VERSION "PMZ_HSCAN"

NS_ :

BS_:

BU_: BCM_Gp BECM CCF_Server EPICD EPICD_E GWM HVAC PCM SGCM TSTR Virtual_Node

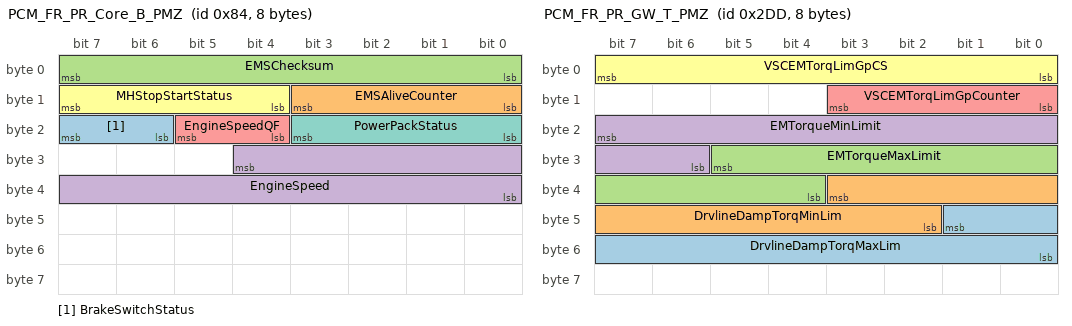
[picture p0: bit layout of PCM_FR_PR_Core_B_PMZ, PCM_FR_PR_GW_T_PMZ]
BO_ 132 PCM_FR_PR_Core_B_PMZ: 8 GWM
 SG_ BrakeSwitchStatus : 23|2@0+ (1,0) [0|3] "" Vector__XXX
 SG_ EMSAliveCounter : 11|4@0+ (1,0) [0|15] "Counter value" Vector__XXX
 SG_ EMSChecksum : 7|8@0+ (1,0) [0|255] "checksum" Vector__XXX
 SG_ EngineSpeed : 28|13@0+ (1,0) [0|8191] "RPM" Vector__XXX
 SG_ EngineSpeedQF : 21|2@0+ (1,0) [0|3] "" Vector__XXX
 SG_ MHStopStartStatus : 15|4@0+ (1,0) [0|15] "" Vector__XXX
 SG_ PowerPackStatus : 19|4@0+ (1,0) [0|15] "" Vector__XXX

BO_ 733 PCM_FR_PR_GW_T_PMZ: 8 GWM
 SG_ DrvlineDampTorqMaxLim : 41|10@0+ (0.1,0) [0|102.3] "Nm"  SGCM
 SG_ DrvlineDampTorqMinLim : 35|10@0+ (0.1,-102.3) [-102.3|1.4211E-014] "Nm"  SGCM
 SG_ EMTorqueMaxLimit : 29|10@0+ (1,0) [0|1021] "Nm"  SGCM
 SG_ EMTorqueMinLimit : 23|10@0+ (1,-1021) [-1021|0] "Nm"  SGCM
 SG_ VSCEMTorqLimGpCounter : 11|4@0+ (1,0) [0|15] "Counter value"  SGCM
 SG_ VSCEMTorqLimGpCS : 7|8@0+ (1,0) [0|255] "checksum"  SGCM

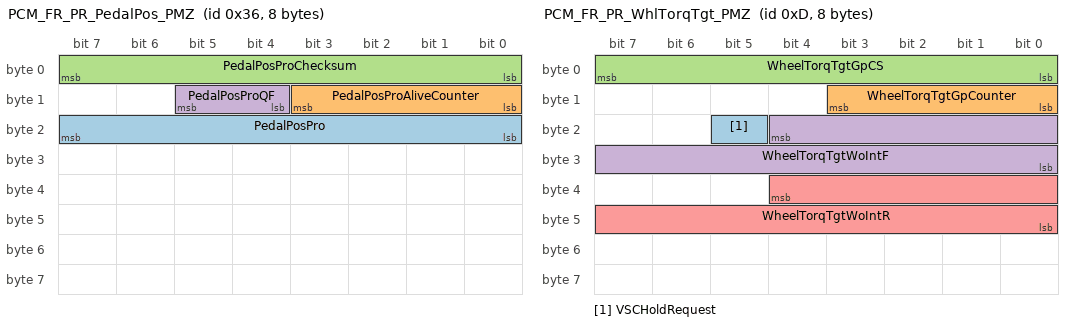
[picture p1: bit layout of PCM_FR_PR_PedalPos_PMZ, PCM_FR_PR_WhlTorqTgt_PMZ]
BO_ 54 PCM_FR_PR_PedalPos_PMZ: 8 GWM
 SG_ PedalPosPro : 23|8@0+ (0.5,0) [0|100] "%"  BECM
 SG_ PedalPosProAliveCounter : 11|4@0+ (1,0) [0|15] "Counter value" Vector__XXX
 SG_ PedalPosProChecksum : 7|8@0+ (1,0) [0|255] "checksum" Vector__XXX
 SG_ PedalPosProQF : 13|2@0+ (1,0) [0|3] "" Vector__XXX

BO_ 13 PCM_FR_PR_WhlTorqTgt_PMZ: 8 GWM
 SG_ VSCHoldRequest : 21|1@0+ (1,0) [0|1] "" Vector__XXX
 SG_ WheelTorqTgtGpCounter : 11|4@0+ (1,0) [0|15] "Counter value" Vector__XXX
 SG_ WheelTorqTgtGpCS : 7|8@0+ (1,0) [0|255] "checksum" Vector__XXX
 SG_ WheelTorqTgtWoIntF : 20|13@0+ (10,-10000) [-10000|71910] "Nm" Vector__XXX
 SG_ WheelTorqTgtWoIntR : 36|13@0+ (10,-10000) [-10000|71910] "Nm" Vector__XXX

BO_ 853 PCM_PMZ_BISGCalibration: 8 PCM
 SG_ BISGCalibrationIDReq : 63|1@0+ (1,0) [0|1] ""  SGCM

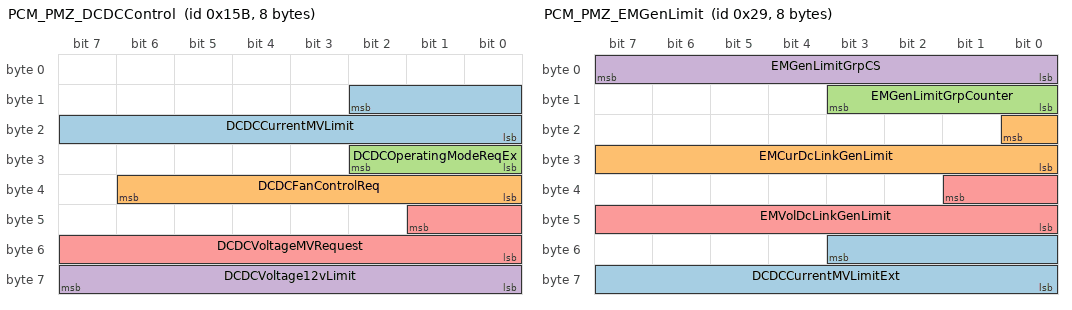
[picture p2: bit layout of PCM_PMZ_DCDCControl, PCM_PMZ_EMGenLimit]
BO_ 347 PCM_PMZ_DCDCControl: 8 PCM
 SG_ DCDCCurrentMVLimit : 10|11@0+ (0.1,-102.35) [-102.35|102.35] "Amps"  EPICD,EPICD_E
 SG_ DCDCFanControlReq : 38|7@0+ (1,0) [0|100] "%"  EPICD,EPICD_E
 SG_ DCDCOperatingModeReqEx : 26|3@0+ (1,0) [0|7] ""  EPICD,EPICD_E,GWM
 SG_ DCDCVoltage12vLimit : 63|8@0+ (0.1,0) [0|25.3] "Volts" Vector__XXX
 SG_ DCDCVoltageMVRequest : 41|10@0+ (0.1,0) [0|102.1] "Volts"  EPICD,EPICD_E

BO_ 41 PCM_PMZ_EMGenLimit: 8 PCM
 SG_ DCDCCurrentMVLimitExt : 51|12@0+ (0.1,-150) [-150|259.5] "Amps"  EPICD_E
 SG_ EMCurDcLinkGenLimit : 16|9@0+ (1,-509) [-509|0] "Amps"  SGCM
 SG_ EMGenLimitGrpCounter : 11|4@0+ (1,0) [0|15] "Counter value"  SGCM
 SG_ EMGenLimitGrpCS : 7|8@0+ (1,0) [0|255] "checksum"  SGCM
 SG_ EMVolDcLinkGenLimit : 33|10@0+ (1,0) [0|1021] "Volts"  SGCM

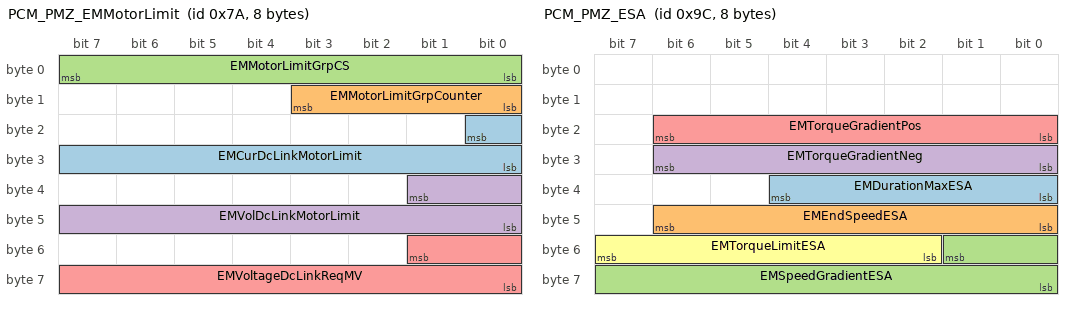
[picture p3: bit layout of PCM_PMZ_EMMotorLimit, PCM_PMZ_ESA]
BO_ 122 PCM_PMZ_EMMotorLimit: 8 PCM
 SG_ EMCurDcLinkMotorLimit : 16|9@0+ (1,0) [0|509] "Amps"  SGCM
 SG_ EMMotorLimitGrpCounter : 11|4@0+ (1,0) [0|15] "Counter value"  SGCM
 SG_ EMMotorLimitGrpCS : 7|8@0+ (1,0) [0|255] "checksum"  SGCM
 SG_ EMVolDcLinkMotorLimit : 33|10@0+ (1,0) [0|1021] "Volts"  SGCM
 SG_ EMVoltageDcLinkReqMV : 49|10@0+ (0.1,0) [0|102.3] "Volts"  SGCM

BO_ 156 PCM_PMZ_ESA: 8 PCM
 SG_ EMDurationMaxESA : 36|5@0+ (0.1,0) [0|3.1] "s"  SGCM
 SG_ EMEndSpeedESA : 46|7@0+ (10,0) [0|1270] "rpm"  SGCM
 SG_ EMSpeedGradientESA : 49|10@0+ (-10,0) [-10230|0] "rpm/s"  SGCM
 SG_ EMTorqueGradientNeg : 30|7@0+ (-10,0) [-1270|0] "Nm/s"  SGCM
 SG_ EMTorqueGradientPos : 22|7@0+ (10,0) [0|1270] "Nm/s"  SGCM
 SG_ EMTorqueLimitESA : 55|6@0+ (-1,0) [-63|0] "Nm"  SGCM

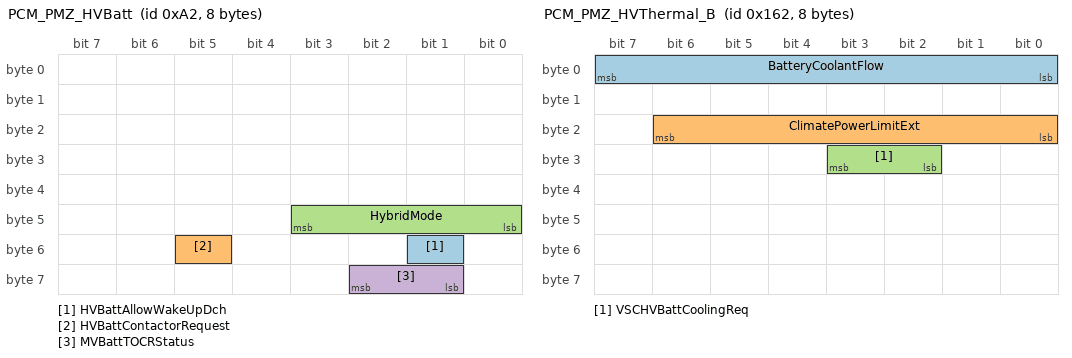
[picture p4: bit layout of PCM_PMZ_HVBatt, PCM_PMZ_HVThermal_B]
BO_ 162 PCM_PMZ_HVBatt: 8 PCM
 SG_ HVBattAllowWakeUpDch : 49|1@0+ (1,0) [0|1] "" Vector__XXX
 SG_ HVBattContactorRequest : 53|1@0+ (1,0) [0|1] ""  BECM,EPICD,EPICD_E
 SG_ HybridMode : 43|4@0+ (1,0) [0|15] ""  BCM_Gp
 SG_ MVBattTOCRStatus : 58|2@0+ (1,0) [0|3] ""  BECM

BO_ 352 PCM_PMZ_HVThermal_A: 8 PCM
 SG_ MVBattFanControlReq : 6|7@0+ (1,0) [0|100] "%"  BECM

BO_ 354 PCM_PMZ_HVThermal_B: 8 PCM
 SG_ BatteryCoolantFlow : 7|8@0+ (0.2,0) [0|51] "l/min"  BECM
 SG_ ClimatePowerLimitExt : 22|7@0+ (0.25,0) [0|31.75] "kW"  HVAC
 SG_ VSCHVBattCoolingReq : 27|2@0+ (1,0) [0|3] ""  HVAC

BO_ 743 PCM_PMZ_MVBattDiagnostics: 8 PCM
 SG_ MVBattCalibrationIDReq : 56|1@0+ (1,0) [0|1] ""  BECM
 SG_ MVBattCalibrationIDReq_UB : 57|1@0+ (1,0) [0|1] ""  BECM

BO_ 304 PCM_PMZ_PR_GW_1: 8 PCM
 SG_ eDriveCoolantLevel : 28|1@0+ (1,0) [0|1] ""  GWM,HVAC

BO_ 356 PCM_PMZ_PumpStatus: 8 PCM
 SG_ HVBattPumpDRReq : 38|7@0+ (1,0) [0|100] "%"  EPICD_E,GWM

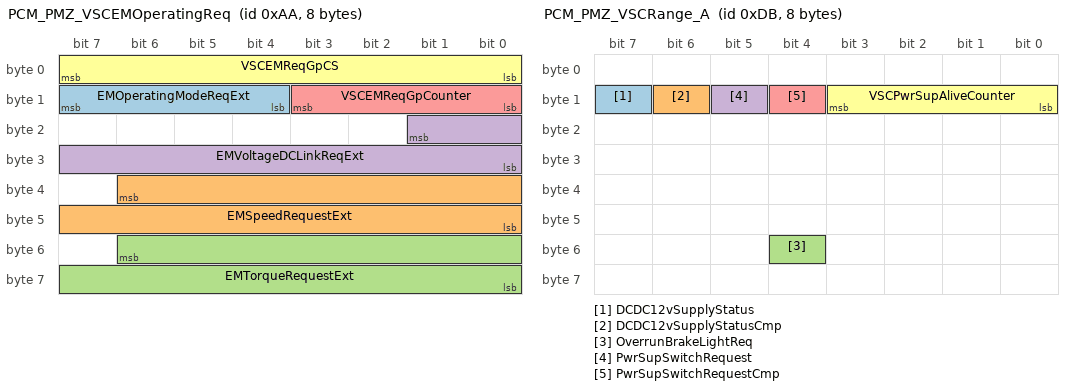
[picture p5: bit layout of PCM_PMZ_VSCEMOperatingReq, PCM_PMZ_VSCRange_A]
BO_ 170 PCM_PMZ_VSCEMOperatingReq: 8 GWM
 SG_ EMOperatingModeReqExt : 15|4@0+ (1,0) [0|15] ""  SGCM
 SG_ EMSpeedRequestExt : 38|15@0+ (1,-16382) [-16382|16383] "rpm"  SGCM
 SG_ EMTorqueRequestExt : 54|15@0+ (0.1,-1638.3) [-1638.3|1638.4] "Nm"  SGCM
 SG_ EMVoltageDCLinkReqExt : 17|10@0+ (1,0) [0|1021] "Volts"  EPICD,EPICD_E,SGCM
 SG_ VSCEMReqGpCounter : 11|4@0+ (1,0) [0|15] "Counter value"  SGCM
 SG_ VSCEMReqGpCS : 7|8@0+ (1,0) [0|255] "checksum"  SGCM

BO_ 219 PCM_PMZ_VSCRange_A: 8 PCM
 SG_ DCDC12vSupplyStatus : 15|1@0+ (1,0) [0|1] ""  GWM
 SG_ DCDC12vSupplyStatusCmp : 14|1@0+ (1,0) [0|1] ""  GWM
 SG_ OverrunBrakeLightReq : 52|1@0+ (1,0) [0|1] ""  BCM_Gp
 SG_ PwrSupSwitchRequest : 13|1@0+ (1,0) [0|1] ""  GWM
 SG_ PwrSupSwitchRequestCmp : 12|1@0+ (1,0) [0|1] ""  GWM
 SG_ VSCPwrSupAliveCounter : 11|4@0+ (1,0) [0|15] "Counter value"  GWM

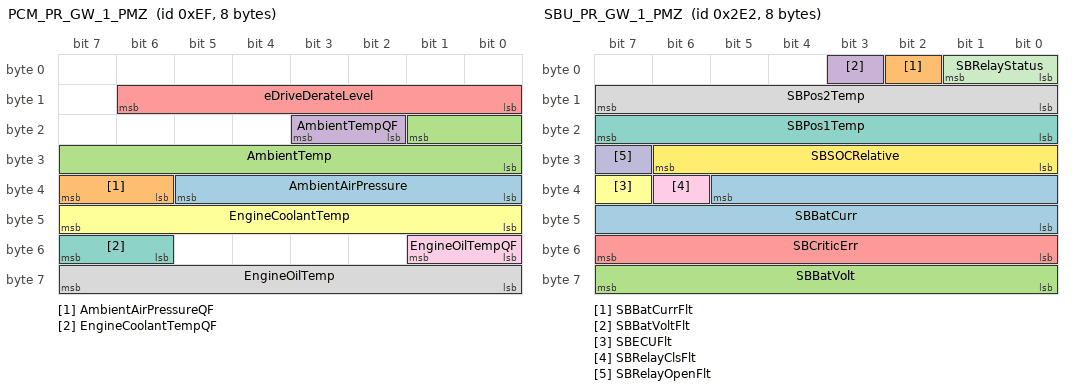
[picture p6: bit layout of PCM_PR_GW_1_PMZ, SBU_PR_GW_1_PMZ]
BO_ 239 PCM_PR_GW_1_PMZ: 8 GWM
 SG_ AmbientAirPressure : 37|6@0+ (10,500) [500|1100] "mBAR" Vector__XXX
 SG_ AmbientAirPressureQF : 39|2@0+ (1,0) [0|3] "" Vector__XXX
 SG_ AmbientTemp : 17|10@0+ (0.25,-128) [-128|127.75] "Degrees C"  EPICD,EPICD_E
 SG_ AmbientTempQF : 19|2@0+ (1,0) [0|3] "" Vector__XXX
 SG_ eDriveDerateLevel : 14|7@0+ (1,0) [0|100] "%" Vector__XXX
 SG_ EngineCoolantTemp : 47|8@0+ (1,-60) [-60|195] "deg C" Vector__XXX
 SG_ EngineCoolantTempQF : 55|2@0+ (1,0) [0|3] "" Vector__XXX
 SG_ EngineOilTemp : 63|8@0+ (1,-60) [-60|195] "deg C" Vector__XXX
 SG_ EngineOilTempQF : 49|2@0+ (1,0) [0|3] "" Vector__XXX

BO_ 1442 PMZ_CAN_NodeBECM_NM: 8 BECM
 SG_ PMZ_CAN_BECM_NM_PDU : 7|64@0+ (1,0) [0|0] "" Vector__XXX

BO_ 1438 PMZ_CAN_NodeGWM_NM: 8 GWM
 SG_ PMZ_CAN_GWM_NM_PDU : 7|64@0+ (1,0) [0|0] ""  BECM,EPICD_E,HVAC,PCM,SGCM,Virtual_Node

BO_ 1310 PMZ_CAN_NodeGWM_OSEK_NM: 8 GWM
 SG_ PMZ_CAN_GWM_OSEK_NM_Pdu : 7|64@0+ (1,0) [0|0] ""  Virtual_Node

BO_ 1411 PMZ_CAN_NodeHVAC_NM: 8 HVAC
 SG_ PMZ_CAN_HVAC_NM_PDU : 7|64@0+ (1,0) [0|0] ""  GWM

BO_ 1429 PMZ_CAN_NodePCM_NM: 8 PCM
 SG_ PMZ_CAN_PCM_NM_PDU : 7|64@0+ (1,0) [0|0] "" Vector__XXX

BO_ 1428 PMZ_CAN_NodeSGCM_NM: 8 SGCM
 SG_ PMZ_CAN_SGCM_NM_PDU : 7|64@0+ (1,0) [0|0] "" Vector__XXX

BO_ 1535 PMZ_CAN_NodeVirtual_NM: 8 Virtual_Node
 SG_ PMZ_CAN_Virtual_NM_PDU : 7|64@0+ (1,0) [0|0] "" Vector__XXX

BO_ 1407 PMZ_CAN_NodeVirtual_OSEK_NM: 8 Virtual_Node
 SG_ PMZ_CAN_Virtual_OSEK_NM_Pdu : 7|64@0+ (1,0) [0|0] ""  GWM

BO_ 562 PNC_TCUtoBMCM1: 8 GWM
 SG_ PNC_TCUtoBMCM1_Pdu : 7|64@0+ (1,0) [0|0] "" Vector__XXX

BO_ 712 PNC_TCUtoBMCM10: 8 GWM
 SG_ PNC_TCUtoBMCM10_Pdu : 7|64@0+ (1,0) [0|0] "" Vector__XXX

BO_ 707 PNC_TCUtoBMCM11: 8 GWM
 SG_ PNC_TCUtoBMCM11_Pdu : 7|64@0+ (1,0) [0|0] "" Vector__XXX

BO_ 708 PNC_TCUtoBMCM12: 8 GWM
 SG_ PNC_TCUtoBMCM12_Pdu : 7|64@0+ (1,0) [0|0] "" Vector__XXX

BO_ 711 PNC_TCUtoBMCM13: 8 GWM
 SG_ PNC_TCUtoBMCM13_Pdu : 7|64@0+ (1,0) [0|0] "" Vector__XXX

BO_ 565 PNC_TCUtoBMCM2: 8 GWM
 SG_ PNC_TCUtoBMCM2_Pdu : 7|64@0+ (1,0) [0|0] "" Vector__XXX

BO_ 569 PNC_TCUtoBMCM3: 8 GWM
 SG_ PNC_TCUtoBMCM3_Pdu : 7|64@0+ (1,0) [0|0] "" Vector__XXX

BO_ 573 PNC_TCUtoBMCM4: 8 GWM
 SG_ PNC_TCUtoBMCM4_Pdu : 7|64@0+ (1,0) [0|0] "" Vector__XXX

BO_ 579 PNC_TCUtoBMCM5: 8 GWM
 SG_ PNC_TCUtoBMCM5_Pdu : 7|64@0+ (1,0) [0|0] "" Vector__XXX

BO_ 594 PNC_TCUtoBMCM6: 8 GWM
 SG_ PNC_TCUtoBMCM6_Pdu : 7|64@0+ (1,0) [0|0] "" Vector__XXX

BO_ 709 PNC_TCUtoBMCM8: 8 GWM
 SG_ PNC_TCUtoBMCM8_Pdu : 7|64@0+ (1,0) [0|0] "" Vector__XXX

BO_ 710 PNC_TCUtoBMCM9: 8 GWM
 SG_ PNC_TCUtoBMCM9_Pdu : 7|64@0+ (1,0) [0|0] "" Vector__XXX

BO_ 191 RCM_FR_PR_GW_1_PMZ: 8 GWM
 SG_ CrashAirbagStatus : 63|2@0+ (1,0) [0|3] "" Vector__XXX
 SG_ CrashOccClassStatus : 61|2@0+ (1,0) [0|3] "" Vector__XXX
 SG_ CrashPACOSSwitchState : 59|2@0+ (1,0) [0|3] "" Vector__XXX
 SG_ CrashPretensionerStat : 57|2@0+ (1,0) [0|3] "" Vector__XXX
 SG_ CrashSeatBeltBcklState : 55|2@0+ (1,0) [0|3] "" Vector__XXX
 SG_ CrashSeverityClass : 53|2@0+ (1,0) [0|3] "" Vector__XXX
 SG_ CrashSideAirbagStatus : 51|2@0+ (1,0) [0|3] "" Vector__XXX
 SG_ CrashStatusPIE : 42|1@0+ (1,0) [0|1] "" Vector__XXX
 SG_ CrashStatusRCM : 43|1@0+ (1,0) [0|1] ""  BECM,EPICD,EPICD_E,SGCM
 SG_ CrashTypeFront : 49|1@0+ (1,0) [0|1] "" Vector__XXX
 SG_ CrashTypeRear : 48|1@0+ (1,0) [0|1] "" Vector__XXX
 SG_ CrashTypeRoll : 40|1@0+ (1,0) [0|1] "" Vector__XXX
 SG_ CrashTypeSide : 41|1@0+ (1,0) [0|1] "" Vector__XXX
 SG_ DrivSeatBeltBcklError : 30|1@0+ (1,0) [0|1] "" Vector__XXX
 SG_ DrivSeatBeltBcklState : 31|1@0+ (1,0) [0|1] "" Vector__XXX
 SG_ DrivSeatPositionError : 47|1@0+ (1,0) [0|1] "" Vector__XXX
 SG_ DrivSeatPositionStatus : 46|1@0+ (1,0) [0|1] "" Vector__XXX
 SG_ KeepNetInAfterRunRCM : 44|1@0+ (1,0) [0|1] "" Vector__XXX
 SG_ PassSeatBeltBcklError : 28|1@0+ (1,0) [0|1] "" Vector__XXX
 SG_ PassSeatBeltBcklState : 29|1@0+ (1,0) [0|1] "" Vector__XXX
 SG_ PassSeatPositionStatus : 45|1@0+ (1,0) [0|1] "" Vector__XXX
 SG_ SeatBeltBcklAC : 11|4@0+ (1,0) [0|15] "Counter value" Vector__XXX
 SG_ SeatBeltBcklCS : 7|8@0+ (1,0) [0|255] "checksum" Vector__XXX
 SG_ TriggerEventRCM : 16|1@0+ (1,0) [0|1] "" Vector__XXX
 SG_ VerticalAcceleration : 27|12@0+ (0.02,-40.96) [-40.96|40.92] "m/s/s" Vector__XXX

BO_ 738 SBU_PR_GW_1_PMZ: 8 GWM
 SG_ SBBatCurr : 37|14@0+ (0.0625,-511) [-511|512.9375] "A" Vector__XXX
 SG_ SBBatCurrFlt : 2|1@0+ (1,0) [0|1] "" Vector__XXX
 SG_ SBBatVolt : 63|8@0+ (0.1,0) [0|25.5] "V"  HVAC
 SG_ SBBatVoltFlt : 3|1@0+ (1,0) [0|1] "" Vector__XXX
 SG_ SBCriticErr : 55|8@0+ (1,0) [0|255] "" Vector__XXX
 SG_ SBECUFlt : 39|1@0+ (1,0) [0|1] "" Vector__XXX
 SG_ SBPos1Temp : 23|8@0+ (1,-40) [-40|215] "degC" Vector__XXX
 SG_ SBPos2Temp : 15|8@0+ (1,-40) [-40|215] "degC" Vector__XXX
 SG_ SBRelayClsFlt : 38|1@0+ (1,0) [0|1] "" Vector__XXX
 SG_ SBRelayOpenFlt : 31|1@0+ (1,0) [0|1] "" Vector__XXX
 SG_ SBRelayStatus : 1|2@0+ (1,0) [0|3] "" Vector__XXX
 SG_ SBSOCRelative : 30|7@0+ (1,0) [0|100] "%" Vector__XXX

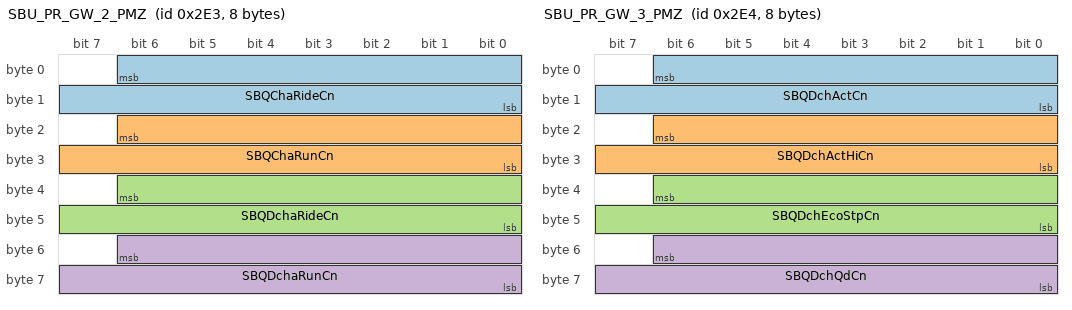
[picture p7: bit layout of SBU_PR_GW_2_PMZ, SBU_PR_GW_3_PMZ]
BO_ 739 SBU_PR_GW_2_PMZ: 8 GWM
 SG_ SBQChaRideCn : 6|15@0+ (0.0625,0) [0|2047.9375] "Cn" Vector__XXX
 SG_ SBQChaRunCn : 22|15@0+ (0.0625,0) [0|2047.9375] "Cn" Vector__XXX
 SG_ SBQDchaRideCn : 38|15@0+ (0.0625,0) [0|2047.9375] "Cn" Vector__XXX
 SG_ SBQDchaRunCn : 54|15@0+ (0.0625,0) [0|2047.9375] "Cn" Vector__XXX

BO_ 740 SBU_PR_GW_3_PMZ: 8 GWM
 SG_ SBQDchActCn : 6|15@0+ (0.0625,0) [0|2047.9375] "Cn" Vector__XXX
 SG_ SBQDchActHiCn : 22|15@0+ (0.0625,0) [0|2047.9375] "Cn" Vector__XXX
 SG_ SBQDchEcoStpCn : 38|15@0+ (0.0625,0) [0|2047.9375] "Cn" Vector__XXX
 SG_ SBQDchQdCn : 54|15@0+ (0.01,0) [0|327.67] "Cn" Vector__XXX

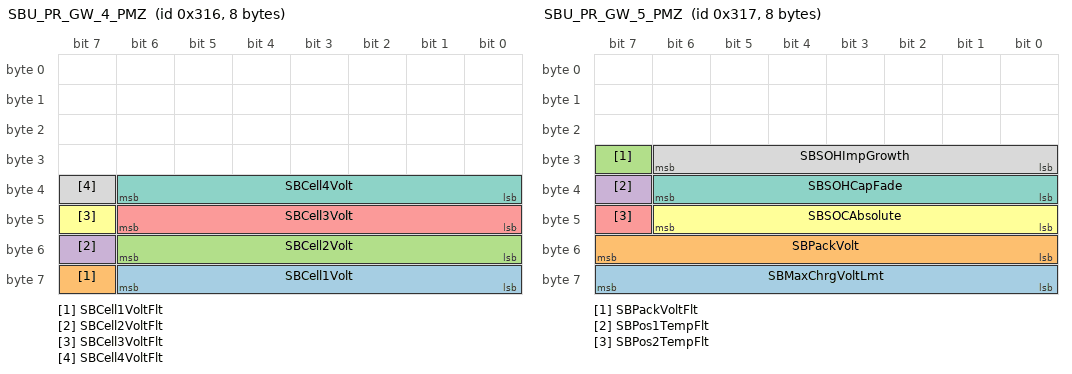
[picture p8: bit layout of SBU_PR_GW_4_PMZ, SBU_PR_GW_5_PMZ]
BO_ 790 SBU_PR_GW_4_PMZ: 8 GWM
 SG_ SBCell1Volt : 62|7@0+ (0.05,0) [0|6.35] "V" Vector__XXX
 SG_ SBCell1VoltFlt : 63|1@0+ (1,0) [0|1] "" Vector__XXX
 SG_ SBCell2Volt : 54|7@0+ (0.05,0) [0|6.35] "V" Vector__XXX
 SG_ SBCell2VoltFlt : 55|1@0+ (1,0) [0|1] "" Vector__XXX
 SG_ SBCell3Volt : 46|7@0+ (0.05,0) [0|6.35] "V" Vector__XXX
 SG_ SBCell3VoltFlt : 47|1@0+ (1,0) [0|1] "" Vector__XXX
 SG_ SBCell4Volt : 38|7@0+ (0.05,0) [0|6.35] "V" Vector__XXX
 SG_ SBCell4VoltFlt : 39|1@0+ (1,0) [0|1] "" Vector__XXX

BO_ 791 SBU_PR_GW_5_PMZ: 8 GWM
 SG_ SBMaxChrgVoltLmt : 63|8@0+ (0.1,0) [0|25.5] "V" Vector__XXX
 SG_ SBPackVolt : 55|8@0+ (0.1,0) [0|25.5] "V" Vector__XXX
 SG_ SBPackVoltFlt : 31|1@0+ (1,0) [0|1] "" Vector__XXX
 SG_ SBPos1TempFlt : 39|1@0+ (1,0) [0|1] "" Vector__XXX
 SG_ SBPos2TempFlt : 47|1@0+ (1,0) [0|1] "" Vector__XXX
 SG_ SBSOCAbsolute : 46|7@0+ (1,0) [0|100] "%"  HVAC
 SG_ SBSOHCapFade : 38|7@0+ (1,0) [0|100] "%" Vector__XXX
 SG_ SBSOHImpGrowth : 30|7@0+ (1,0) [0|100] "%" Vector__XXX

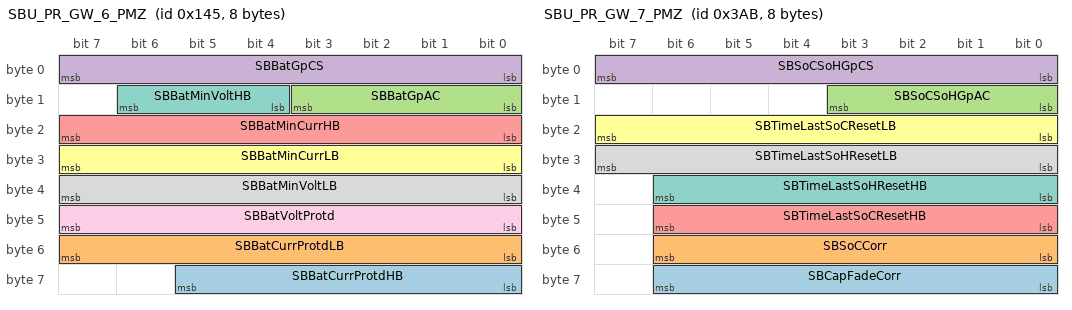
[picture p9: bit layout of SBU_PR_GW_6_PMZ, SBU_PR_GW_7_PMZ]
BO_ 325 SBU_PR_GW_6_PMZ: 8 GWM
 SG_ SBBatCurrProtdHB : 61|6@0+ (1,0) [0|63] "" Vector__XXX
 SG_ SBBatCurrProtdLB : 55|8@0+ (1,0) [0|255] "" Vector__XXX
 SG_ SBBatGpAC : 11|4@0+ (1,0) [0|15] "Counter value" Vector__XXX
 SG_ SBBatGpCS : 7|8@0+ (1,0) [0|255] "checksum" Vector__XXX
 SG_ SBBatMinCurrHB : 23|8@0+ (1,0) [0|255] "" Vector__XXX
 SG_ SBBatMinCurrLB : 31|8@0+ (1,0) [0|255] "" Vector__XXX
 SG_ SBBatMinVoltHB : 14|3@0+ (1,0) [0|7] "" Vector__XXX
 SG_ SBBatMinVoltLB : 39|8@0+ (1,0) [0|255] "" Vector__XXX
 SG_ SBBatVoltProtd : 47|8@0+ (0.1,0) [0|25.5] "V" Vector__XXX

BO_ 939 SBU_PR_GW_7_PMZ: 8 GWM
 SG_ SBCapFadeCorr : 62|7@0+ (1,0) [0|100] "%" Vector__XXX
 SG_ SBSoCCorr : 54|7@0+ (1,0) [0|100] "%" Vector__XXX
 SG_ SBSoCSoHGpAC : 11|4@0+ (1,0) [0|15] "Counter value" Vector__XXX
 SG_ SBSoCSoHGpCS : 7|8@0+ (1,0) [0|255] "checksum" Vector__XXX
 SG_ SBTimeLastSoCResetHB : 46|7@0+ (1,0) [0|127] "" Vector__XXX
 SG_ SBTimeLastSoCResetLB : 23|8@0+ (1,0) [0|255] "" Vector__XXX
 SG_ SBTimeLastSoHResetHB : 38|7@0+ (1,0) [0|127] "" Vector__XXX
 SG_ SBTimeLastSoHResetLB : 31|8@0+ (1,0) [0|255] "" Vector__XXX

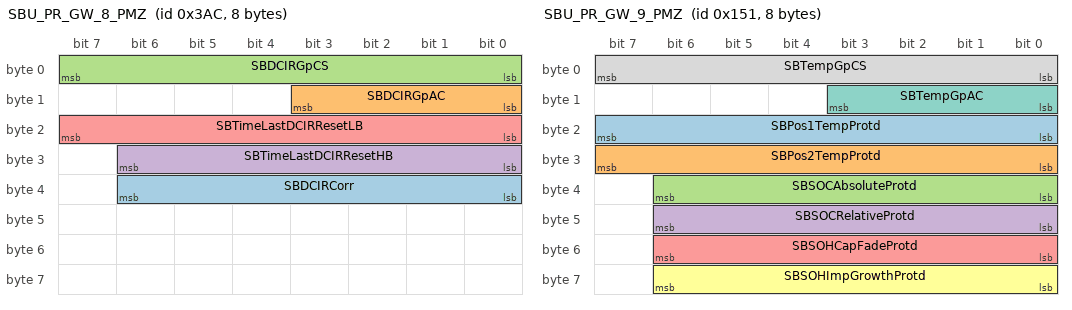
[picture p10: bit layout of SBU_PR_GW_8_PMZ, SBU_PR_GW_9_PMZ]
BO_ 940 SBU_PR_GW_8_PMZ: 8 GWM
 SG_ SBDCIRCorr : 38|7@0+ (1,0) [0|100] "%" Vector__XXX
 SG_ SBDCIRGpAC : 11|4@0+ (1,0) [0|15] "Counter value" Vector__XXX
 SG_ SBDCIRGpCS : 7|8@0+ (1,0) [0|255] "checksum" Vector__XXX
 SG_ SBTimeLastDCIRResetHB : 30|7@0+ (1,0) [0|127] "" Vector__XXX
 SG_ SBTimeLastDCIRResetLB : 23|8@0+ (1,0) [0|255] "" Vector__XXX

BO_ 337 SBU_PR_GW_9_PMZ: 8 GWM
 SG_ SBPos1TempProtd : 23|8@0+ (1,-40) [-40|215] "degC" Vector__XXX
 SG_ SBPos2TempProtd : 31|8@0+ (1,-40) [-40|215] "degC" Vector__XXX
 SG_ SBSOCAbsoluteProtd : 38|7@0+ (1,0) [0|100] "%" Vector__XXX
 SG_ SBSOCRelativeProtd : 46|7@0+ (1,0) [0|100] "%" Vector__XXX
 SG_ SBSOHCapFadeProtd : 54|7@0+ (1,0) [0|100] "%" Vector__XXX
 SG_ SBSOHImpGrowthProtd : 62|7@0+ (1,0) [0|100] "%" Vector__XXX
 SG_ SBTempGpAC : 11|4@0+ (1,0) [0|15] "Counter value" Vector__XXX
 SG_ SBTempGpCS : 7|8@0+ (1,0) [0|255] "checksum" Vector__XXX

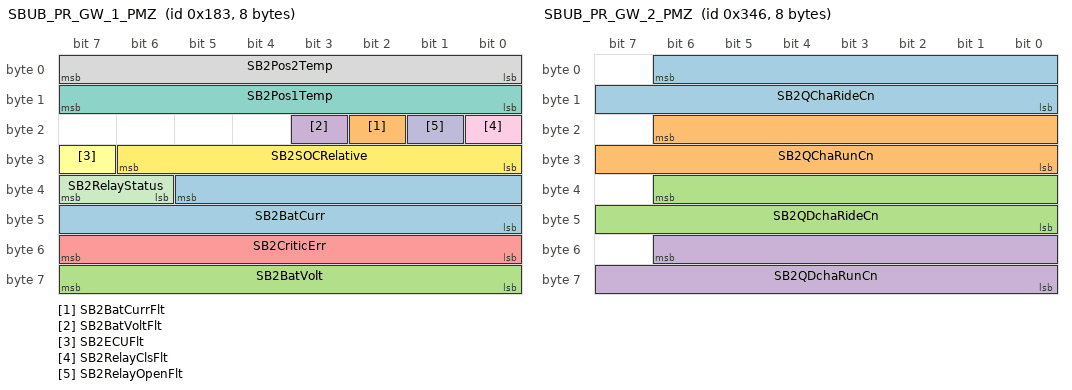
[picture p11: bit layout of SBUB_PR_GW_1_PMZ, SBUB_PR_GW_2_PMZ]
BO_ 387 SBUB_PR_GW_1_PMZ: 8 GWM
 SG_ SB2BatCurr : 37|14@0+ (0.0625,-511) [-511|512.9375] "A" Vector__XXX
 SG_ SB2BatCurrFlt : 18|1@0+ (1,0) [0|1] "" Vector__XXX
 SG_ SB2BatVolt : 63|8@0+ (0.1,0) [0|25.5] "V" Vector__XXX
 SG_ SB2BatVoltFlt : 19|1@0+ (1,0) [0|1] "" Vector__XXX
 SG_ SB2CriticErr : 55|8@0+ (1,0) [0|255] "" Vector__XXX
 SG_ SB2ECUFlt : 31|1@0+ (1,0) [0|1] "" Vector__XXX
 SG_ SB2Pos1Temp : 15|8@0+ (1,-40) [-40|215] "degC" Vector__XXX
 SG_ SB2Pos2Temp : 7|8@0+ (1,-40) [-40|215] "degC" Vector__XXX
 SG_ SB2RelayClsFlt : 16|1@0+ (1,0) [0|1] "" Vector__XXX
 SG_ SB2RelayOpenFlt : 17|1@0+ (1,0) [0|1] "" Vector__XXX
 SG_ SB2RelayStatus : 39|2@0+ (1,0) [0|3] "" Vector__XXX
 SG_ SB2SOCRelative : 30|7@0+ (1,0) [0|100] "%" Vector__XXX

BO_ 838 SBUB_PR_GW_2_PMZ: 8 GWM
 SG_ SB2QChaRideCn : 6|15@0+ (0.0625,0) [0|2047.9375] "Cn" Vector__XXX
 SG_ SB2QChaRunCn : 22|15@0+ (0.0625,0) [0|2047.9375] "Cn" Vector__XXX
 SG_ SB2QDchaRideCn : 38|15@0+ (0.0625,0) [0|2047.9375] "Cn" Vector__XXX
 SG_ SB2QDchaRunCn : 54|15@0+ (0.0625,0) [0|2047.9375] "Cn" Vector__XXX

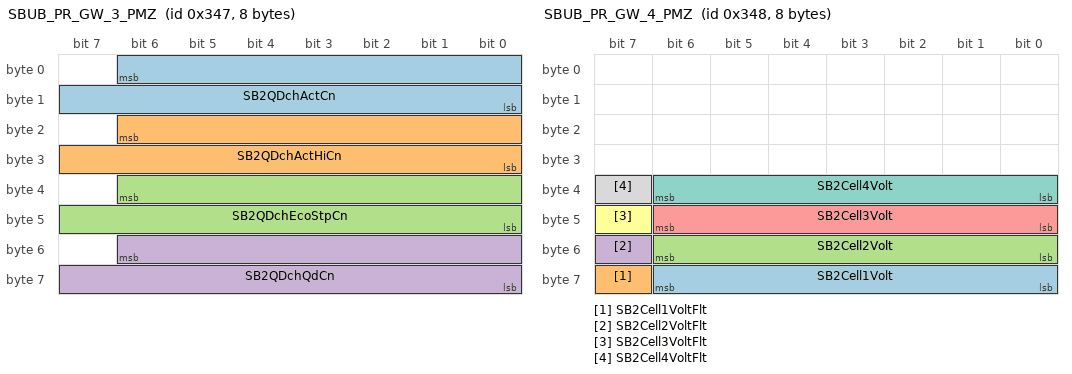
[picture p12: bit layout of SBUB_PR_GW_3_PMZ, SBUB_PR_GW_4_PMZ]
BO_ 839 SBUB_PR_GW_3_PMZ: 8 GWM
 SG_ SB2QDchActCn : 6|15@0+ (0.0625,0) [0|2047.9375] "Cn" Vector__XXX
 SG_ SB2QDchActHiCn : 22|15@0+ (0.0625,0) [0|2047.9375] "Cn" Vector__XXX
 SG_ SB2QDchEcoStpCn : 38|15@0+ (0.0625,0) [0|2047.9375] "Cn" Vector__XXX
 SG_ SB2QDchQdCn : 54|15@0+ (1,0) [0|32767] "" Vector__XXX

BO_ 840 SBUB_PR_GW_4_PMZ: 8 GWM
 SG_ SB2Cell1Volt : 62|7@0+ (0.05,0) [0|6.35] "V" Vector__XXX
 SG_ SB2Cell1VoltFlt : 63|1@0+ (1,0) [0|1] "" Vector__XXX
 SG_ SB2Cell2Volt : 54|7@0+ (0.05,0) [0|6.35] "V" Vector__XXX
 SG_ SB2Cell2VoltFlt : 55|1@0+ (1,0) [0|1] "" Vector__XXX
 SG_ SB2Cell3Volt : 46|7@0+ (0.05,0) [0|6.35] "V" Vector__XXX
 SG_ SB2Cell3VoltFlt : 47|1@0+ (1,0) [0|1] "" Vector__XXX
 SG_ SB2Cell4Volt : 38|7@0+ (0.05,0) [0|6.35] "V" Vector__XXX
 SG_ SB2Cell4VoltFlt : 39|1@0+ (1,0) [0|1] "" Vector__XXX

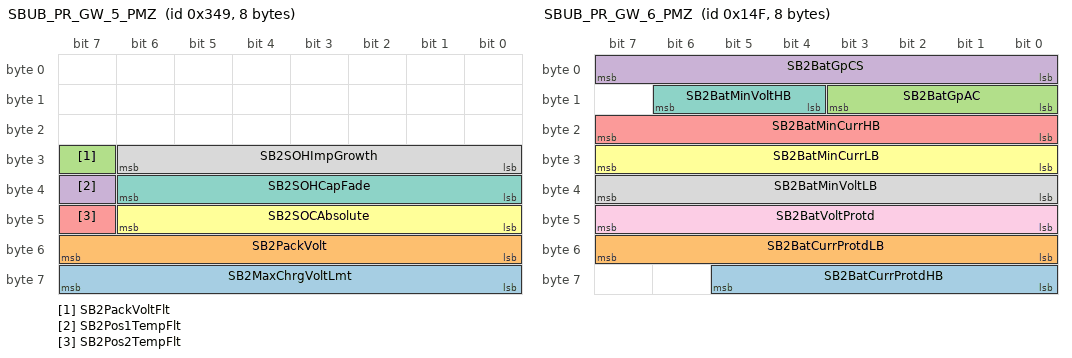
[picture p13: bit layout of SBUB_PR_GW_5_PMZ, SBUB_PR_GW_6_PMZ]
BO_ 841 SBUB_PR_GW_5_PMZ: 8 GWM
 SG_ SB2MaxChrgVoltLmt : 63|8@0+ (0.1,0) [0|25.5] "V" Vector__XXX
 SG_ SB2PackVolt : 55|8@0+ (0.1,0) [0|25.5] "V" Vector__XXX
 SG_ SB2PackVoltFlt : 31|1@0+ (1,0) [0|1] "" Vector__XXX
 SG_ SB2Pos1TempFlt : 39|1@0+ (1,0) [0|1] "" Vector__XXX
 SG_ SB2Pos2TempFlt : 47|1@0+ (1,0) [0|1] "" Vector__XXX
 SG_ SB2SOCAbsolute : 46|7@0+ (1,0) [0|100] "%" Vector__XXX
 SG_ SB2SOHCapFade : 38|7@0+ (1,0) [0|100] "%" Vector__XXX
 SG_ SB2SOHImpGrowth : 30|7@0+ (1,0) [0|100] "%" Vector__XXX

BO_ 335 SBUB_PR_GW_6_PMZ: 8 GWM
 SG_ SB2BatCurrProtdHB : 61|6@0+ (1,0) [0|63] "" Vector__XXX
 SG_ SB2BatCurrProtdLB : 55|8@0+ (1,0) [0|255] "" Vector__XXX
 SG_ SB2BatGpAC : 11|4@0+ (1,0) [0|15] "Counter value" Vector__XXX
 SG_ SB2BatGpCS : 7|8@0+ (1,0) [0|255] "checksum" Vector__XXX
 SG_ SB2BatMinCurrHB : 23|8@0+ (1,0) [0|255] "" Vector__XXX
 SG_ SB2BatMinCurrLB : 31|8@0+ (1,0) [0|255] "" Vector__XXX
 SG_ SB2BatMinVoltHB : 14|3@0+ (1,0) [0|7] "" Vector__XXX
 SG_ SB2BatMinVoltLB : 39|8@0+ (1,0) [0|255] "" Vector__XXX
 SG_ SB2BatVoltProtd : 47|8@0+ (0.1,0) [0|25.5] "V" Vector__XXX

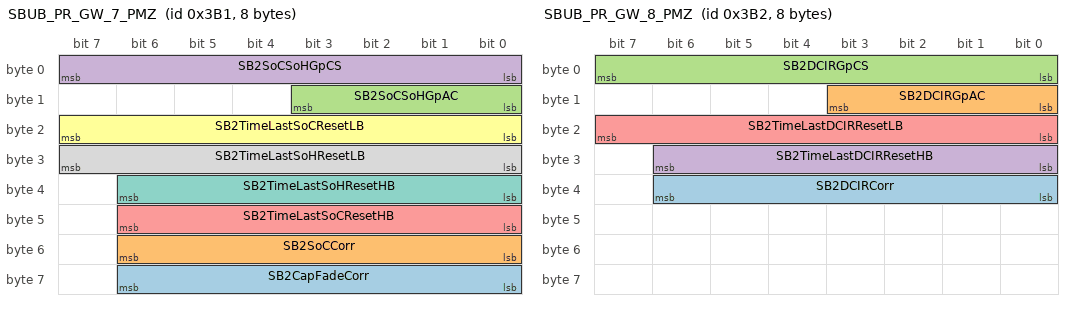
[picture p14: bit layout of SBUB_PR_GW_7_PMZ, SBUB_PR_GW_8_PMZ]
BO_ 945 SBUB_PR_GW_7_PMZ: 8 GWM
 SG_ SB2CapFadeCorr : 62|7@0+ (1,0) [0|100] "%" Vector__XXX
 SG_ SB2SoCCorr : 54|7@0+ (1,0) [0|100] "%" Vector__XXX
 SG_ SB2SoCSoHGpAC : 11|4@0+ (1,0) [0|15] "Counter value" Vector__XXX
 SG_ SB2SoCSoHGpCS : 7|8@0+ (1,0) [0|255] "checksum" Vector__XXX
 SG_ SB2TimeLastSoCResetHB : 46|7@0+ (1,0) [0|127] "" Vector__XXX
 SG_ SB2TimeLastSoCResetLB : 23|8@0+ (1,0) [0|255] "" Vector__XXX
 SG_ SB2TimeLastSoHResetHB : 38|7@0+ (1,0) [0|127] "" Vector__XXX
 SG_ SB2TimeLastSoHResetLB : 31|8@0+ (1,0) [0|255] "" Vector__XXX

BO_ 946 SBUB_PR_GW_8_PMZ: 8 GWM
 SG_ SB2DCIRCorr : 38|7@0+ (1,0) [0|100] "%" Vector__XXX
 SG_ SB2DCIRGpAC : 11|4@0+ (1,0) [0|15] "Counter value" Vector__XXX
 SG_ SB2DCIRGpCS : 7|8@0+ (1,0) [0|255] "checksum" Vector__XXX
 SG_ SB2TimeLastDCIRResetHB : 30|7@0+ (1,0) [0|127] "" Vector__XXX
 SG_ SB2TimeLastDCIRResetLB : 23|8@0+ (1,0) [0|255] "" Vector__XXX

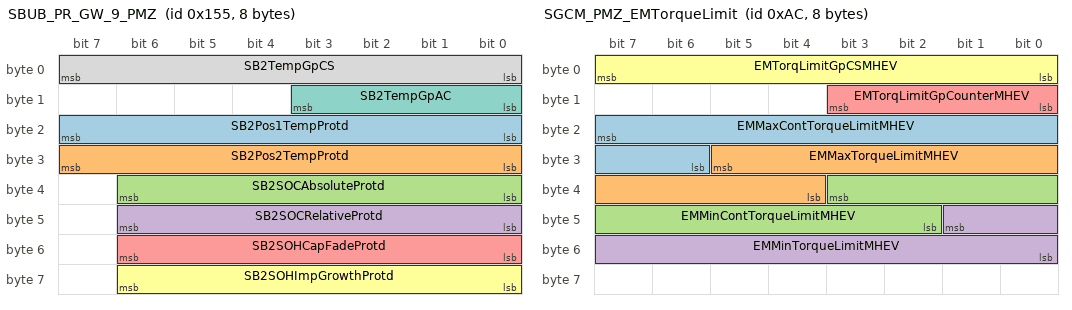
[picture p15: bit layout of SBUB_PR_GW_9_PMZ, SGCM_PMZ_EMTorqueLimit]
BO_ 341 SBUB_PR_GW_9_PMZ: 8 GWM
 SG_ SB2Pos1TempProtd : 23|8@0+ (1,-40) [-40|215] "degC" Vector__XXX
 SG_ SB2Pos2TempProtd : 31|8@0+ (1,-40) [-40|215] "degC" Vector__XXX
 SG_ SB2SOCAbsoluteProtd : 38|7@0+ (1,0) [0|100] "%" Vector__XXX
 SG_ SB2SOCRelativeProtd : 46|7@0+ (1,0) [0|100] "%" Vector__XXX
 SG_ SB2SOHCapFadeProtd : 54|7@0+ (1,0) [0|100] "%" Vector__XXX
 SG_ SB2SOHImpGrowthProtd : 62|7@0+ (1,0) [0|100] "%" Vector__XXX
 SG_ SB2TempGpAC : 11|4@0+ (1,0) [0|15] "Counter value" Vector__XXX
 SG_ SB2TempGpCS : 7|8@0+ (1,0) [0|255] "checksum" Vector__XXX

BO_ 854 SGCM_PMZ_BISGCalibration_A: 8 SGCM
 SG_ BISGCalibrationID01 : 15|56@0+ (1,0) [0|7.20575940379279E+016] ""  PCM

BO_ 855 SGCM_PMZ_BISGCalibration_B: 8 SGCM
 SG_ BISGCalibrationID02 : 15|56@0+ (1,0) [0|7.20575940379279E+016] ""  PCM

BO_ 856 SGCM_PMZ_BISGCalibration_C: 8 SGCM
 SG_ BISGCalibVerifNumber : 7|32@0+ (1,0) [0|4294967295] ""  PCM
 SG_ BISGDiagnostic01 : 39|32@0+ (1,0) [0|4294967295] ""  PCM

BO_ 172 SGCM_PMZ_EMTorqueLimit: 8 SGCM
 SG_ EMMaxContTorqueLimitMHEV : 23|10@0+ (1,0) [0|1023] "Nm"  PCM
 SG_ EMMaxTorqueLimitMHEV : 29|10@0+ (1,0) [0|1023] "Nm"  PCM
 SG_ EMMinContTorqueLimitMHEV : 35|10@0+ (1,-1023) [-1023|0] "Nm"  PCM
 SG_ EMMinTorqueLimitMHEV : 41|10@0+ (1,-1023) [-1023|0] "Nm"  PCM
 SG_ EMTorqLimitGpCounterMHEV : 11|4@0+ (1,0) [0|15] "Counter value"  PCM
 SG_ EMTorqLimitGpCSMHEV : 7|8@0+ (1,0) [0|255] "checksum"  PCM

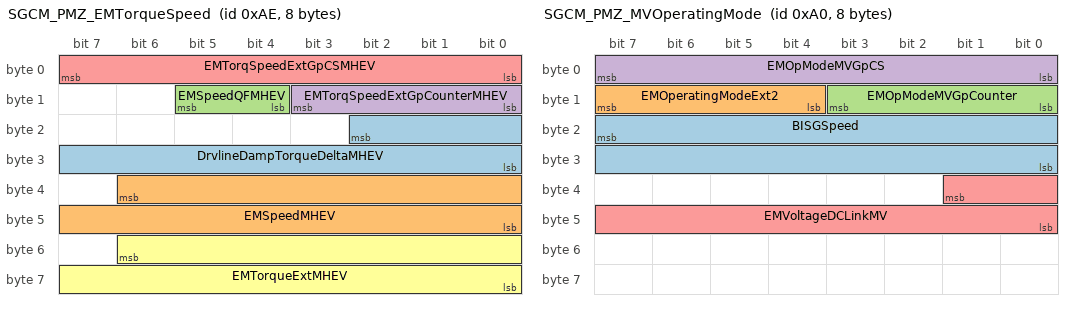
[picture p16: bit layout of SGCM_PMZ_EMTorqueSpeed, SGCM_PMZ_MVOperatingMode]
BO_ 174 SGCM_PMZ_EMTorqueSpeed: 8 SGCM
 SG_ DrvlineDampTorqueDeltaMHEV : 18|11@0+ (0.1,-102.3) [-102.3|102.4] "Nm"  GWM,PCM
 SG_ EMSpeedMHEV : 38|15@0+ (1,-16382) [-16382|16383] "RPM"  GWM,PCM
 SG_ EMSpeedQFMHEV : 13|2@0+ (1,0) [0|3] ""  GWM,PCM
 SG_ EMTorqSpeedExtGpCounterMHEV : 11|4@0+ (1,0) [0|15] "Counter value"  GWM,PCM
 SG_ EMTorqSpeedExtGpCSMHEV : 7|8@0+ (1,0) [0|255] "checksum"  GWM,PCM
 SG_ EMTorqueExtMHEV : 54|15@0+ (0.1,-1638.3) [-1638.3|1638.4] "Nm"  GWM,PCM

BO_ 160 SGCM_PMZ_MVOperatingMode: 8 SGCM
 SG_ BISGSpeed : 23|16@0+ (1,-32767) [-32767|32768] "RPM"  BECM,GWM,PCM
 SG_ EMOperatingModeExt2 : 15|4@0+ (1,0) [0|15] ""  BECM,GWM,PCM
 SG_ EMOpModeMVGpCounter : 11|4@0+ (1,0) [0|15] "Counter value"  BECM,GWM,PCM
 SG_ EMOpModeMVGpCS : 7|8@0+ (1,0) [0|255] "checksum"  BECM,GWM,PCM
 SG_ EMVoltageDCLinkMV : 33|10@0+ (0.1,0) [0|102.3] "Volts"  BECM,GWM,PCM

BO_ 275 SGCM_PMZ_MVOperatingMode_B: 8 SGCM
 SG_ EMVolDCLinkMaxLimitMV : 63|8@0+ (0.25,0) [0|63.75] "Volts"  PCM
 SG_ EMVolDCLinkMinLimitMV : 55|8@0+ (0.25,0) [0|63.75] "Volts"  PCM

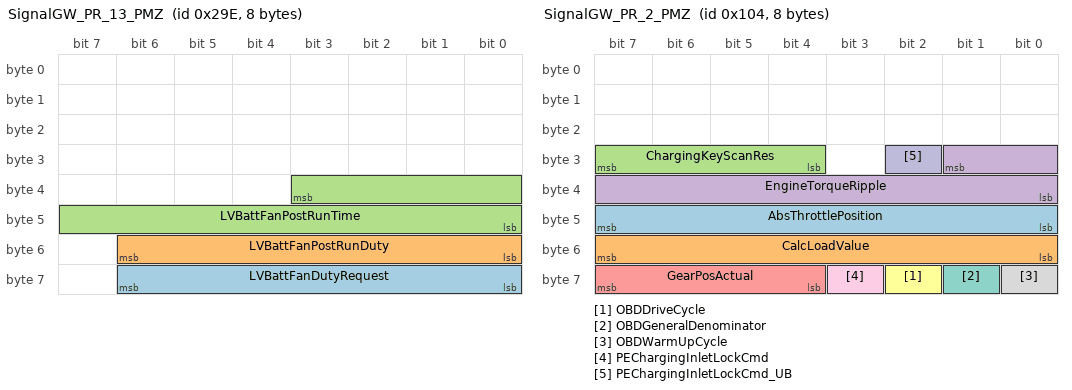
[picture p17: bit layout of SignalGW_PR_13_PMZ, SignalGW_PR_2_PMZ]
BO_ 670 SignalGW_PR_13_PMZ: 8 GWM
 SG_ LVBattFanDutyRequest : 62|7@0+ (1,0) [0|100] "%"  BCM_Gp
 SG_ LVBattFanPostRunDuty : 54|7@0+ (1,0) [0|100] "%"  BCM_Gp
 SG_ LVBattFanPostRunTime : 35|12@0+ (1,0) [0|3600] "s"  BCM_Gp

BO_ 260 SignalGW_PR_2_PMZ: 8 GWM
 SG_ AbsThrottlePosition : 47|8@0+ (0.392157,0) [0|100.000035] "Percent"  BECM
 SG_ CalcLoadValue : 55|8@0+ (0.392157,0) [0|100.000035] "Percent"  EPICD,EPICD_E
 SG_ ChargingKeyScanRes : 31|4@0+ (1,0) [0|15] "" Vector__XXX
 SG_ EngineTorqueRipple : 25|10@0+ (1,0) [0|1023] "Nm"  SGCM
 SG_ GearPosActual : 63|4@0+ (1,0) [0|15] "" Vector__XXX
 SG_ OBDDriveCycle : 58|1@0+ (1,0) [0|1] ""  BECM,HVAC,SGCM
 SG_ OBDGeneralDenominator : 57|1@0+ (1,0) [0|1] ""  BECM,HVAC,SGCM
 SG_ OBDWarmUpCycle : 56|1@0+ (1,0) [0|1] ""  BECM,HVAC,SGCM
 SG_ PEChargingInletLockCmd : 59|1@0+ (1,0) [0|1] ""  Virtual_Node
 SG_ PEChargingInletLockCmd_UB : 26|1@0+ (1,0) [0|1] ""  Virtual_Node

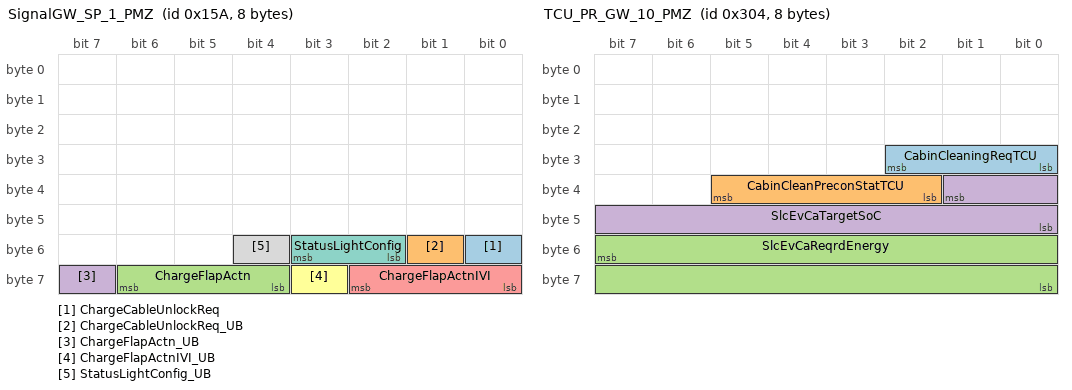
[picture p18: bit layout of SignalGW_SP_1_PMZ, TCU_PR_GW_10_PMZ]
BO_ 346 SignalGW_SP_1_PMZ: 8 GWM
 SG_ ChargeCableUnlockReq : 48|1@0+ (1,0) [0|1] "" Vector__XXX
 SG_ ChargeCableUnlockReq_UB : 49|1@0+ (1,0) [0|1] "" Vector__XXX
 SG_ ChargeFlapActn : 62|3@0+ (1,0) [0|7] "" Vector__XXX
 SG_ ChargeFlapActn_UB : 63|1@0+ (1,0) [0|1] "" Vector__XXX
 SG_ ChargeFlapActnIVI : 58|3@0+ (1,0) [0|7] "" Vector__XXX
 SG_ ChargeFlapActnIVI_UB : 59|1@0+ (1,0) [0|1] "" Vector__XXX
 SG_ StatusLightConfig : 51|2@0+ (1,0) [0|0] "" Vector__XXX
 SG_ StatusLightConfig_UB : 52|1@0+ (1,0) [0|1] "" Vector__XXX

BO_ 8 TCM_SP_PMZ_ParkLockDataTarget: 8 GWM
 SG_ ParkLockDataTarget : 7|64@0+ (1,0) [0|1.84467440737096E+019] ""  BCM_Gp

BO_ 772 TCU_PR_GW_10_PMZ: 8 GWM
 SG_ CabinCleaningReqTCU : 26|3@0+ (1,0) [0|7] ""  HVAC
 SG_ CabinCleanPreconStatTCU : 37|4@0+ (1,0) [0|15] ""  HVAC
 SG_ SlcEvCaReqrdEnergy : 55|16@0+ (0.1,0) [0|204.7] "kWh" Vector__XXX
 SG_ SlcEvCaTargetSoC : 33|10@0+ (0.1,0) [0|100] "%" Vector__XXX

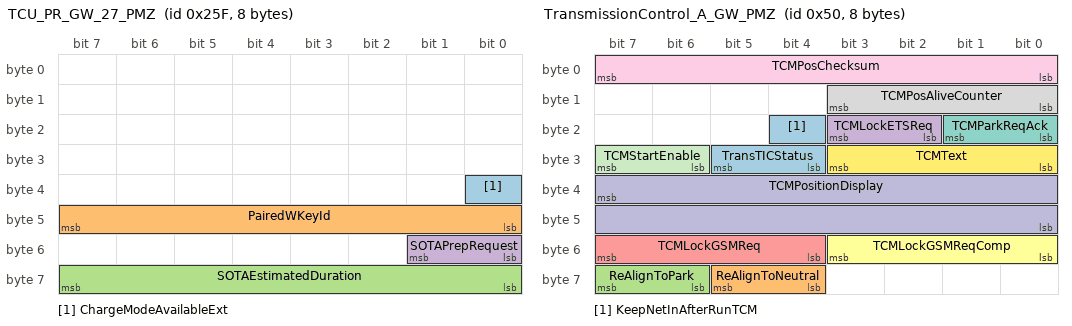
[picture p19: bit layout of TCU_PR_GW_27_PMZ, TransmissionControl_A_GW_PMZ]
BO_ 607 TCU_PR_GW_27_PMZ: 8 GWM
 SG_ ChargeModeAvailableExt : 32|1@0+ (1,0) [0|1] "" Vector__XXX
 SG_ PairedWKeyId : 47|8@0+ (1,0) [0|255] "" Vector__XXX
 SG_ SOTAEstimatedDuration : 63|8@0+ (1,0) [0|255] "Minutes" Vector__XXX
 SG_ SOTAPrepRequest : 49|2@0+ (1,0) [0|3] ""  BCM_Gp,BECM,EPICD_E,HVAC

BO_ 785 TCU_PR_GW_60_PMZ: 8 GWM
 SG_ eCallVoiceCallStatus : 57|2@0+ (1,0) [0|3] "" Vector__XXX
 SG_ UTCTimeDate : 7|56@0+ (1,0) [0|7.20575940379279E+016] "" Vector__XXX

BO_ 546 Timer1_PMZ: 8 GWM
 SG_ SetTimer1Time : 23|32@0+ (1,0) [0|4294967295] "" Vector__XXX
 SG_ SetTimer1Time_UB : 56|1@0+ (1,0) [0|1] "" Vector__XXX

BO_ 547 Timer2_PMZ: 8 GWM
 SG_ SetTimer2Time : 23|32@0+ (1,0) [0|4294967295] "" Vector__XXX
 SG_ SetTimer2Time_UB : 56|1@0+ (1,0) [0|1] "" Vector__XXX

BO_ 80 TransmissionControl_A_GW_PMZ: 8 GWM
 SG_ KeepNetInAfterRunTCM : 20|1@0+ (1,0) [0|1] "" Vector__XXX
 SG_ ReAlignToNeutral : 61|2@0+ (1,0) [0|3] "" Vector__XXX
 SG_ ReAlignToPark : 63|2@0+ (1,0) [0|3] "" Vector__XXX
 SG_ TCMLockETSReq : 19|2@0+ (1,0) [0|3] "" Vector__XXX
 SG_ TCMLockGSMReq : 55|4@0+ (1,0) [0|15] "" Vector__XXX
 SG_ TCMLockGSMReqComp : 51|4@0+ (1,0) [0|15] "" Vector__XXX
 SG_ TCMParkReqAck : 17|2@0+ (1,0) [0|3] "" Vector__XXX
 SG_ TCMPosAliveCounter : 11|4@0+ (1,0) [0|15] "Counter value" Vector__XXX
 SG_ TCMPosChecksum : 7|8@0+ (1,0) [0|255] "checksum" Vector__XXX
 SG_ TCMPositionDisplay : 39|16@0+ (1,0) [0|65535] "" Vector__XXX
 SG_ TCMStartEnable : 31|2@0+ (1,0) [0|3] "" Vector__XXX
 SG_ TCMText : 27|4@0+ (1,0) [0|15] "" Vector__XXX
 SG_ TransTICStatus : 29|2@0+ (1,0) [0|3] "" Vector__XXX

BO_ 2015 TST_FunctionalReq_PMZBus: 8 GWM
 SG_ TST_FunctionalReq_PMZ_PDU : 7|64@0+ (1,0) [0|0] ""  BCM_Gp,BECM,EPICD,EPICD_E,HVAC,SGCM

BO_ 2021 TST_PhysicalReqBCCM_PMZ: 8 GWM
 SG_ TST_PhysicalReqBCCM_PDU : 7|64@0+ (1,0) [0|0] "" Vector__XXX

BO_ 1830 TST_PhysicalReqBCMHS_PMZ: 8 GWM
 SG_ TST_PhysicalReqBCM_PDU : 7|64@0+ (1,0) [0|0] ""  BCM_Gp

BO_ 2020 TST_PhysicalReqBECM_PMZ: 8 GWM
 SG_ TST_PhysicalReqBECM_PDU : 7|64@0+ (1,0) [0|0] ""  BECM

BO_ 1861 TST_PhysicalReqEDPM_PMZ: 8 GWM
 SG_ TST_PhysicalReqEDPM_PDU : 7|64@0+ (1,0) [0|0] "" Vector__XXX

BO_ 1875 TST_PhysicalReqEPICD_PMZ: 8 GWM
 SG_ TST_PhysicalReqEPICD_PDU : 7|64@0+ (1,0) [0|0] ""  EPICD,EPICD_E

BO_ 1843 TST_PhysicalReqHVAC_PMZ: 8 GWM
 SG_ TST_PhysicalReqHVAC_PDU : 7|64@0+ (1,0) [0|0] ""  HVAC

BO_ 1909 TST_PhysicalReqHVCCM_PMZ: 8 GWM
 SG_ TST_PhysicalReqHVCCM_PDU : 7|64@0+ (1,0) [0|0] "" Vector__XXX

BO_ 1920 TST_PhysicalReqSGCM_PMZ: 8 GWM
 SG_ TST_PhysicalReqSGCM_PDU : 7|64@0+ (1,0) [0|0] ""  SGCM

BO_ 1831 TST_PhysicalReqTSCM_PMZ: 8 GWM
 SG_ TST_PhysicalReqTSCM_PDU : 7|64@0+ (1,0) [0|0] "" Vector__XXX

BO_ 1838 TST_PhysicalRespBCM_PMZ: 8 BCM_Gp
 SG_ TST_PhysicalRespBCM_PDU : 7|64@0+ (1,0) [0|0] ""  GWM

BO_ 2028 TST_PhysicalRespBECM_PMZ: 8 BECM
 SG_ TST_PhysicalRespBECM_PDU : 7|64@0+ (1,0) [0|0] ""  GWM

BO_ 1883 TST_PhysicalRespEPICD_PMZ: 8 EPICD_E
 SG_ TST_PhysicalRespEPICD_PDU : 7|64@0+ (1,0) [0|0] ""  GWM

BO_ 1851 TST_PhysicalRespHVAC_PMZ: 8 HVAC
 SG_ TST_PhysicalRespHVAC_PDU : 7|64@0+ (1,0) [0|0] ""  GWM

BO_ 1928 TST_PhysicalRespSGCM_PMZ: 8 SGCM
 SG_ TST_PhysicalRespSGCM_PDU : 7|64@0+ (1,0) [0|0] ""  GWM

BO_ 1736 UUDT_1_BECM_PMZCAN: 8 BECM
 SG_ UUDTBECMResponse1 : 7|64@0+ (1,0) [0|1.84467440737096E+019] ""  GWM

BO_ 1704 UUDT_1_SGCM_PMZCAN: 8 SGCM
 SG_ UUDTSGCMResponse1 : 7|64@0+ (1,0) [0|1.84467440737096E+019] ""  GWM

BO_ 1737 UUDT_2_BECM_PMZCAN: 8 BECM
 SG_ UUDTBECMResponse2 : 7|64@0+ (1,0) [0|1.84467440737096E+019] ""  GWM

BO_ 1705 UUDT_2_SGCM_PMZCAN: 8 SGCM
 SG_ UUDTSGCMResponse2 : 7|64@0+ (1,0) [0|1.84467440737096E+019] ""  GWM

BO_ 1738 UUDT_3_BECM_PMZCAN: 8 BECM
 SG_ UUDTBECMResponse3 : 7|64@0+ (1,0) [0|1.84467440737096E+019] ""  GWM

BO_ 1706 UUDT_3_SGCM_PMZCAN: 8 SGCM
 SG_ UUDTSGCMResponse3 : 7|64@0+ (1,0) [0|1.84467440737096E+019] ""  GWM

BO_ 1739 UUDT_4_BECM_PMZCAN: 8 BECM
 SG_ UUDTBECMResponse4 : 7|64@0+ (1,0) [0|1.84467440737096E+019] ""  GWM

BO_ 1707 UUDT_4_SGCM_PMZCAN: 8 SGCM
 SG_ UUDTSGCMResponse4 : 7|64@0+ (1,0) [0|1.84467440737096E+019] ""  GWM

BO_ 1024 VEHCONFIG_400PMZ_AutoSAR: 8 CCF_Server
 SG_ SF_VEHCONFIG_400PMZ_AutoSAR_PDU M : 0|8@1+ (1,0) [0|255] ""  BECM,EPICD_E,HVAC,SGCM
 SG_ CcfAlternator m1 : 63|8@0+ (1,0) [0|255] "" Vector__XXX
 SG_ CcfBifuel m1 : 39|8@0+ (1,0) [0|255] "" Vector__XXX
 SG_ CcfDoors m1 : 23|8@0+ (1,0) [0|255] "" Vector__XXX
 SG_ CcfEngine m1 : 47|8@0+ (1,0) [0|255] ""  BECM,HVAC
 SG_ CcfFuel m1 : 55|8@0+ (1,0) [0|255] ""  HVAC
 SG_ CcfTransmissionDriveLn m1 : 31|8@0+ (1,0) [0|255] "" Vector__XXX
 SG_ CcfVehicleType m1 : 15|8@0+ (1,0) [0|255] ""  HVAC
 SG_ CcfAlarm m2 : 47|8@0+ (1,0) [0|255] "" Vector__XXX
 SG_ CcfFuelTankVolume m2 : 39|8@0+ (1,0) [0|255] "" Vector__XXX
 SG_ CcfGearbox m2 : 23|8@0+ (1,0) [0|255] "" Vector__XXX
 SG_ CcfGearboxType m2 : 31|8@0+ (1,0) [0|255] "" Vector__XXX
 SG_ CcfHeadlightsType m2 : 63|8@0+ (1,0) [0|255] "" Vector__XXX
 SG_ CcfSeatMassage m2 : 55|8@0+ (1,0) [0|255] "" Vector__XXX
 SG_ CcfSteeringWheelPosn m2 : 15|8@0+ (1,0) [0|255] ""  HVAC
 SG_ CcfAdditionalHeater m4 : 15|8@0+ (1,0) [0|255] ""  HVAC
 SG_ CcfCruiseControl m4 : 23|8@0+ (1,0) [0|255] "" Vector__XXX
 SG_ CcfHeadlightCleaning m4 : 39|8@0+ (1,0) [0|255] "" Vector__XXX
 SG_ CcfPowerSteeringType m4 : 47|8@0+ (1,0) [0|255] "" Vector__XXX
 SG_ CcfPrivateLockingTrunk m4 : 63|8@0+ (1,0) [0|255] "" Vector__XXX
 SG_ CcfRainSensor m4 : 31|8@0+ (1,0) [0|255] "" Vector__XXX
 SG_ CcfTripComputer m4 : 55|8@0+ (1,0) [0|255] "" Vector__XXX
 SG_ CcfBatteryRear m6 : 47|8@0+ (1,0) [0|255] "" Vector__XXX
 SG_ CcfBlindSpotInfoSystem m6 : 23|8@0+ (1,0) [0|255] "" Vector__XXX
 SG_ CcfClimateControlUnit m6 : 63|8@0+ (1,0) [0|255] ""  HVAC
 SG_ CcfCoupeFilter m6 : 55|8@0+ (1,0) [0|255] "" Vector__XXX
 SG_ CcfPanicAlarm m6 : 15|8@0+ (1,0) [0|255] "" Vector__XXX
 SG_ CcfPPTCHeater m6 : 39|8@0+ (1,0) [0|255] ""  HVAC
 SG_ CcfRoadFrictionDetection m6 : 31|8@0+ (1,0) [0|255] "" Vector__XXX
 SG_ CcfHeartbeatSensor m7 : 55|8@0+ (1,0) [0|255] "" Vector__XXX
 SG_ CcfHeatedRearSeat m7 : 63|8@0+ (1,0) [0|255] ""  HVAC
 SG_ CcfInstrumentClusterCal m7 : 31|8@0+ (1,0) [0|255] "" Vector__XXX
 SG_ CcfInteriorMotionSensor m7 : 47|8@0+ (1,0) [0|255] "" Vector__XXX
 SG_ CcfSpeedLimitation m7 : 15|8@0+ (1,0) [0|255] "" Vector__XXX
 SG_ CcfSpeedWarningDevice m7 : 23|8@0+ (1,0) [0|255] "" Vector__XXX
 SG_ CcfWheelBrakesTypeFront m7 : 39|8@0+ (1,0) [0|255] "" Vector__XXX
 SG_ CcfCallstartOfParkHeat m8 : 63|8@0+ (1,0) [0|255] ""  HVAC
 SG_ CcfFrontSeatVentilation m8 : 55|8@0+ (1,0) [0|255] "" Vector__XXX
 SG_ CcfHeatedFrontSeats m8 : 47|8@0+ (1,0) [0|255] ""  HVAC
 SG_ CcfSeatHeatCalibration m8 : 39|8@0+ (1,0) [0|255] ""  HVAC
 SG_ CcfServiceInt m8 : 31|8@0+ (1,0) [0|255] "" Vector__XXX
 SG_ CcfTelephone m8 : 15|8@0+ (1,0) [0|255] "" Vector__XXX

CM_ SG_ 132 BrakeSwitchStatus "Indicates status and fault condition of brake pedal.

";
CM_ SG_ 132 EMSAliveCounter "This counter forms part of a safety-related signal group.
It is incremented by the task which generates the data set used in the CRC calculation, and may be used to determine the health of the data generation task.
Refer to STJLR 18.036 for more detail.";
CM_ SG_ 132 EMSChecksum "This CRC shall be calculated in compliance with STJLR 18.036 Version 5.
The Data Segment Polynomial shall be constructed from the details
in the network configuration file.";
CM_ SG_ 132 EngineSpeed "Instantaneous Crank shaft speed, not corrected for flywheel tolerances and not smoothed.";
CM_ SG_ 132 EngineSpeedQF "Quality Factor for 'EngineSpeed'";
CM_ SG_ 132 MHStopStartStatus "L538:
Status of the Eco-Start Stop-Start Feature
";
CM_ SG_ 132 PowerPackStatus "Describes the state of the powerpack
";
CM_ SG_ 733 DrvlineDampTorqMaxLim "Maximum allowable Electric Machine modulation torque that can be used during Driveline Damping.
Modulated torque limit relative to the EMTorqueRequestExt rather than an absolute value.";
CM_ SG_ 733 DrvlineDampTorqMinLim "Minimum allowable Electric Machine modulation torque that can be used during Driveline Damping.
Modulated torque limit relative to the EMTorqueRequestExt rather than an absolute value.";
CM_ SG_ 733 EMTorqueMaxLimit "Maximum allowed Electric Machine torque in motor mode used only for Voltage and Speed control modes. Motoring torque is positive.
";
CM_ SG_ 733 EMTorqueMinLimit "Minimum allowed Electric Machine torque in generator mode used only for Voltage and Speed control modes. Generating torque is negative.
";
CM_ SG_ 733 VSCEMTorqLimGpCounter "This counter forms part of a safety-related signal group.
It is incremented by the task which generates the data set used in the CRC calculation, and may be used to determine the health of the data generation task.
Refer to STJLR 18.036 for more detail.";
CM_ SG_ 733 VSCEMTorqLimGpCS "This CRC shall be calculated in compliance with STJLR 18.036 Version 5.
The Data Segment Polynomial shall be constructed from the details in the network configuration file.";
CM_ SG_ 54 PedalPosPro "'Driver demanded accelerator pedal position in %.
Kick-down indication is NOT included in the signal encoding.'";
CM_ SG_ 54 PedalPosProAliveCounter "This counter forms part of a safety-related signal group.
It is incremented by the task which generates the data set used in the CRC calculation, and may be used to determine the health of the data generation task.
Refer to STJLR 18.036 for more detail.";
CM_ SG_ 54 PedalPosProChecksum "This CRC shall be calculated in compliance with STJLR 18.036 Version 5.
The Data Segment Polynomial shall be constructed from the details in the network configuration file.";
CM_ SG_ 54 PedalPosProQF "Quality factor for the signal PedalPosPro.";
CM_ SG_ 13 VSCHoldRequest "This signal requests the ABS Roll Back Protection function to be activated i.e. the foundation brakes are requested to hold the vehicle. ";
CM_ SG_ 13 WheelTorqTgtGpCounter "This counter forms part of a safety-related signal group.
It is incremented by the task which generates the data set used in the CRC calculation, and may be used to determine the health of the data generation task.
Refer to STJLR 18.036 for more detail.";
CM_ SG_ 13 WheelTorqTgtGpCS "This CRC shall be calculated in compliance with STJLR 18.036 Version 5.
The Data Segment Polynomial shall be constructed from the details in the network configuration file.";
CM_ SG_ 13 WheelTorqTgtWoIntF "This is the 'long term' target front wheels torque. This includes driver demand (accelerator pedal) , vehicle motion control functions (i.e. cruise, ACC, ASL, vehicle speed limitation), and long term torque limitations  & offsets (i.e. driveline protection)
This request excludes short term interventions (i.e. Traction Control, Shift Energy Management).
Inertial terms are not included / compensated for (steady state speed is assumed).";
CM_ SG_ 13 WheelTorqTgtWoIntR "This is the 'long term' target rear wheels torque. This includes driver demand (accelerator pedal) , vehicle motion control functions (i.e. cruise, ACC, ASL, vehicle speed limitation), and long term torque limitations  & offsets (i.e. driveline protection)
This request excludes short term interventions (i.e. Traction Control, Shift Energy Management).
Inertial terms are not included / compensated for (steady state speed is assumed).";
CM_ SG_ 853 BISGCalibrationIDReq "Sporadic Signal PCM Diagnostic request to BISG to send the Calibration Verification Number (CVN) and Calibration Identification";
CM_ SG_ 347 DCDCCurrentMVLimit "The Current on the HV Bus that the DCDC converter must not exceed.";
CM_ SG_ 347 DCDCFanControlReq "Request for DCDC Fan to operate (PWM)";
CM_ SG_ 347 DCDCOperatingModeReqEx "DCDC Converter Operating mode request";
CM_ SG_ 347 DCDCVoltage12vLimit "Lower limit for the vehicle 12V electrical system in boost mode
";
CM_ SG_ 41 DCDCCurrentMVLimitExt "The Current on the HV Bus that the DCDC converter must not exceed.";
CM_ SG_ 41 EMCurDcLinkGenLimit "Instantaneous minimum DC Link current that can be supplied during generating mode derived from battery power limits, not to overload HV battery in generating mode. Current is negative in generating mode.
";
CM_ SG_ 41 EMGenLimitGrpCounter "This counter forms part of a safety-related signal group.
It is incremented by the task which generates the data set used in the CRC calculation, and may be used to determine the health of the data generation task.
Refer to STJLR 18.036 for more detail.";
CM_ SG_ 41 EMGenLimitGrpCS "This CRC shall be calculated in compliance with STJLR 18.036 Version 5.
The Data Segment Polynomial shall be constructed from the details in the network configuration file.";
CM_ SG_ 41 EMVolDcLinkGenLimit "Instantaneous maximum DC Link voltage allowed in generating mode so as not to exceed the HV battery high voltage limit
";
CM_ SG_ 122 EMCurDcLinkMotorLimit "Instantaneous maximum DC Link current that can be taken during motoring mode derived from battery power limits, not to overload HV battery in motor mode. Current is positive in motoring mode.
";
CM_ SG_ 122 EMMotorLimitGrpCounter "This counter forms part of a safety-related signal group.
It is incremented by the task which generates the data set used in the CRC calculation, and may be used to determine the health of the data generation task.
Refer to STJLR 18.036 for more detail.";
CM_ SG_ 122 EMMotorLimitGrpCS "This CRC shall be calculated in compliance with STJLR 18.036 Version 5.
The Data Segment Polynomial shall be constructed from the details in the network configuration file.";
CM_ SG_ 122 EMVolDcLinkMotorLimit "Instantaneous minimum  DC Link voltage allowed in motoring mode so as not to go below the HV battery low voltage limit
";
CM_ SG_ 122 EMVoltageDcLinkReqMV "Requested DC link voltage value in Electric Machine 'Voltage control' mode";
CM_ SG_ 156 EMDurationMaxESA "Controls Engine Stop Assist (BISG) - Maximum duration of ESA";
CM_ SG_ 156 EMEndSpeedESA "Controls Engine Stop Assist (BISG) - Machine end speed for ESA mode";
CM_ SG_ 156 EMSpeedGradientESA "Controls Engine Stop Assist (BISG) - Negative torque gradient during Negative Torque control operation
";
CM_ SG_ 156 EMTorqueGradientNeg "Negative Torque Gradient for BISG";
CM_ SG_ 156 EMTorqueGradientPos "Positive Torque Gradient for BISG
";
CM_ SG_ 156 EMTorqueLimitESA "Controls Engine Stop Assist (BISG) - Torque limitation set point in ESA mode";
CM_ SG_ 162 HVBattAllowWakeUpDch "This signal authorises or not the HV Battery to request a vehicle wake-up for discharging itself event whilst in PowerMode 0.";
CM_ SG_ 162 HVBattContactorRequest "Request to close the HV battery contactors.

For vehicle's with multiple HV Buses, this is the Request of the Auxiliary Bus Contactors.";
CM_ SG_ 162 HybridMode "Current operating state of the hybrid system";
CM_ SG_ 162 MVBattTOCRStatus "Status of the Top Of Charge Reset function allowing to fully recharge the MHEV Battery in order to maintain accurate SOC estimation.";
CM_ SG_ 352 MVBattFanControlReq "Request for MV Battery Fan to operate";
CM_ SG_ 354 BatteryCoolantFlow "Coolant flow in the Battery circuit";
CM_ SG_ 354 ClimatePowerLimitExt "Power consumption limit for climate sent by VSC";
CM_ SG_ 354 VSCHVBattCoolingReq "Cooling power request to be used to cool the HV Battery.";
CM_ SG_ 743 MVBattCalibrationIDReq "PCM Diagnostic request to BECM to send the Calibration Verification Number (CVN) and Calibration Identification";
CM_ SG_ 304 eDriveCoolantLevel "eDrive coolant level sensor status";
CM_ SG_ 356 HVBattPumpDRReq "HV Battery coolant pump duty ratio request";
CM_ SG_ 170 EMOperatingModeReqExt "Electrical Machine (ACDC) operating mode request";
CM_ SG_ 170 EMSpeedRequestExt "Requested Electric machine speed value in 'Speed control mode'
";
CM_ SG_ 170 EMTorqueRequestExt "Torque request for the Rear eMachine machine.
EDU Applications:
Positive for forwards propulsion or regenerative deceleration in the reverse direction.
Negative for rearwards propulsion or regenerative deceleration in the forward direction
Transmission eMachine:
Positive for motoring, negative for generating.
Note: More precise version of the EMTorqueRequest signal.";
CM_ SG_ 170 EMVoltageDCLinkReqExt "Requested DC link voltage value in Electric Machine 'Voltage control' mode";
CM_ SG_ 170 VSCEMReqGpCounter "This counter forms part of a safety-related signal group.
It is incremented by the task which generates the data set used in the CRC calculation, and may be used to determine the health of the data generation task.
Refer to STJLR 18.036 for more detail.";
CM_ SG_ 170 VSCEMReqGpCS "This CRC shall be calculated in compliance with STJLR 18.036 Version 5.
The Data Segment Polynomial shall be constructed from the details in the network configuration file.";
CM_ SG_ 219 DCDC12vSupplyStatus "Ability of the DCDC converter system to provide supply to the 12v System
";
CM_ SG_ 219 DCDC12vSupplyStatusCmp "Ability of the DCDC converter system to provide supply to the 12v System


This is a complement to enable data integrity across the communication layer.";
CM_ SG_ 219 OverrunBrakeLightReq "Signal to request Brake Light activation";
CM_ SG_ 219 PwrSupSwitchRequest "Signal requesting the PSS (Power Supply System) to actively switch the Dual Battery switches into the ready to crank state.  These switches are used to isolate or bring into circuit both main and secondary 12V batteries.  The signal is reset back to its default state (0) once the engine is running again.  This signal works in conjunction with the acknowledgement CAN signal PwrSupSwitchStatus.";
CM_ SG_ 219 PwrSupSwitchRequestCmp "Signal requesting the PSS (Power Supply System) to actively switch the Dual Battery switches into the ready to crank state.  These switches are used to isolate or bring into circuit both main and secondary 12V batteries.  The signal is reset back to its default state (0) once the engine is running again.  This signal works in conjunction with the acknowledgement CAN signal PwrSupSwitchStatus.

This is a complement signal to provide data integrity across the communication layer.";
CM_ SG_ 219 VSCPwrSupAliveCounter "This counter forms part of a safety-related signal group.
It is incremented by the task which generates the data set used in the CRC calculation, and may be used to determine the health of the data generation task.
Refer to STJLR 18.036 for more detail.";
CM_ SG_ 239 AmbientAirPressure "Measured barometric pressure.

EuCD name. Previously called BarometricPressure.";
CM_ SG_ 239 AmbientAirPressureQF "Quality Factor for AmbientAirPressure

EuCD signal name.";
CM_ SG_ 239 AmbientTemp "Ambient air temperature.

EuCD signal encoding,
";
CM_ SG_ 239 AmbientTempQF "EuCD Unique Signal. Quality factor for the signal AmbientTemp.";
CM_ SG_ 239 eDriveDerateLevel "EV thermal arbitration Vehicle performance derate level to be applied";
CM_ SG_ 239 EngineCoolantTemp "Measured engine coolant temperature.
Source is dependent on sensor location: engine coolant outlet or cylinder head temperature.";
CM_ SG_ 239 EngineCoolantTempQF "Quality Factor for 'EngineCoolantTemp'.";
CM_ SG_ 239 EngineOilTemp "Measured engine oil temperature.";
CM_ SG_ 239 EngineOilTempQF "Quality Factor for 'EngineOilTemp'";
CM_ SG_ 191 CrashAirbagStatus "Driver and passenger airbag deployment status. This information is used to estimate the crash severity.

This signal is used for additional data about the crash event that has occurred when CrashStatusRCM has been set to crash.
The signal status reported here shall represent the status at the point of crash detection and shall be latched in that state for the period that CrashStatusRCM is set to crash.";
CM_ SG_ 191 CrashOccClassStatus "Front passenger seat occupancy status. This information is to be considered while estimating the crash severity.

This signal is used for additional data about the crash event that has occurred when CrashStatusRCM has been set to crash.
The signal status reported here shall represent the status at the point of crash detection and shall be latched in that state for the period that CrashStatusRCM is set to crash.";
CM_ SG_ 191 CrashPACOSSwitchState "'Passenger Airbag Cut Off Switch' state. This information is to be used while estimating the crash severity.

This signal is used for additional data about the crash event that has occurred when CrashStatusRCM has been set to crash.
The signal status reported here shall represent the status at the point of crash detection and shall be latched in that state for the period that CrashStatusRCM is set to crash.";
CM_ SG_ 191 CrashPretensionerStat "Driver's and front seat passenger's pretensioner state. This information is used in estimating the crash severity.

This signal is used for additional data about the crash event that has occurred when CrashStatusRCM has been set to crash.
The signal status reported here shall represent the status at the point of crash detection and shall be latched in that state for the period that CrashStatusRCM is set to crash.";
CM_ SG_ 191 CrashSeatBeltBcklState "Driver's and front seat passenger's seatbelt buckle state. This information is used to estimate the crash severity.

This signal is used for additional data about the crash event that has occurred when CrashStatusRCM has been set to crash.
The signal status reported here shall represent the status at the point of crash detection and shall be latched in that state for the period that CrashStatusRCM is set to crash.";
CM_ SG_ 191 CrashSeverityClass "Crash severity classification for frontal collisions. Set to 'No event' for rear/side collisions.

This signal is used for additional data about the crash event that has occurred when CrashStatusRCM has been set to crash
The signal status reported here shall represent the status at the point of crash detection and shall be latched in that state for the period that CrashStatusRCM is set to crash.";
CM_ SG_ 191 CrashSideAirbagStatus "Side airbags/curtains deployment status. This information is used to estimate the crash severity.

This signal is used for additional data about the crash event that has occurred when CrashStatusRCM has been set to crash.
The signal status reported here shall represent the status at the point of crash detection and shall be latched in that state for the period that CrashStatusRCM is set to crash.";
CM_ SG_ 191 CrashStatusPIE "This signal defines the crash status of the PIE.";
CM_ SG_ 191 CrashStatusRCM "This signal defines the crash status of the vehicle safety system.";
CM_ SG_ 191 CrashTypeFront "Signal indicates whether front crash has occurred or not. This is required to estimate the crash severity.
0 - No Front crash
1 - Front crash

This signal is used for additional data about the crash event that has occurred when CrashStatusRCM has been set to crash.
The signal status reported here shall represent the status at the point of crash detection and shall be latched in that state for the period that CrashStatusRCM is set to crash.";
CM_ SG_ 191 CrashTypeRear "Signal indicates whether rear crash has occurred or not. This is required to estimate the crash severity.
0 - No rear crash
1 - Rear crash

This signal is used for additional data about the crash event that has occurred when CrashStatusRCM has been set to crash.
The signal status reported here shall represent the status at the point of crash detection and shall be latched in that state for the period that CrashStatusRCM is set to crash.";
CM_ SG_ 191 CrashTypeRoll "Signal indicates whether vehicle rollover has occurred or not. This information is required to estimate the crash severity.

This signal is used for additional data about the crash event that has occurred when CrashStatusRCM has been set to crash.
The signal status reported here shall represent the status at the point of crash detection and shall be latched in that state for the period that CrashStatusRCM is set to crash.
";
CM_ SG_ 191 CrashTypeSide "Signal indicates whether side crash has occurred or not. This information is required to estimate the crash severity.
0 - No side crash
1 - Side crash 

This signal is used for additional data about the crash event that has occurred when CrashStatusRCM has been set to crash.
The signal status reported here shall represent the status at the point of crash detection and shall be latched in that state for the period that CrashStatusRCM is set to crash.";
CM_ SG_ 191 DrivSeatBeltBcklError "When the bit is set to a '1', a fault condition exists for the driver's seat belt buckle switch.";
CM_ SG_ 191 DrivSeatBeltBcklState "When the bit is set to a '1', the driver's seat belt buckle is latched.
This signal will be invalid and set to 1 (latched) during proveout and should not be used by subscriber until the valid state is established at 1sec post ignition on PM6";
CM_ SG_ 191 DrivSeatPositionError "Error status of driver seat track position switch.";
CM_ SG_ 191 DrivSeatPositionStatus "Status of driver seat track position switch.

This signal will be invalid and set to 1 (forward) during proveout and should not be used by subscribers until the valid state is established at 1sec post ignition on (PM6)";
CM_ SG_ 191 KeepNetInAfterRunRCM "An after-run function master shall send a CAN signal stating that the network is required during after-run. This allows the after-run manager to keep the OSEK nodes awake in order to create a stable ring and also allows supporting slaves to continue CAN transmission or supply ECU power.";
CM_ SG_ 191 PassSeatBeltBcklError "When the bit is set to a '1', a fault condition exists for the passenger seat belt buckle switch.";
CM_ SG_ 191 PassSeatBeltBcklState "When the bit is set to a '1', the passenger seat belt buckle is latched.";
CM_ SG_ 191 PassSeatPositionStatus "This signal will be invalid and set to 1 (forward) during proveout and should not be used by subscribers until the valid state is established at 1sec post ignition on (PM6)";
CM_ SG_ 191 SeatBeltBcklAC "This counter forms part of a safety-related signal group.
It is incremented by the task which generates the data set used in the CRC calculation, and may be used to determine the health of the data generation task.
Refer to STJLR 18.036 for more detail.";
CM_ SG_ 191 SeatBeltBcklCS "This CRC shall be calculated in compliance with STJLR 18.036 Version 5.
The Data Segment Polynomial shall be constructed from the details in the network configuration file.";
CM_ SG_ 191 TriggerEventRCM "This signal defines the Trigger Event EDR recording status of the vehicle safety system. This is where the RCM shall record. EDR data, regardless of if there is a deployment or fuel cut off. According to 49 CFR part 583 (acceleration of 8kph or greater within 150ms.";
CM_ SG_ 738 SBBatCurr "'The current measured flowing into and out of the battery pack.
-ve shall be defined as current flowing out of the battery pack.
+ve shall be defined as current flowing into the battery pack.'
";
CM_ SG_ 738 SBBatCurrFlt "Indicates if a fault has occurred with the current sensor which prevents the correct current being measured or transmitted.
";
CM_ SG_ 738 SBBatVolt "This signal indicates the voltage as measured across the battery terminals.
";
CM_ SG_ 738 SBBatVoltFlt "Indicates if a fault has occurred with the battery terminal voltage sensor which prevents the correct voltage being measured or transmitted.
";
CM_ SG_ 738 SBCriticErr "Indicates if a critical error has occurred within the battery or BMS which prevents it from performing the safety functions.
";
CM_ SG_ 738 SBECUFlt "Indicates if a BMS ECU fault has occurred which does not affect the safe operation of the battery.
";
CM_ SG_ 738 SBPos1Temp "The temperature measured at Position 1 within the battery pack.
";
CM_ SG_ 738 SBPos2Temp "The temperature measured at Position 2 within the battery pack.
";
CM_ SG_ 738 SBRelayClsFlt "Indicates whether the isolation relay has failed such that it can no longer operate and is stuck in a closed position.
";
CM_ SG_ 738 SBRelayOpenFlt "Indicates whether the isolation relay has failed such that it can no longer operate and is stuck in an open position.
";
CM_ SG_ 738 SBRelayStatus "Indicates the status of the isolation relay.
";
CM_ SG_ 738 SBSOCRelative "This is determined by performing the capacity measurements at the present battery pack temperature.
";
CM_ SG_ 739 SBQChaRideCn "The total battery input Ah, (I > 0), measured whilst the BMS is operating in VEH_STATE = 3. Normalised to battery rated capacity.
";
CM_ SG_ 739 SBQChaRunCn "The total battery input Ah, (I > 0), measured whilst the vehicle is operating in PowerMode = 7. Normalised to battery rated capacity.";
CM_ SG_ 739 SBQDchaRideCn "The total battery output Ah, (I < 0), measured whilst the BMS is operating in VEH_STATE = 3. Normalised to battery rated capacity.
";
CM_ SG_ 739 SBQDchaRunCn "The total battery output Ah, (I < 0), measured whilst the vehicle is operating in PowerMode = 7. Normalised to battery rated capacity.";
CM_ SG_ 740 SBQDchActCn "The total battery output Ah, (I < 0), measured whilst the BMS is operating in VEH_STATE = 2. Normalised to battery rated capacity.
";
CM_ SG_ 740 SBQDchActHiCn "The total battery output Ah, (I < 0), measured whilst the vehicle is operating in PowerMode = 4. Normalised to battery rated capacity.";
CM_ SG_ 740 SBQDchEcoStpCn "The total battery output Ah, (I < 0), measured whilst the vehicle is operating in PowerMode = 7 and PowerPackStatus = 6. Normalised to battery rated capacity.";
CM_ SG_ 740 SBQDchQdCn "The total battery output Ah, (I < 0), measured whilst the BMS is operating in VEH_STATE = 1.  Normalised to battery rated capacity.
";
CM_ SG_ 790 SBCell1Volt "The voltage as measured across string 1.
";
CM_ SG_ 790 SBCell1VoltFlt "Indicates if a fault has occurred with voltage sensor for string of parallel cells 1.
";
CM_ SG_ 790 SBCell2Volt "The voltage as measured across string 2.
";
CM_ SG_ 790 SBCell2VoltFlt "Indicates if a fault has occurred with voltage sensor for string of parallel cells 2.
";
CM_ SG_ 790 SBCell3Volt "The voltage as measured across string 3.
";
CM_ SG_ 790 SBCell3VoltFlt "Indicates if a fault has occurred with voltage sensor for string of parallel cells 3.
";
CM_ SG_ 790 SBCell4Volt "The voltage as measured across string 4.
";
CM_ SG_ 790 SBCell4VoltFlt "Indicates if a fault has occurred with voltage sensor for string of parallel cells 4.
";
CM_ SG_ 791 SBMaxChrgVoltLmt "The maximum voltage which may be applied at the battery terminal posts and which will not cause damage and/or degradation to the battery at present conditions.
";
CM_ SG_ 791 SBPackVolt "The voltage as measured across the internal combination of the battery cells but not including the isolation relay or other connections to the battery terminals.
";
CM_ SG_ 791 SBPackVoltFlt "Indicates if a fault has occurred with the battery pack voltage sensor which prevents the correct voltage being measured or transmitted.
";
CM_ SG_ 791 SBPos1TempFlt "Indicates if a fault has occurred with battery temperature sensor 1 which prevents the correct temperature being measured or transmitted.
";
CM_ SG_ 791 SBPos2TempFlt "Indicates if a fault has occurred with battery temperature sensor 2 which prevents the correct temperature being measured or transmitted.
";
CM_ SG_ 791 SBSOCAbsolute "This is determined by performing the capacity measurements at the temperature for which the battery nominal capacity is defined, typically this is +25degC.
";
CM_ SG_ 791 SBSOHCapFade "The reduction in capacity from the rated battery capacity which has occurred to date.
";
CM_ SG_ 791 SBSOHImpGrowth "The % increase in discharge impedance from that expected for a new battery at agreed nominal conditions.
";
CM_ SG_ 325 SBBatCurrProtdHB "The current measured flowing into and out of the battery pack. -ve shall be defined as current flowing out of the battery pack. +ve shall be defined as current flowing into the battery pack, higher byte data.";
CM_ SG_ 325 SBBatCurrProtdLB "The current measured flowing into and out of the battery pack. -ve shall be defined as current flowing out of the battery pack. +ve shall be defined as current flowing into the battery pack, lower byte data.";
CM_ SG_ 325 SBBatGpAC "This counter forms part of a safety-related signal group.
It is incremented by the task which generates the data set used in the CRC calculation, and may be used to determine the health of the data generation task.
Refer to STJLR 18.036 for more detail.";
CM_ SG_ 325 SBBatGpCS "This CRC shall be calculated in compliance with STJLR 18.036 Version 5.
The Data Segment Polynomial shall be constructed from the details in the network configuration file.";
CM_ SG_ 325 SBBatMinCurrHB "Minimum Current Observed in the last 0.5 seconds, higher byte data.";
CM_ SG_ 325 SBBatMinCurrLB "Minimum Current Observed in the last 0.5 seconds, lower byte data.";
CM_ SG_ 325 SBBatMinVoltHB "Minimum Terminal Voltage Observed in the last 0.5 seconds, higher byte data.";
CM_ SG_ 325 SBBatMinVoltLB "Minimum Terminal Voltage Observed in the last 0.5 seconds, lower byte data.";
CM_ SG_ 325 SBBatVoltProtd "This signal indicates the voltage as measured across the battery terminals.";
CM_ SG_ 939 SBCapFadeCorr "The difference between the updated physical measurement of Capacity Fade and the prior estimate.";
CM_ SG_ 939 SBSoCCorr "The difference between the updated physical measurement of State of Charge and the prior estimate.";
CM_ SG_ 939 SBSoCSoHGpAC "This counter forms part of a safety-related signal group.
It is incremented by the task which generates the data set used in the CRC calculation, and may be used to determine the health of the data generation task.
Refer to STJLR 18.036 for more detail.";
CM_ SG_ 939 SBSoCSoHGpCS "This CRC shall be calculated in compliance with STJLR 18.036 Version 5.
The Data Segment Polynomial shall be constructed from the details in the network configuration file.";
CM_ SG_ 939 SBTimeLastSoCResetHB "Time since the battery corrected its State of charge model with physical measurement, higher byte data.";
CM_ SG_ 939 SBTimeLastSoCResetLB "Time since the battery corrected its State of charge model with physical measurement, lower byte data.";
CM_ SG_ 939 SBTimeLastSoHResetHB "Time since the battery corrected its State of Health model with physical measurement, higher byte data.";
CM_ SG_ 939 SBTimeLastSoHResetLB "Time since the battery corrected its State of Health model with physical measurement, lower byte data.";
CM_ SG_ 940 SBDCIRCorr "The difference between the updated physical measurement of DCIR and the prior estimate.";
CM_ SG_ 940 SBDCIRGpAC "This counter forms part of a safety-related signal group.
It is incremented by the task which generates the data set used in the CRC calculation, and may be used to determine the health of the data generation task.
Refer to STJLR 18.036 for more detail.";
CM_ SG_ 940 SBDCIRGpCS "This CRC shall be calculated in compliance with STJLR 18.036 Version 5.
The Data Segment Polynomial shall be constructed from the details in the network configuration file.";
CM_ SG_ 940 SBTimeLastDCIRResetHB "Time since the battery corrected its DCIR model with physical measurement, higher byte data.";
CM_ SG_ 940 SBTimeLastDCIRResetLB "Time since the battery corrected its DCIR model with physical measurement, lower byte.";
CM_ SG_ 337 SBPos1TempProtd "Temperature measured at Position 1 within the battery pack.";
CM_ SG_ 337 SBPos2TempProtd "Temperature measured at Position 2 within the battery pack.";
CM_ SG_ 337 SBSOCAbsoluteProtd "This is determined by performing the capacity measurements at the temperature for which the battery nominal capacity is defined, typically this is +25degC.";
CM_ SG_ 337 SBSOCRelativeProtd "This is determined by performing the capacity measurements at the present battery pack temperature.";
CM_ SG_ 337 SBSOHCapFadeProtd "The reduction in capacity from the rated battery capacity which has occurred to date.";
CM_ SG_ 337 SBSOHImpGrowthProtd "The % increase in discharge impedance from that expected for a new battery at agreed nominal conditions.";
CM_ SG_ 337 SBTempGpAC "This counter forms part of a safety-related signal group.
It is incremented by the task which generates the data set used in the CRC calculation, and may be used to determine the health of the data generation task.
Refer to STJLR 18.036 for more detail.";
CM_ SG_ 337 SBTempGpCS "This CRC shall be calculated in compliance with STJLR 18.036 Version 5.
The Data Segment Polynomial shall be constructed from the details in the network configuration file.";
CM_ SG_ 387 SB2BatCurr "The current measured flowing into and out of the secondary battery pack.
-ve shall be defined as current flowing out of the battery pack.
+ve shall be defined as current flowing into the battery pack.";
CM_ SG_ 387 SB2BatCurrFlt "Indicates if a fault has occurred with the secondary battery current sensor which prevents the correct current being measured or transmitted.";
CM_ SG_ 387 SB2BatVolt "This signal indicates the voltage as measured across the secondary battery terminals.";
CM_ SG_ 387 SB2BatVoltFlt "Indicates if a fault has occurred with the secondary battery terminal voltage sensor which prevents the correct voltage being measured or transmitted.";
CM_ SG_ 387 SB2CriticErr "Indicates if a critical error has occurred within the secondary battery or BMS which prevents it from performing the safety functions.";
CM_ SG_ 387 SB2ECUFlt "Indicates if a BMS ECU fault has occurred which does not affect the safe operation of the secondary battery.";
CM_ SG_ 387 SB2Pos1Temp "The temperature measured at Position 1 within the secondary battery pack.";
CM_ SG_ 387 SB2Pos2Temp "The temperature measured at Position 2 within the secondary battery pack.";
CM_ SG_ 387 SB2RelayClsFlt "Indicates whether the secondary battery isolation relay has failed such that it can no longer operate and is stuck in a closed position.";
CM_ SG_ 387 SB2RelayOpenFlt "Indicates whether the secondary battery isolation relay has failed such that it can no longer operate and is stuck in an open position.";
CM_ SG_ 387 SB2RelayStatus "Indicates the status of the secondary battery isolation relay.";
CM_ SG_ 387 SB2SOCRelative "This is determined by performing the capacity measurements at the present battery pack temperature.";
CM_ SG_ 838 SB2QChaRideCn "The total secondary battery input Ah, (I > 0), measured whilst the BMS is operating in VEH_STATE = 3. Normalised to battery rated capacity.";
CM_ SG_ 838 SB2QChaRunCn "The total secondary battery input Ah, (I > 0), measured whilst the vehicle is operating in Power Mode = 7. Normalised to battery rated capacity.";
CM_ SG_ 838 SB2QDchaRideCn "The total secondary battery output Ah, (I < 0), measured whilst the BMS is operating in VEH_STATE = 3. Normalised to battery rated capacity.";
CM_ SG_ 838 SB2QDchaRunCn "The total secondary battery output Ah, (I < 0), measured whilst the vehicle is operating in Power Mode = 7. Normalised to battery rated capacity.";
CM_ SG_ 839 SB2QDchActCn "The total secondary battery output Ah, (I < 0), measured whilst the BMS is operating in VEH_STATE = 2. Normalised to battery rated capacity.";
CM_ SG_ 839 SB2QDchActHiCn "The total secondary battery output Ah, (I < 0), measured whilst the Vehicle is operating in Power Mode = 4. Normalised to battery rated capacity.";
CM_ SG_ 839 SB2QDchEcoStpCn "The total secondary battery output Ah, (I < 0), measured whilst the Vehicle is operating in Power Mode = 7 and PowerPackStatus = 6. Normalised to battery rated capacity.";
CM_ SG_ 839 SB2QDchQdCn "The total secondary battery output Ah, (I < 0), measured whilst the BMS is operating in VEH_STATE = 1. Normalised to battery rated capacity.";
CM_ SG_ 840 SB2Cell1Volt "The voltage as measured across string 1.";
CM_ SG_ 840 SB2Cell1VoltFlt "Indicates if a fault has occurred with voltage sensor for string of parallel cells 1.";
CM_ SG_ 840 SB2Cell2Volt "The voltage as measured across string 2.";
CM_ SG_ 840 SB2Cell2VoltFlt "Indicates if a fault has occurred with voltage sensor for string of parallel cells 2.";
CM_ SG_ 840 SB2Cell3Volt "The voltage as measured across string 3.";
CM_ SG_ 840 SB2Cell3VoltFlt "Indicates if a fault has occurred with voltage sensor for string of parallel cells 3.";
CM_ SG_ 840 SB2Cell4Volt "The voltage as measured across string 4.";
CM_ SG_ 840 SB2Cell4VoltFlt "Indicates if a fault has occurred with voltage sensor for string of parallel cells 4.";
CM_ SG_ 841 SB2MaxChrgVoltLmt "The maximum voltage which may be applied at the secondary battery terminal posts and which will not cause damage and/or degradation to the battery at present conditions.";
CM_ SG_ 841 SB2PackVolt "The voltage as measured across the internal combination of the secondary battery cells but not including the isolation relay or other connections to the battery terminals.";
CM_ SG_ 841 SB2PackVoltFlt "Indicates if a fault has occurred with the secondary battery pack voltage sensor which prevents the correct voltage being measured or transmitted.";
CM_ SG_ 841 SB2Pos1TempFlt "Indicates if a fault has occurred with secondary battery temperature sensor 1 which prevents the correct temperature being measured or transmitted.";
CM_ SG_ 841 SB2Pos2TempFlt "Indicates if a fault has occurred with secondary battery temperature sensor 2 which prevents the correct temperature being measured or transmitted.";
CM_ SG_ 841 SB2SOCAbsolute "This is determined by performing the capacity measurements at the temperature for which the
battery nominal capacity is defined, typically this is +25degC.";
CM_ SG_ 841 SB2SOHCapFade "The reduction in secondary battery capacity from the rated battery capacity which has occurred to date.";
CM_ SG_ 841 SB2SOHImpGrowth "The % increase in secondary battery discharge impedance from that expected for a new battery at agreed nominal conditions.";
CM_ SG_ 335 SB2BatCurrProtdHB "The current measured flowing into and out of the battery pack. -ve shall be defined as current flowing out of the battery pack. +ve shall be defined as current flowing into the battery pack, higher byte data.";
CM_ SG_ 335 SB2BatCurrProtdLB "The current measured flowing into and out of the battery pack. -ve shall be defined as current flowing out of the battery pack. +ve shall be defined as current flowing into the battery pack, lower byte data.";
CM_ SG_ 335 SB2BatGpAC "This counter forms part of a safety-related signal group.
It is incremented by the task which generates the data set used in the CRC calculation, and may be used to determine the health of the data generation task.
Refer to STJLR 18.036 for more detail.";
CM_ SG_ 335 SB2BatGpCS "This CRC shall be calculated in compliance with STJLR 18.036 Version 5.
The Data Segment Polynomial shall be constructed from the details in the network configuration file.";
CM_ SG_ 335 SB2BatMinCurrHB "Minimum Current Observed in the last 0.5 seconds, higher byte data.";
CM_ SG_ 335 SB2BatMinCurrLB "Minimum Current Observed in the last 0.5 seconds, lower byte data.";
CM_ SG_ 335 SB2BatMinVoltHB "Minimum Terminal Voltage Observed in the last 0.5 seconds, higher byte data.";
CM_ SG_ 335 SB2BatMinVoltLB "Minimum Terminal Voltage Observed in the last 0.5 seconds, lower byte data.";
CM_ SG_ 335 SB2BatVoltProtd "This signal indicates the voltage as measured across the battery terminals.";
CM_ SG_ 945 SB2CapFadeCorr "The difference between the updated physical measurement of Capacity Fade and the prior estimate.";
CM_ SG_ 945 SB2SoCCorr "The difference between the updated physical measurement of State of Charge and the prior estimate.";
CM_ SG_ 945 SB2SoCSoHGpAC "This counter forms part of a safety-related signal group.
It is incremented by the task which generates the data set used in the CRC calculation, and may be used to determine the health of the data generation task.
Refer to STJLR 18.036 for more detail.";
CM_ SG_ 945 SB2SoCSoHGpCS "This CRC shall be calculated in compliance with STJLR 18.036 Version 5.
The Data Segment Polynomial shall be constructed from the details in the network configuration file.";
CM_ SG_ 945 SB2TimeLastSoCResetHB "Time since the battery corrected its State of charge model with physical measurement, higher byte data.";
CM_ SG_ 945 SB2TimeLastSoCResetLB "Time since the battery corrected its State of charge model with physical measurement, lower byte data.";
CM_ SG_ 945 SB2TimeLastSoHResetHB "Time since the battery corrected its State of Health model with physical measurement, higher byte data.";
CM_ SG_ 945 SB2TimeLastSoHResetLB "Time since the battery corrected its State of Health model with physical measurement, lower byte data.";
CM_ SG_ 946 SB2DCIRCorr "The difference between the updated physical measurement of DCIR and the prior estimate.";
CM_ SG_ 946 SB2DCIRGpAC "This counter forms part of a safety-related signal group.
It is incremented by the task which generates the data set used in the CRC calculation, and may be used to determine the health of the data generation task.
Refer to STJLR 18.036 for more detail.";
CM_ SG_ 946 SB2DCIRGpCS "This CRC shall be calculated in compliance with STJLR 18.036 Version 5.
The Data Segment Polynomial shall be constructed from the details in the network configuration file.";
CM_ SG_ 946 SB2TimeLastDCIRResetHB "Time since the battery corrected its DCIR model with physical measurement, higher byte data.";
CM_ SG_ 946 SB2TimeLastDCIRResetLB "Time since the battery corrected its DCIR model with physical measurement, lower byte.";
CM_ SG_ 341 SB2Pos1TempProtd "Temperature measured at Position 1 within the battery pack.";
CM_ SG_ 341 SB2Pos2TempProtd "Temperature measured at Position 2 within the battery pack.";
CM_ SG_ 341 SB2SOCAbsoluteProtd "This is determined by performing the capacity measurements at the temperature for which the battery nominal capacity is defined, typically this is +25degC.";
CM_ SG_ 341 SB2SOCRelativeProtd "This is determined by performing the capacity measurements at the present battery pack temperature.";
CM_ SG_ 341 SB2SOHCapFadeProtd "The reduction in capacity from the rated battery capacity which has occurred to date.";
CM_ SG_ 341 SB2SOHImpGrowthProtd "The % increase in discharge impedance from that expected for a new battery at agreed nominal conditions.";
CM_ SG_ 341 SB2TempGpAC "This counter forms part of a safety-related signal group.
It is incremented by the task which generates the data set used in the CRC calculation, and may be used to determine the health of the data generation task.
Refer to STJLR 18.036 for more detail.";
CM_ SG_ 341 SB2TempGpCS "This CRC shall be calculated in compliance with STJLR 18.036 Version 5.
The Data Segment Polynomial shall be constructed from the details in the network configuration file.";
CM_ SG_ 854 BISGCalibrationID01 "Sporadic Signal  - Calibration Identification for the software installed on the ECU. Format is 16 character 128 bit ASCII ($20 through $7E) Each character is 7 bits and is split over two messages. This signal comprises characters 1 to 8 of 16 characters.

128 ASCII (56 bits)
---------------------
Bit 0 to 6 = Character 1 of 16
Bit 7 to 13 = Character 2 of 16
Bit 14 to 20 = Character 3 of 16
Bit 21 to 27 = Character 4 of 16
Bit 28 to 34 = Character 5 of 16
Bit 35 to 41 = Character 6 of 16
Bit 42 to 48 = Character 7 of 16
Bit 49 to 56 = Character 8 of 16
Bit 57 to 63 = Unused
";
CM_ SG_ 855 BISGCalibrationID02 "Sporadic Signal  - Calibration Identification for the software installed on the ECU. Format is 16 character 128 bit ASCII ($20 through $7E) Each character is 7 bits  and is split over two messages. This signal comprises characters 9 to 16 of 16 characters.

128 ASCII (56 bits)
---------------------
Bit 0 to 6 = Character 9 of 16
Bit 7 to 13 = Character 10 of 16
Bit 14 to 20 = Character 11 of 16
Bit 21 to 27 = Character 12 of 16
Bit 28 to 34 = Character 13 of 16
Bit 35 to 41 = Character 14 of 16
Bit 42 to 48 = Character 15 of 16
Bit 49 to 56 = Character 16 of 16
Bit 57 to 63 = Unused
";
CM_ SG_ 856 BISGCalibVerifNumber "Sporadic Signal  - Number used to verify the integrity of the vehicle software. Consists of four Bytes values interpreted as Hexadecimal eg 0B 9F 4E D5

Hexadecimal
Bit Value  Hex Description
--------------------------------------------------------
Bit 0 to 3 (0x0 to 0xF) First Hex value (1st Byte)
Bit 4 to 7 (0x0 to 0xF) Second Hex value (1st Byte)
Bit 8 to 11 (0x0 to 0xF) Third Hex value (2nd Byte)
Bit 12 to 15 (0x0 to 0xF) Forth Hex value (2nd Byte)
Bit 16 to 19 (0x0 to 0xF) Fifth Hex value (3rd Byte)
Bit 20 to 23 (0x0 to 0xF) Sixth Hex value (3rd Byte)
Bit 24 to 27 (0x0 to 0xF) Seventh Hex value (4th Byte)
Bit 28 to 31 (0x0 to 0xF) Eighth Hex value (4th Byte)";
CM_ SG_ 856 BISGDiagnostic01 "Bit coded Diagnostic message contained in a single CAN signal. Periodically broadcast by component to the Diagnostic Service Manager

Bit 0 =    Reserved01
Bit 1 =    TORQUE_SUSPENSION [P061A-94]  [Torque suspension protection]	0 = No Fault     1 = Fault
Bit 2 =    STALLED_ROTOR_PROTECTION [P061A-97]  [Stalled rotor protection] 0 = No Fault     1 = Fault
Bit 3 =    EXC_THERMAL_TIMEOUT [P0622-63]  [Preflux_Timeout] 0 = No Fault     1 = Fault
Bit 4 =    INTERNAL [N/A]  [Thermal derating mode] 0 = No Fault     1 = Fault
Bit 5 =    INTERNAL [N/A]  [Starter warning protection] 0 = No Fault     1 = Fault
Bit 6 =    OVERHEATING [P065A-98]  [Overheating protection] 0 = No Fault     1 = Fault
Bit 7 =    OVERVOLTAGE [P0C7B -00]  [Over voltage protection on +BAT48V] 0 = No Fault     1 = Fault
Bit 8 =    LOAD_DUMP [P0A7A-1B]  [Load dump protection on +BAT48V] 0 = No Fault     1 = Fault
Bit 9 =    STATOR_OVERCURRENT [P0DFA-19]  [Stator over current protection] 0 = No Fault     1 = Fault
Bit 10 =    INTERNAL [";
CM_ SG_ 172 EMMaxContTorqueLimitMHEV "Continuous Maximum torque available from the Electric Machine in 'Torque Control' Mode.";
CM_ SG_ 172 EMMaxTorqueLimitMHEV "Instantaneous Maximum torque available from the Electric Machine in 'Torque Control' Mode.";
CM_ SG_ 172 EMMinContTorqueLimitMHEV "Continuous Minimum torque available from the Electric Machine in 'Torque Control' Mode.";
CM_ SG_ 172 EMMinTorqueLimitMHEV "Instantaneous Minimum torque available from the Electric Machine in 'Torque Control' Mode.";
CM_ SG_ 172 EMTorqLimitGpCounterMHEV "This counter forms part of a safety-related signal group.
It is incremented by the task which generates the data set used in the CRC calculation, and may be used to determine the health of the data generation task.
Refer to STJLR 18.036 for more detail.";
CM_ SG_ 172 EMTorqLimitGpCSMHEV "This CRC shall be calculated in compliance with STJLR 18.036 Version 5.
The Data Segment Polynomial shall be constructed from the details in the network configuration file.";
CM_ SG_ 174 DrvlineDampTorqueDeltaMHEV "The additional torque scheduled by the Inverter for driveline damping";
CM_ SG_ 174 EMSpeedMHEV "Speed of the Electric Machine
(Hybrid Specific Signal)";
CM_ SG_ 174 EMSpeedQFMHEV "Quality Factor for the Speed of the Electric Machine.";
CM_ SG_ 174 EMTorqSpeedExtGpCounterMHEV "This counter forms part of a safety-related signal group.
It is incremented by the task which generates the data set used in the CRC calculation, and may be used to determine the health of the data generation task.
Refer to STJLR 18.036 for more detail.";
CM_ SG_ 174 EMTorqSpeedExtGpCSMHEV "This CRC shall be calculated in compliance with STJLR 18.036 Version 5.
The Data Segment Polynomial shall be constructed from the details in the network configuration file.";
CM_ SG_ 174 EMTorqueExtMHEV "Torque of the EM machine without inertial compensation
(Hybrid Specific Signal)

Note: More precise version of the EMTorque signal.";
CM_ SG_ 160 BISGSpeed "Speed of the BISG.
";
CM_ SG_ 160 EMOperatingModeExt2 "Electrical Machine operating mode
";
CM_ SG_ 160 EMOpModeMVGpCounter "This counter forms part of a safety-related signal group.
It is incremented by the task which generates the data set used in the CRC calculation, and may be used to determine the health of the data generation task.
Refer to STJLR 18.036 for more detail.";
CM_ SG_ 160 EMOpModeMVGpCS "This CRC shall be calculated in compliance with STJLR 18.036 Version 5.
The Data Segment Polynomial shall be constructed from the details in the network configuration file.";
CM_ SG_ 160 EMVoltageDCLinkMV "MHEV DC Bus Voltage measured at the Electric Machine Inverter.
";
CM_ SG_ 275 EMVolDCLinkMaxLimitMV "Instantaneous maximum DC Link voltage allowed
";
CM_ SG_ 275 EMVolDCLinkMinLimitMV "Instantaneous minimum DC Link voltage allowed
";
CM_ SG_ 670 LVBattFanDutyRequest "Requested duty for controlling the 12V battery cooling fan speed.";
CM_ SG_ 670 LVBattFanPostRunDuty "Requested duty to set the 12V battery cooling fan speed after ignition off.";
CM_ SG_ 670 LVBattFanPostRunTime "Requested post run time for 12V battery cooling fan.";
CM_ SG_ 260 AbsThrottlePosition "Actuator A position demand";
CM_ SG_ 260 CalcLoadValue "Indicates the percent of peak available torque during normal, fault free driving conditions. Petrol and Diesel engines shall support this message. The diesel calulation is slightly different see ISO 15031-5 for this however the size and scaling is the same.

EuCD signal name
";
CM_ SG_ 260 ChargingKeyScanRes "Provide the result for key search scan if secure key detected";
CM_ SG_ 260 EngineTorqueRipple "The amplitude of torque ripple (1st Harmonic) of the engine.";
CM_ SG_ 260 GearPosActual "Actual gear position.
Note - this signal is not ASIL rated.
If in gliding this signal will read the gear that the transmission would have been in if gliding was not active.

Info: The EV Drive encoding will only be used on powertrain architectures where there is a transmission that doesn't control torque to all the wheels. e.g. D8 PHEV where the transmission controls torque the wheels on the front axle only.";
CM_ SG_ 260 OBDDriveCycle "This signal indicates that the EMS has determined the current drive cycle has met the criteria for a valid OBD drive cycle.  This signal shall be reset to 0 at start-up and shall be latched to 1 when a valid drive cycle has been achieved.
This signal should only be used for OBD diagnostics.

This signal is determined in accordance to: Title 13, California Code Regulations, Section 1968";
CM_ SG_ 260 OBDGeneralDenominator "This signal indicates that the EMS has determined the current drive cycle has been classified as a valid general OBD drive cycle.  This signal must be used to increase the denominator in the calculation of rate based monitors.  This signal shall be reset to 0 at start-up and shall be latched to 1 when the drive cycle is valid.
This signal should only be used for OBD diagnostics.

This signal is determined in accordance to: Title 13, California Code Regulations, Section 1968";
CM_ SG_ 260 OBDWarmUpCycle "This signal indicates that the EMS has determined the current drive cycle has met the criteria for a valid OBD warm up.  This signal shall be reset to 0 at start-up and shall be latched to 1 when a valid warm up cycle is achieved.
This signal should only be used for OBD diagnostics.

This signal is determined in accordance to: Title 13, California Code Regulations, Section 1968";
CM_ SG_ 260 PEChargingInletLockCmd "Passive Entry unlock request for the Plug-In Charging Socket.";
CM_ SG_ 346 ChargeCableUnlockReq "Request to unlock the charge cable by remote mobile app";
CM_ SG_ 346 ChargeFlapActn "Request to actuate power charge flap from remote mobile app";
CM_ SG_ 346 ChargeFlapActnIVI "Request to actuate power charge flap";
CM_ SG_ 346 StatusLightConfig "User configuration of Status light preference";
CM_ SG_ 8 ParkLockDataTarget "CAN signal used by TCM/EDPM to send 'Idle, challenge query' & Enable status to BCM for Start Authorisation.
";
CM_ SG_ 772 CabinCleaningReqTCU "Request for Cabin Cleaning feature Activation.";
CM_ SG_ 772 CabinCleanPreconStatTCU "Status update about Vehicle pre condition checks for remote activation";
CM_ SG_ 772 SlcEvCaReqrdEnergy "Signal giving the required energy consumption value in terms of kWh regardless of maximum battery capacity.";
CM_ SG_ 772 SlcEvCaTargetSoC "This signal indicates the Target SoC value which is required to meet user's energy requirements only for Typical day charge option.";
CM_ SG_ 607 ChargeModeAvailableExt "To restrict the Charge mode change via Charge bowl or remote app or infotainment while vehicle charging in public charging station OR vehicle doesn't have any valid timed charging settings";
CM_ SG_ 607 PairedWKeyId "The identification number of the Key ID for which Ranging needs to be performed.This signal will be set to PkeyId received from RFA in  the case when a Passive Key is used and there is no WK present which is paired with Phone.

Bit7 to Bit0= No PairedKeyID (0000 0000)
Bit0 = PairedKEYID1 (0000 0001)
Bit1 = PairedKEYID2 (0000 0010)
Bit2 = PairedKEYID3 (0000 0100)
Bit3 = PairedKEYID4 (0000 1000)
Bit4 = PairedKEYID5 (0001 0000)
Bit5 = PairedKEYID6 (0010 0000)
Bit6 = PairedKEYID7 (0100 0000)
Bit7 = PairedKEYID8 (1000 0000)";
CM_ SG_ 607 SOTAEstimatedDuration "Estimated installation duration for SOTA install event";
CM_ SG_ 607 SOTAPrepRequest "Request to start preparing subscribing modules for a SOTA installation event";
CM_ SG_ 785 eCallVoiceCallStatus "To receive the status of the voice call";
CM_ SG_ 785 UTCTimeDate "Date and time is based on Coordinated Universal Time (UTC). 

Part:  No of bits     LSB      MSB             Value range        Scaling     Offset

                             offset    offset             Min     -> Max



Year        8               40         47             2000         2254          1          2000

Month      8              32         39                0              12            1             0

Day         8              24          31                0              31            1             0

Hour        8              16          23                0              23            1             0 

Minute     8               8           15                0              59            1             0 

Second   8               0             7                0              59            1             0 

sync        4             48            51              0              15            1             0


LSB/MSB offsets are in Motorola Backwards format, and are of";
CM_ SG_ 546 SetTimer1Time "Signal with Timer1Time

SetTimer1TimeCoding:

Bit/Byte coded:

Byte 1=Month
Byte 2=Day
Byte 3=Hour
Byte 4=Minute
";
CM_ SG_ 547 SetTimer2Time "Signal with Timer2Time

SetTimer2TimeCoding:

Bit/Byte coded:

Byte 1=Month
Byte 2=Day
Byte 3=Hour
Byte 4=Minute
";
CM_ SG_ 80 KeepNetInAfterRunTCM "CAN signal stating if the network is required for After-Run.

Description of bit field detailing each application function to be stored in the DID (After-Run Function 1- 16):
Bit 0: output speed condition (n_ab)
Bit 1: position condition (PosPRND)
Bit 2: timer condition 1(tmr_PowerDown)
Bit 3: timer condition 2 (tmr_PowerDownLong)
Bit 4: SbW Display Timer condition
Bit 5 - 15: Fixwert: 0x00";
CM_ SG_ 80 ReAlignToNeutral "Request from the TCM for the GSM to reset its output of driver request to Neutral
";
CM_ SG_ 80 ReAlignToPark "Request from the TCM for the GSM to reset its output of driver request to Park";
CM_ SG_ 80 TCMLockETSReq "Used to Lock ETS for shiftlock functionality and for locking ETS in the event of transmission failure.";
CM_ SG_ 80 TCMLockGSMReq "Signal to support the GSA functions., Bit No. Description  (Bit encoded), , Bit 0 - Park at Speed Availability (P Speed lock) , , 0 = P not available , 1 = P Available, , , Bit 1 - LMC Interface Health , , 0 = Faulty , 1 = Healthy, , , Bit 2 - LMC HELD , , 0 = Vehicle not Held , 1 = Vehicle Held, , , Bit 3 - BSCM Interface Health,  , 0 = Faulty , 1 = Healthy";
CM_ SG_ 80 TCMLockGSMReqComp "Signal to support the GSA functions., Bit No. Description  (Bit encoded), , Bit 0 - Park at Speed Availability (P Speed lock), , 0 = P Available, 1 = P not available, , , Bit 1 - LMC Interface Health, , 0 = Healthy , 1 = Faulty, , , Bit 2 - LMC HELD, , 0 = Vehicle Held, 1 = Vehicle not Held , , , Bit 3 - BSCM Interface Health, , 0 = Healthy, 1 = Faulty";
CM_ SG_ 80 TCMParkReqAck "Used to inform the ETS that the TCM is processing a shift request into Park, used to check validity. Max normal shift time 0.1s. Max Shift time to Park 0.4Sec.";
CM_ SG_ 80 TCMPosAliveCounter "This counter forms part of a safety-related signal group.
It is incremented by the task which generates the data set used in the CRC calculation, and may be used to determine the health of the data generation task.
Refer to STJLR 18.036 for more detail.";
CM_ SG_ 80 TCMPosChecksum "This CRC shall be calculated in compliance with STJLR 18.036 Version 5.
The Data Segment Polynomial shall be constructed from the details in the network configuration file.";
CM_ SG_ 80 TCMPositionDisplay "Message used by IPK and ETS to display selected gear information.TCM will set multiple bits when e.g in Drive 5th gear and in Sport. The Signal TCMDrivingModeDisplay can be used for gear 1-8 display when in manual mode.

Init: Blank ETS display and Blank IPK display. Bit 14 and 15 set to 1, all other bits set to 0 (49152 decimal)

Bits 0 - 5: Gear Selection
000000 = Auto selection
000001 = 1st Gear
000010 = 2nd Gear
000100 = 3rd Gear
001000 = 4th Gear
010000 = 5th Gear
100000 = 6th Gear
100001 = 7th Gear
100010 = 8th Gear
100100 = 9th Gear

Bits 6 - 11: Gear Mode
000001 = Fault
000010 = Park  Position
000100 = Reverse Position
001000 = Neutral Position
010000 = Drive Position
100000 = Sport Position 

Bits 12 - 13: Flash Display
x1 = FLASH ETS Display
1x = FLASH IPK Display

Bits 14 - 15: Blank Display
x1 = Blank ETS Display
1x = Blank IPK Display


On Electronic Shifter installations, the TCMPositionDisplay CAN message will indicate Park as follows:      - at ignition on the";
CM_ SG_ 80 TCMStartEnable "Bit is used to inform the ETS that the TCM is a position such that engine crank is permissible. ";
CM_ SG_ 80 TCMText "The code for the current TCM Text message to be displayed. 

EuCD signal name.";
CM_ SG_ 80 TransTICStatus "Used to indicate the status of transmission Idle Control functionality

This signal is provided at a QM rating only";
CM_ SG_ 1736 UUDTBECMResponse1 "Unacknowledged Unsegmented Data Transfer Signal from the BECM to the MCD-Hub data logger. Used for rapid data transfer in compliance with:
Ford GGDS (Generic Global Diagnostic Specification).
ISO 14229
ISO 15765-3.
UUDTBECM1 shall always be packaged into CAN Identifiers 0x6C9

The timing specified within GGDS for frame transfers is:

Slow: 1000ms period
Medium: 100ms period
Fast: Specified by transmitting application supplier.

NOTE: All Volcano Timing Analysis has been performed on this signal at the Medium Rate (100ms). Any attempt to transmit the Message containing this signal at a faster rate may result in unknown delays on the vehicle CAN Bus, which could potentially disrupt normal functionality. In addition, transmission rates faster than Medium cannot be guaranteed.

The MSB of the signal must be written to the COM layer first (with an offset of zero in wr_bytes() ) and therefore transmitted on the bus first.
Similarly, subscribing modules will receive the MSB of the signal when they ca";
CM_ SG_ 1704 UUDTSGCMResponse1 "Unacknowledged Unsegmented Data Transfer Signal from the EPIC to the MCD-Hub data logger. Used for rapid data transfer in compliance with:
Ford GGDS (Generic Global Diagnostic Specification).
ISO 14229
ISO 15765-3.
UUDTEPIC1 shall always be packaged into CAN Identifiers 0x6D0

The timing specified within GGDS for frame transfers is:

Slow: 1000ms period
Medium: 100ms period
Fast: Specified by transmitting application supplier.

NOTE: All Volcano Timing Analysis has been performed on this signal at the Medium Rate (100ms). Any attempt to transmit the Message containing this signal at a faster rate may result in unknown delays on the vehicle CAN Bus, which could potentially disrupt normal functionality. In addition, transmission rates faster than Medium cannot be guaranteed.

The MSB of the signal must be written to the COM layer first (with an offset of zero in wr_bytes() ) and therefore transmitted on the bus first.
Similarly, subscribing modules will receive the MSB of the signal when they ca";
CM_ SG_ 1737 UUDTBECMResponse2 "Unacknowledged Unsegmented Data Transfer Signal from the BECM to the MCD-Hub data logger. Used for rapid data transfer in compliance with:
Ford GGDS (Generic Global Diagnostic Specification).
ISO 14229
ISO 15765-3.
UUDTBECM2 shall always be packaged into CAN Identifiers 0x6CA

The timing specified within GGDS for frame transfers is:

Slow: 1000ms period
Medium: 100ms period
Fast: Specified by transmitting application supplier.

NOTE: All Volcano Timing Analysis has been performed on this signal at the Medium Rate (100ms). Any attempt to transmit the Message containing this signal at a faster rate may result in unknown delays on the vehicle CAN Bus, which could potentially disrupt normal functionality. In addition, transmission rates faster than Medium cannot be guaranteed.

The MSB of the signal must be written to the COM layer first (with an offset of zero in wr_bytes() ) and therefore transmitted on the bus first.
Similarly, subscribing modules will receive the MSB of the signal when they ca";
CM_ SG_ 1705 UUDTSGCMResponse2 "Unacknowledged Unsegmented Data Transfer Signal from the EPIC to the MCD-Hub data logger. Used for rapid data transfer in compliance with:
Ford GGDS (Generic Global Diagnostic Specification).
ISO 14229
ISO 15765-3.
UUDTEPIC2 shall always be packaged into CAN Identifiers 0x6D1

The timing specified within GGDS for frame transfers is:

Slow: 1000ms period
Medium: 100ms period
Fast: Specified by transmitting application supplier.

NOTE: All Volcano Timing Analysis has been performed on this signal at the Medium Rate (100ms). Any attempt to transmit the Message containing this signal at a faster rate may result in unknown delays on the vehicle CAN Bus, which could potentially disrupt normal functionality. In addition, transmission rates faster than Medium cannot be guaranteed.

The MSB of the signal must be written to the COM layer first (with an offset of zero in wr_bytes() ) and therefore transmitted on the bus first.
Similarly, subscribing modules will receive the MSB of the signal when they ca";
CM_ SG_ 1738 UUDTBECMResponse3 "Unacknowledged Unsegmented Data Transfer Signal from the BECM to the MCD-Hub data logger. Used for rapid data transfer in compliance with:
Ford GGDS (Generic Global Diagnostic Specification).
ISO 14229
ISO 15765-3.
UUDTBECM3 shall always be packaged into CAN Identifiers 0x6CB

The timing specified within GGDS for frame transfers is:

Slow: 1000ms period
Medium: 100ms period
Fast: Specified by transmitting application supplier.

NOTE: All Volcano Timing Analysis has been performed on this signal at the Medium Rate (100ms). Any attempt to transmit the Message containing this signal at a faster rate may result in unknown delays on the vehicle CAN Bus, which could potentially disrupt normal functionality. In addition, transmission rates faster than Medium cannot be guaranteed.

The MSB of the signal must be written to the COM layer first (with an offset of zero in wr_bytes() ) and therefore transmitted on the bus first.
Similarly, subscribing modules will receive the MSB of the signal when they ca";
CM_ SG_ 1706 UUDTSGCMResponse3 "Unacknowledged Unsegmented Data Transfer Signal from the EPIC to the MCD-Hub data logger. Used for rapid data transfer in compliance with:
Ford GGDS (Generic Global Diagnostic Specification).
ISO 14229
ISO 15765-3.
UUDTEPIC3 shall always be packaged into CAN Identifiers 0x6D2

The timing specified within GGDS for frame transfers is:

Slow: 1000ms period
Medium: 100ms period
Fast: Specified by transmitting application supplier.

NOTE: All Volcano Timing Analysis has been performed on this signal at the Medium Rate (100ms). Any attempt to transmit the Message containing this signal at a faster rate may result in unknown delays on the vehicle CAN Bus, which could potentially disrupt normal functionality. In addition, transmission rates faster than Medium cannot be guaranteed.

The MSB of the signal must be written to the COM layer first (with an offset of zero in wr_bytes() ) and therefore transmitted on the bus first.
Similarly, subscribing modules will receive the MSB of the signal when they ca";
CM_ SG_ 1739 UUDTBECMResponse4 "Unacknowledged Unsegmented Data Transfer Signal from the BECM to the MCD-Hub data logger. Used for rapid data transfer in compliance with:
Ford GGDS (Generic Global Diagnostic Specification).
ISO 14229
ISO 15765-3.
UUDTBECM4 shall always be packaged into CAN Identifiers 0x6CC

The timing specified within GGDS for frame transfers is:

Slow: 1000ms period
Medium: 100ms period
Fast: Specified by transmitting application supplier.

NOTE: All Volcano Timing Analysis has been performed on this signal at the Medium Rate (100ms). Any attempt to transmit the Message containing this signal at a faster rate may result in unknown delays on the vehicle CAN Bus, which could potentially disrupt normal functionality. In addition, transmission rates faster than Medium cannot be guaranteed.

The MSB of the signal must be written to the COM layer first (with an offset of zero in wr_bytes() ) and therefore transmitted on the bus first.
Similarly, subscribing modules will receive the MSB of the signal when they ca";
CM_ SG_ 1707 UUDTSGCMResponse4 "Unacknowledged Unsegmented Data Transfer Signal from the EPIC to the MCD-Hub data logger. Used for rapid data transfer in compliance with:
Ford GGDS (Generic Global Diagnostic Specification).
ISO 14229
ISO 15765-3.
UUDTEPIC4 shall always be packaged into CAN Identifiers 0x6D3

The timing specified within GGDS for frame transfers is:

Slow: 1000ms period
Medium: 100ms period
Fast: Specified by transmitting application supplier.

NOTE: All Volcano Timing Analysis has been performed on this signal at the Medium Rate (100ms). Any attempt to transmit the Message containing this signal at a faster rate may result in unknown delays on the vehicle CAN Bus, which could potentially disrupt normal functionality. In addition, transmission rates faster than Medium cannot be guaranteed.

The MSB of the signal must be written to the COM layer first (with an offset of zero in wr_bytes() ) and therefore transmitted on the bus first.
Similarly, subscribing modules will receive the MSB of the signal when they ca";
CM_ SG_ 1024 CcfAlternator "Car Configuration Alternator type

Payload 0x0187";
CM_ SG_ 1024 CcfBifuel "CCF Parameter - Bifuel

MDF - 0x0157";
CM_ SG_ 1024 CcfDoors "Car Configuration - Doors

MDF = 0x0137";
CM_ SG_ 1024 CcfEngine "Car Configuration - Engine

Payload MDF = 0x0167";
CM_ SG_ 1024 CcfFuel "Car Configuration - Fuel

Payload MDF = 0x0177";
CM_ SG_ 1024 CcfTransmissionDriveLn "Car Configuration - TRANSMISSION  - DRIVELINE

Payload MDF = 0x0147";
CM_ SG_ 1024 CcfVehicleType "Car Configuration - Vehicle Type

Payload MDF = 0x0127";
CM_ SG_ 1024 CcfAlarm "CCF Parameter - ALARM

MDF - 0x0267";
CM_ SG_ 1024 CcfFuelTankVolume "CCF Parameter - FUEL TANK VOLUME

MDF - 0x0257";
CM_ SG_ 1024 CcfGearbox "Car Configuration - Gearbox

Payload MDF = 0x0237";
CM_ SG_ 1024 CcfGearboxType "Car Configuration - Gearbox Type

Payload MDF = 0x0247";
CM_ SG_ 1024 CcfHeadlightsType "CCF Parameter - HEADLIGHTS TYPE

MDF - 0x0287";
CM_ SG_ 1024 CcfSeatMassage "CCF Parameter - Seat Massage

MDF - 0x0277";
CM_ SG_ 1024 CcfSteeringWheelPosn "Car Configuration - Steering Wheel Position

Payload MDF = 0x0227";
CM_ SG_ 1024 CcfAdditionalHeater "CCF Parameter Name - Additional Heater

Payload MDF = 0x0427";
CM_ SG_ 1024 CcfCruiseControl "Car Configuration - Cruise Control

Payload MDF = 0x0437";
CM_ SG_ 1024 CcfHeadlightCleaning "CCF Parameter - HEADLIGHT CLEANING

MDF - 0x0457";
CM_ SG_ 1024 CcfPowerSteeringType "CCF Parameter Name - POWER STEERING TYPE

Payload MDF = 0x0467";
CM_ SG_ 1024 CcfPrivateLockingTrunk "CCF Parameter - PRIVATE LOCKING TRUNK

MDF - 0x0487";
CM_ SG_ 1024 CcfRainSensor "CCF Parameter - RAINSENSOR

MDF - 0x0447";
CM_ SG_ 1024 CcfTripComputer "CCF Parameter - TRIP COMPUTER

MDF - 0x0477";
CM_ SG_ 1024 CcfBatteryRear "CCF Parameter - BATTERY REAR

MDF - 0x0667";
CM_ SG_ 1024 CcfBlindSpotInfoSystem "CCF BLIND SPOT INFORMATION SYSTEM

 MDF 0x0637";
CM_ SG_ 1024 CcfClimateControlUnit "Car Configuration - CLIMATE CONTROL UNIT

Payload MDF = 0x0687";
CM_ SG_ 1024 CcfCoupeFilter "CCF Parameter - COUPE FILTER

MDF - 0x0677";
CM_ SG_ 1024 CcfPanicAlarm "CCF Parameter - PANIC ALARM

MDF - 0x0627";
CM_ SG_ 1024 CcfPPTCHeater "Car Configuration - PTC HEATER (SUPPLEMENTARY AIR HEATER)

Payload MDF = 0x0657";
CM_ SG_ 1024 CcfRoadFrictionDetection "CCF Parameter - ROAD FRICTION DETECTION

MDF - 0x0647";
CM_ SG_ 1024 CcfHeartbeatSensor "CCF Parameter - HEARTBEAT SENSOR

MDF - 0x0777";
CM_ SG_ 1024 CcfHeatedRearSeat "Car Configuration - HEATED REAR SEAT

Payload MDF = 0x0787";
CM_ SG_ 1024 CcfInstrumentClusterCal "CCF Parameter - INSTRUMENT CLUSTER CALIBRATION

MDF - 0x0747";
CM_ SG_ 1024 CcfInteriorMotionSensor "CCF Parameter - INTERIOR MOTION SENSOR

MDF - 0x0767";
CM_ SG_ 1024 CcfSpeedLimitation "CCF Parameter - SPEED LIMITATION

MDF - 0x0727";
CM_ SG_ 1024 CcfSpeedWarningDevice "CCF Parameter - SPEED WARNING DEVICE

MDF - 0x0737";
CM_ SG_ 1024 CcfWheelBrakesTypeFront "CCF Parameter - WHEEL BRAKES TYPE FRONT

MDF - 0x0757";
CM_ SG_ 1024 CcfCallstartOfParkHeat "Car Configuration - CALLSTART OF PARKING HEATER

Payload MDF = 0x0887";
CM_ SG_ 1024 CcfFrontSeatVentilation "CCF Parameter - FRONT SEAT VENTILATION

MDF - 0x0877";
CM_ SG_ 1024 CcfHeatedFrontSeats "Car Configuration - HEATED FRONT SEATS

Payload MDF = 0x0867";
CM_ SG_ 1024 CcfSeatHeatCalibration "Car Configuration - SEAT HEAT CALIBRATION

Payload MDF = 0x0857";
CM_ SG_ 1024 CcfServiceInt "CCF Parameter - SERVICE INTERVAL

MDF - 0x0847";
CM_ SG_ 1024 CcfTelephone "CCF Parameter - Telephone

MDF - 0x0827";
BA_DEF_ BO_  "GenMsgCycleTime" FLOAT 0 300000;
BA_DEF_ BO_  "GenMsgDelayTime" FLOAT 0 300000;
BA_DEF_ BO_  "GenMsgSendType" ENUM  "cyclic","spontaneous","cyclicIfActive","spontaneousWithDelay","cyclicAndSpontaneous","cyclicAndSpontaneousWithDelay","IfActive","NoMsgSendType";
BA_DEF_ BO_  "GenMsgStartDelayTime" FLOAT 0 300000;
BA_DEF_ SG_  "GenSigSendType" ENUM  "Cyclic","OnWrite","OnWriteWithRepetition","OnChange","OnChangeWithRepetition","IfActive","IfActiveWithRepetition","NoSigSendType";
BA_DEF_ SG_  "GenSigStartValue" FLOAT -1.79769313486232E+308 1.84467440737096E+019;
BA_DEF_ BO_  "SystemMessageLongSymbol" STRING ;
BA_DEF_DEF_  "GenMsgCycleTime" 0;
BA_DEF_DEF_  "GenMsgDelayTime" 0;
BA_DEF_DEF_  "GenMsgSendType" "cyclic";
BA_DEF_DEF_  "GenMsgStartDelayTime" 0;
BA_DEF_DEF_  "GenSigSendType" "Cyclic";
BA_DEF_DEF_  "GenSigStartValue" 0;
BA_DEF_DEF_  "SystemMessageLongSymbol" "";
BA_ "GenMsgSendType" BO_ 132 1;
BA_ "GenMsgDelayTime" BO_ 132 20;
BA_ "GenMsgSendType" BO_ 733 1;
BA_ "GenMsgDelayTime" BO_ 733 10;
BA_ "GenMsgSendType" BO_ 54 1;
BA_ "GenMsgDelayTime" BO_ 54 20;
BA_ "GenMsgSendType" BO_ 13 1;
BA_ "GenMsgDelayTime" BO_ 13 10;
BA_ "GenMsgSendType" BO_ 853 1;
BA_ "GenMsgDelayTime" BO_ 853 500;
BA_ "GenMsgCycleTime" BO_ 347 20;
BA_ "GenMsgCycleTime" BO_ 41 20;
BA_ "GenMsgCycleTime" BO_ 122 20;
BA_ "GenMsgCycleTime" BO_ 156 20;
BA_ "GenMsgCycleTime" BO_ 162 10;
BA_ "GenMsgCycleTime" BO_ 352 100;
BA_ "GenMsgCycleTime" BO_ 354 100;
BA_ "GenMsgSendType" BO_ 743 1;
BA_ "GenMsgDelayTime" BO_ 743 300;
BA_ "GenMsgCycleTime" BO_ 304 100;
BA_ "GenMsgCycleTime" BO_ 356 100;
BA_ "GenMsgSendType" BO_ 170 1;
BA_ "GenMsgDelayTime" BO_ 170 10;
BA_ "GenMsgCycleTime" BO_ 219 20;
BA_ "GenMsgSendType" BO_ 239 1;
BA_ "GenMsgDelayTime" BO_ 239 80;
BA_ "GenMsgSendType" BO_ 1442 1;
BA_ "GenMsgDelayTime" BO_ 1442 500;
BA_ "GenMsgSendType" BO_ 1438 1;
BA_ "GenMsgDelayTime" BO_ 1438 500;
BA_ "GenMsgSendType" BO_ 1310 1;
BA_ "GenMsgDelayTime" BO_ 1310 500;
BA_ "GenMsgSendType" BO_ 1411 1;
BA_ "GenMsgDelayTime" BO_ 1411 500;
BA_ "GenMsgSendType" BO_ 1429 1;
BA_ "GenMsgDelayTime" BO_ 1429 500;
BA_ "GenMsgSendType" BO_ 1428 1;
BA_ "GenMsgDelayTime" BO_ 1428 500;
BA_ "GenMsgSendType" BO_ 1535 1;
BA_ "GenMsgDelayTime" BO_ 1535 500;
BA_ "GenMsgSendType" BO_ 1407 1;
BA_ "GenMsgDelayTime" BO_ 1407 500;
BA_ "GenMsgSendType" BO_ 562 1;
BA_ "GenMsgSendType" BO_ 712 1;
BA_ "GenMsgSendType" BO_ 707 1;
BA_ "GenMsgDelayTime" BO_ 707 5;
BA_ "GenMsgSendType" BO_ 708 1;
BA_ "GenMsgSendType" BO_ 711 1;
BA_ "GenMsgSendType" BO_ 565 1;
BA_ "GenMsgSendType" BO_ 569 1;
BA_ "GenMsgSendType" BO_ 573 1;
BA_ "GenMsgSendType" BO_ 579 1;
BA_ "GenMsgSendType" BO_ 594 1;
BA_ "GenMsgSendType" BO_ 709 1;
BA_ "GenMsgSendType" BO_ 710 1;
BA_ "GenMsgSendType" BO_ 191 1;
BA_ "GenMsgDelayTime" BO_ 191 10;
BA_ "GenMsgCycleTime" BO_ 738 400;
BA_ "GenMsgCycleTime" BO_ 739 400;
BA_ "GenMsgCycleTime" BO_ 740 400;
BA_ "GenMsgCycleTime" BO_ 790 400;
BA_ "GenMsgCycleTime" BO_ 791 400;
BA_ "GenMsgSendType" BO_ 325 1;
BA_ "GenMsgDelayTime" BO_ 325 80;
BA_ "GenMsgSendType" BO_ 939 1;
BA_ "GenMsgDelayTime" BO_ 939 1000;
BA_ "GenMsgSendType" BO_ 940 1;
BA_ "GenMsgDelayTime" BO_ 940 1000;
BA_ "GenMsgSendType" BO_ 337 1;
BA_ "GenMsgDelayTime" BO_ 337 80;
BA_ "GenMsgCycleTime" BO_ 387 50;
BA_ "GenMsgCycleTime" BO_ 838 500;
BA_ "GenMsgCycleTime" BO_ 839 500;
BA_ "GenMsgCycleTime" BO_ 840 400;
BA_ "GenMsgCycleTime" BO_ 841 400;
BA_ "GenMsgSendType" BO_ 335 1;
BA_ "GenMsgDelayTime" BO_ 335 80;
BA_ "GenMsgSendType" BO_ 945 1;
BA_ "GenMsgDelayTime" BO_ 945 1000;
BA_ "GenMsgSendType" BO_ 946 1;
BA_ "GenMsgDelayTime" BO_ 946 1000;
BA_ "GenMsgSendType" BO_ 341 1;
BA_ "GenMsgDelayTime" BO_ 341 80;
BA_ "GenMsgSendType" BO_ 854 1;
BA_ "GenMsgDelayTime" BO_ 854 500;
BA_ "GenMsgSendType" BO_ 855 1;
BA_ "GenMsgDelayTime" BO_ 855 500;
BA_ "GenMsgSendType" BO_ 856 1;
BA_ "GenMsgDelayTime" BO_ 856 500;
BA_ "GenMsgCycleTime" BO_ 172 20;
BA_ "GenMsgCycleTime" BO_ 174 20;
BA_ "GenMsgCycleTime" BO_ 160 20;
BA_ "GenMsgCycleTime" BO_ 275 50;
BA_ "GenMsgCycleTime" BO_ 670 100;
BA_ "GenMsgCycleTime" BO_ 260 40;
BA_ "GenMsgSendType" BO_ 346 1;
BA_ "GenMsgDelayTime" BO_ 346 60;
BA_ "GenMsgSendType" BO_ 8 1;
BA_ "GenMsgDelayTime" BO_ 8 10;
BA_ "GenMsgSendType" BO_ 772 1;
BA_ "GenMsgDelayTime" BO_ 772 400;
BA_ "GenMsgSendType" BO_ 607 1;
BA_ "GenMsgDelayTime" BO_ 607 320;
BA_ "GenMsgSendType" BO_ 785 1;
BA_ "GenMsgDelayTime" BO_ 785 320;
BA_ "GenMsgSendType" BO_ 546 1;
BA_ "GenMsgDelayTime" BO_ 546 995;
BA_ "GenMsgSendType" BO_ 547 1;
BA_ "GenMsgDelayTime" BO_ 547 995;
BA_ "GenMsgSendType" BO_ 80 1;
BA_ "GenMsgDelayTime" BO_ 80 20;
BA_ "GenMsgSendType" BO_ 2015 1;
BA_ "GenMsgSendType" BO_ 2021 1;
BA_ "GenMsgSendType" BO_ 1830 1;
BA_ "GenMsgSendType" BO_ 2020 1;
BA_ "GenMsgSendType" BO_ 1861 1;
BA_ "GenMsgSendType" BO_ 1875 1;
BA_ "GenMsgSendType" BO_ 1843 1;
BA_ "GenMsgSendType" BO_ 1909 1;
BA_ "GenMsgSendType" BO_ 1920 1;
BA_ "GenMsgSendType" BO_ 1831 1;
BA_ "GenMsgSendType" BO_ 1838 1;
BA_ "GenMsgDelayTime" BO_ 1838 10;
BA_ "GenMsgSendType" BO_ 2028 1;
BA_ "GenMsgSendType" BO_ 1883 1;
BA_ "GenMsgSendType" BO_ 1851 1;
BA_ "GenMsgSendType" BO_ 1928 1;
BA_ "GenMsgSendType" BO_ 1736 1;
BA_ "GenMsgDelayTime" BO_ 1736 50;
BA_ "GenMsgSendType" BO_ 1704 1;
BA_ "GenMsgDelayTime" BO_ 1704 45;
BA_ "GenMsgSendType" BO_ 1737 1;
BA_ "GenMsgDelayTime" BO_ 1737 50;
BA_ "GenMsgSendType" BO_ 1705 1;
BA_ "GenMsgDelayTime" BO_ 1705 45;
BA_ "GenMsgSendType" BO_ 1738 1;
BA_ "GenMsgDelayTime" BO_ 1738 50;
BA_ "GenMsgSendType" BO_ 1706 1;
BA_ "GenMsgDelayTime" BO_ 1706 45;
BA_ "GenMsgSendType" BO_ 1739 1;
BA_ "GenMsgDelayTime" BO_ 1739 50;
BA_ "GenMsgSendType" BO_ 1707 1;
BA_ "GenMsgDelayTime" BO_ 1707 45;
BA_ "GenMsgSendType" BO_ 1024 1;
BA_ "GenMsgDelayTime" BO_ 1024 5;
BA_ "GenSigStartValue" SG_ 132 EngineSpeedQF 1;
BA_ "GenSigStartValue" SG_ 733 DrvlineDampTorqMinLim 1023;
BA_ "GenSigStartValue" SG_ 54 PedalPosProQF 1;
BA_ "GenSigStartValue" SG_ 13 WheelTorqTgtWoIntF 1000;
BA_ "GenSigStartValue" SG_ 13 WheelTorqTgtWoIntR 1000;
BA_ "GenSigSendType" SG_ 853 BISGCalibrationIDReq 1;
BA_ "GenSigStartValue" SG_ 347 DCDCVoltage12vLimit 254;
BA_ "GenSigStartValue" SG_ 156 EMDurationMaxESA 2;
BA_ "GenSigStartValue" SG_ 156 EMEndSpeedESA 50;
BA_ "GenSigStartValue" SG_ 156 EMTorqueGradientNeg 73;
BA_ "GenSigStartValue" SG_ 156 EMTorqueGradientPos 73;
BA_ "GenSigStartValue" SG_ 156 EMTorqueLimitESA 44;
BA_ "GenSigSendType" SG_ 743 MVBattCalibrationIDReq 1;
BA_ "GenSigStartValue" SG_ 356 HVBattPumpDRReq 10;
BA_ "GenSigStartValue" SG_ 170 EMOperatingModeReqExt 4;
BA_ "GenSigStartValue" SG_ 170 EMTorqueRequestExt 16383;
BA_ "GenSigStartValue" SG_ 239 AmbientAirPressureQF 1;
BA_ "GenSigStartValue" SG_ 239 AmbientTempQF 1;
BA_ "GenSigStartValue" SG_ 239 EngineCoolantTempQF 1;
BA_ "GenSigStartValue" SG_ 239 EngineOilTempQF 1;
BA_ "GenSigStartValue" SG_ 191 VerticalAcceleration 2048;
BA_ "GenSigStartValue" SG_ 738 SBBatVolt 140;
BA_ "GenSigStartValue" SG_ 738 SBPos1Temp 10;
BA_ "GenSigStartValue" SG_ 738 SBPos2Temp 10;
BA_ "GenSigStartValue" SG_ 738 SBRelayStatus 1;
BA_ "GenSigStartValue" SG_ 738 SBSOCRelative 90;
BA_ "GenSigStartValue" SG_ 790 SBCell1Volt 100;
BA_ "GenSigStartValue" SG_ 790 SBCell2Volt 100;
BA_ "GenSigStartValue" SG_ 790 SBCell3Volt 100;
BA_ "GenSigStartValue" SG_ 790 SBCell4Volt 100;
BA_ "GenSigStartValue" SG_ 791 SBMaxChrgVoltLmt 136;
BA_ "GenSigStartValue" SG_ 791 SBPackVolt 140;
BA_ "GenSigStartValue" SG_ 791 SBSOCAbsolute 90;
BA_ "GenSigStartValue" SG_ 325 SBBatCurrProtdHB 31;
BA_ "GenSigStartValue" SG_ 325 SBBatCurrProtdLB 240;
BA_ "GenSigStartValue" SG_ 325 SBBatMinCurrHB 255;
BA_ "GenSigStartValue" SG_ 325 SBBatMinCurrLB 255;
BA_ "GenSigStartValue" SG_ 325 SBBatMinVoltHB 7;
BA_ "GenSigStartValue" SG_ 325 SBBatMinVoltLB 255;
BA_ "GenSigStartValue" SG_ 325 SBBatVoltProtd 140;
BA_ "GenSigStartValue" SG_ 939 SBCapFadeCorr 127;
BA_ "GenSigStartValue" SG_ 939 SBSoCCorr 127;
BA_ "GenSigStartValue" SG_ 939 SBTimeLastSoCResetHB 127;
BA_ "GenSigStartValue" SG_ 939 SBTimeLastSoCResetLB 255;
BA_ "GenSigStartValue" SG_ 939 SBTimeLastSoHResetHB 127;
BA_ "GenSigStartValue" SG_ 939 SBTimeLastSoHResetLB 255;
BA_ "GenSigStartValue" SG_ 940 SBDCIRCorr 127;
BA_ "GenSigStartValue" SG_ 940 SBTimeLastDCIRResetHB 127;
BA_ "GenSigStartValue" SG_ 940 SBTimeLastDCIRResetLB 255;
BA_ "GenSigStartValue" SG_ 337 SBPos1TempProtd 50;
BA_ "GenSigStartValue" SG_ 337 SBPos2TempProtd 50;
BA_ "GenSigStartValue" SG_ 337 SBSOCAbsoluteProtd 127;
BA_ "GenSigStartValue" SG_ 337 SBSOCRelativeProtd 127;
BA_ "GenSigStartValue" SG_ 337 SBSOHCapFadeProtd 127;
BA_ "GenSigStartValue" SG_ 337 SBSOHImpGrowthProtd 127;
BA_ "GenSigStartValue" SG_ 387 SB2BatVolt 140;
BA_ "GenSigStartValue" SG_ 387 SB2Pos1Temp 10;
BA_ "GenSigStartValue" SG_ 387 SB2Pos2Temp 10;
BA_ "GenSigStartValue" SG_ 387 SB2RelayStatus 1;
BA_ "GenSigStartValue" SG_ 387 SB2SOCRelative 90;
BA_ "GenSigStartValue" SG_ 840 SB2Cell1Volt 100;
BA_ "GenSigStartValue" SG_ 840 SB2Cell2Volt 100;
BA_ "GenSigStartValue" SG_ 840 SB2Cell3Volt 100;
BA_ "GenSigStartValue" SG_ 840 SB2Cell4Volt 100;
BA_ "GenSigStartValue" SG_ 841 SB2MaxChrgVoltLmt 136;
BA_ "GenSigStartValue" SG_ 841 SB2PackVolt 140;
BA_ "GenSigStartValue" SG_ 841 SB2SOCAbsolute 90;
BA_ "GenSigStartValue" SG_ 335 SB2BatCurrProtdHB 31;
BA_ "GenSigStartValue" SG_ 335 SB2BatCurrProtdLB 240;
BA_ "GenSigStartValue" SG_ 335 SB2BatMinCurrHB 255;
BA_ "GenSigStartValue" SG_ 335 SB2BatMinCurrLB 255;
BA_ "GenSigStartValue" SG_ 335 SB2BatMinVoltHB 7;
BA_ "GenSigStartValue" SG_ 335 SB2BatMinVoltLB 255;
BA_ "GenSigStartValue" SG_ 335 SB2BatVoltProtd 140;
BA_ "GenSigStartValue" SG_ 945 SB2CapFadeCorr 127;
BA_ "GenSigStartValue" SG_ 945 SB2SoCCorr 127;
BA_ "GenSigStartValue" SG_ 945 SB2TimeLastSoCResetHB 127;
BA_ "GenSigStartValue" SG_ 945 SB2TimeLastSoCResetLB 255;
BA_ "GenSigStartValue" SG_ 945 SB2TimeLastSoHResetHB 127;
BA_ "GenSigStartValue" SG_ 945 SB2TimeLastSoHResetLB 255;
BA_ "GenSigStartValue" SG_ 946 SB2DCIRCorr 127;
BA_ "GenSigStartValue" SG_ 946 SB2TimeLastDCIRResetHB 127;
BA_ "GenSigStartValue" SG_ 946 SB2TimeLastDCIRResetLB 255;
BA_ "GenSigStartValue" SG_ 341 SB2Pos1TempProtd 50;
BA_ "GenSigStartValue" SG_ 341 SB2Pos2TempProtd 50;
BA_ "GenSigStartValue" SG_ 341 SB2SOCAbsoluteProtd 127;
BA_ "GenSigStartValue" SG_ 341 SB2SOCRelativeProtd 127;
BA_ "GenSigStartValue" SG_ 341 SB2SOHCapFadeProtd 127;
BA_ "GenSigStartValue" SG_ 341 SB2SOHImpGrowthProtd 127;
BA_ "GenSigSendType" SG_ 854 BISGCalibrationID01 1;
BA_ "GenSigSendType" SG_ 855 BISGCalibrationID02 1;
BA_ "GenSigSendType" SG_ 856 BISGCalibVerifNumber 1;
BA_ "GenSigSendType" SG_ 856 BISGDiagnostic01 1;
BA_ "GenSigStartValue" SG_ 172 EMMinTorqueLimitMHEV 1023;
BA_ "GenSigStartValue" SG_ 174 EMSpeedQFMHEV 1;
BA_ "GenSigStartValue" SG_ 160 EMOperatingModeExt2 14;
BA_ "GenSigSendType" SG_ 346 ChargeCableUnlockReq 1;
BA_ "GenSigSendType" SG_ 346 ChargeFlapActn 1;
BA_ "GenSigSendType" SG_ 346 ChargeFlapActnIVI 1;
BA_ "GenSigSendType" SG_ 346 StatusLightConfig 1;
BA_ "GenSigSendType" SG_ 8 ParkLockDataTarget 1;
BA_ "GenSigSendType" SG_ 546 SetTimer1Time 1;
BA_ "GenSigSendType" SG_ 547 SetTimer2Time 1;
BA_ "GenSigStartValue" SG_ 80 ReAlignToNeutral 1;
BA_ "GenSigStartValue" SG_ 80 ReAlignToPark 1;
BA_ "GenSigStartValue" SG_ 80 TCMLockGSMReqComp 15;
BA_ "GenSigStartValue" SG_ 80 TCMPositionDisplay 49152;
BA_ "GenSigSendType" SG_ 1736 UUDTBECMResponse1 1;
BA_ "GenSigSendType" SG_ 1704 UUDTSGCMResponse1 1;
BA_ "GenSigSendType" SG_ 1737 UUDTBECMResponse2 1;
BA_ "GenSigSendType" SG_ 1705 UUDTSGCMResponse2 1;
BA_ "GenSigSendType" SG_ 1738 UUDTBECMResponse3 1;
BA_ "GenSigSendType" SG_ 1706 UUDTSGCMResponse3 1;
BA_ "GenSigSendType" SG_ 1739 UUDTBECMResponse4 1;
BA_ "GenSigSendType" SG_ 1707 UUDTSGCMResponse4 1;
BA_ "GenSigSendType" SG_ 1024 CcfAlternator 1;
BA_ "GenSigSendType" SG_ 1024 CcfBifuel 1;
BA_ "GenSigSendType" SG_ 1024 CcfDoors 1;
BA_ "GenSigSendType" SG_ 1024 CcfEngine 1;
BA_ "GenSigSendType" SG_ 1024 CcfFuel 1;
BA_ "GenSigSendType" SG_ 1024 CcfTransmissionDriveLn 1;
BA_ "GenSigSendType" SG_ 1024 CcfVehicleType 1;
BA_ "GenSigSendType" SG_ 1024 CcfAlarm 1;
BA_ "GenSigSendType" SG_ 1024 CcfFuelTankVolume 1;
BA_ "GenSigSendType" SG_ 1024 CcfGearbox 1;
BA_ "GenSigSendType" SG_ 1024 CcfGearboxType 1;
BA_ "GenSigSendType" SG_ 1024 CcfHeadlightsType 1;
BA_ "GenSigSendType" SG_ 1024 CcfSeatMassage 1;
BA_ "GenSigSendType" SG_ 1024 CcfSteeringWheelPosn 1;
BA_ "GenSigSendType" SG_ 1024 CcfAdditionalHeater 1;
BA_ "GenSigSendType" SG_ 1024 CcfCruiseControl 1;
BA_ "GenSigSendType" SG_ 1024 CcfHeadlightCleaning 1;
BA_ "GenSigSendType" SG_ 1024 CcfPowerSteeringType 1;
BA_ "GenSigSendType" SG_ 1024 CcfPrivateLockingTrunk 1;
BA_ "GenSigSendType" SG_ 1024 CcfRainSensor 1;
BA_ "GenSigSendType" SG_ 1024 CcfTripComputer 1;
BA_ "GenSigSendType" SG_ 1024 CcfBatteryRear 1;
BA_ "GenSigSendType" SG_ 1024 CcfBlindSpotInfoSystem 1;
BA_ "GenSigSendType" SG_ 1024 CcfClimateControlUnit 1;
BA_ "GenSigSendType" SG_ 1024 CcfCoupeFilter 1;
BA_ "GenSigSendType" SG_ 1024 CcfPanicAlarm 1;
BA_ "GenSigSendType" SG_ 1024 CcfPPTCHeater 1;
BA_ "GenSigSendType" SG_ 1024 CcfRoadFrictionDetection 1;
BA_ "GenSigSendType" SG_ 1024 CcfHeartbeatSensor 1;
BA_ "GenSigSendType" SG_ 1024 CcfHeatedRearSeat 1;
BA_ "GenSigSendType" SG_ 1024 CcfInstrumentClusterCal 1;
BA_ "GenSigSendType" SG_ 1024 CcfInteriorMotionSensor 1;
BA_ "GenSigSendType" SG_ 1024 CcfSpeedLimitation 1;
BA_ "GenSigSendType" SG_ 1024 CcfSpeedWarningDevice 1;
BA_ "GenSigSendType" SG_ 1024 CcfWheelBrakesTypeFront 1;
BA_ "GenSigSendType" SG_ 1024 CcfCallstartOfParkHeat 1;
BA_ "GenSigSendType" SG_ 1024 CcfFrontSeatVentilation 1;
BA_ "GenSigSendType" SG_ 1024 CcfHeatedFrontSeats 1;
BA_ "GenSigSendType" SG_ 1024 CcfSeatHeatCalibration 1;
BA_ "GenSigSendType" SG_ 1024 CcfServiceInt 1;
BA_ "GenSigSendType" SG_ 1024 CcfTelephone 1;
VAL_ 132 BrakeSwitchStatus 0 "Normal Condition" 1 "Brake Pedal Pressed" 2 "(Undefined)" 3 "Brake Switch Fault" ;
VAL_ 132 EngineSpeedQF 0 "The accuracy of the data is undefinable" 1 "Data is temporarily undefinable, evaluation in progress" 2 "The accuracy of the data is not within specification" 3 "The data is calculated with the specified accuracy" ;
VAL_ 132 MHStopStartStatus 0 "STARTUP" 1 "DEACTIVATED" 2 "DESELECTED" 3 "STOP AVAILABLE" 4 "STOP NOT AVAILABLE" 5 "STOPPED" 6 "PRESS CLUTCH PEDAL" 7 "SELECT NEUTRAL" 8 "PRESS BRAKE PEDAL" 9 "IMMINENT START WARNING" 10 "ERROR" 11 "EXT TEMP" 12 "DPF REGEN" 13 "BATT CHARGE" 14 "SYS DEMAND" 15 "A/C DEMAND" ;
VAL_ 132 PowerPackStatus 0 "Init" 1 "Awake" 2 "Ready" 3 "PreStarting" 4 "StartingInProgress" 5 "Running_Running" 6 "Running_Standby" 7 "Running_StartingInProgress" 8 "Running_RemoteStarted" 9 "AfterRun" ;
VAL_ 733 EMTorqueMaxLimit 1022 "Initialisation" 1023 "Failure" ;
VAL_ 733 EMTorqueMinLimit 1022 "Initialisation" 1023 "Failure" ;
VAL_ 54 PedalPosProQF 0 "The accuracy of the data is undefinable" 1 "Data is temporarily undefinable, evaluation in progress" 2 "The accuracy of the data is not within specification" 3 "The data is calculated with the specified accuracy" ;
VAL_ 13 VSCHoldRequest 0 "Brake Hold NOT requested" 1 "Brake Hold requested" ;
VAL_ 853 BISGCalibrationIDReq 0 "Not Active" 1 "Active" ;
VAL_ 347 DCDCOperatingModeReqEx 0 "Standby" 1 "Buck Mode" 2 "Reserved (Boost Mode)" 3 "Bus Discharge Mode" 4 "Reserved (Bus Test Mode)" 5 "Not Used5" 6 "Not Used6" 7 "Not Used7" ;
VAL_ 347 DCDCVoltage12vLimit 254 "Initialisation" 255 "Failure" ;
VAL_ 41 EMCurDcLinkGenLimit 510 "Initialisation" 511 "Failure" ;
VAL_ 41 EMVolDcLinkGenLimit 1022 "Initialisation" 1023 "Failure" ;
VAL_ 122 EMCurDcLinkMotorLimit 510 "Initialisation" 511 "Failure" ;
VAL_ 122 EMVolDcLinkMotorLimit 1022 "Initialisation" 1023 "Failure" ;
VAL_ 162 HVBattAllowWakeUpDch 0 "Not allowed" 1 "Allowed" ;
VAL_ 162 HVBattContactorRequest 0 "Open" 1 "Closed" ;
VAL_ 162 HybridMode 0 "Standby" 1 "Engine Only" 2 "Hybrid Battery Only" 3 "Driver selected EV mode" 4 "Engine and Battery" 5 "Regenerative Braking" 6 "APU charging" 7 "Stopped - Engine on, not charging" 8 "Stopped - Engine on, charging" 9 "Stopped - Engine off" 10 "Plugged in, not charging" 11 "Plugged in, charging" 12 "Plugged in, finished charging" 13 "Hybrid Inhibit" 14 "Request Special Programs Off" 15 "Reserved 3" ;
VAL_ 162 MVBattTOCRStatus 0 "TOCR Strategy Not Active" 1 "Soft TOCR Strategy Active" 2 "Hard TOCR Strategy Active" 3 "Failed" ;
VAL_ 354 VSCHVBattCoolingReq 0 "Does NOT require chiller cooling" 1 "Requires chiller cooling" 2 "Critically requires chiller cooling" ;
VAL_ 743 MVBattCalibrationIDReq 0 "Not Active" 1 "Active" ;
VAL_ 304 eDriveCoolantLevel 0 "OK" 1 "LOW" ;
VAL_ 170 EMOperatingModeReqExt 0 "Standby" 1 "Torque Mode" 2 "Reserved (Speed Mode)" 3 "Voltage Mode" 4 "Bus Test Mode" 5 "Unused5" 6 "Reserved (Calibration Mode)" 7 "Reserved (Bus Discharge Mode)" 8 "Life Saver Mode" 9 "Preflux Mode" 10 "Engine Stop Assist Mode - ESA" 11 "Unused11" 12 "Unused12" 13 "Safe State Request" 14 "Unused14" 15 "Unused15" ;
VAL_ 170 EMSpeedRequestExt 32766 "Initialisation" 32767 "Failure" ;
VAL_ 170 EMVoltageDCLinkReqExt 1022 "Initialisation" 1023 "Failure" ;
VAL_ 219 DCDC12vSupplyStatus 0 "Capable" 1 "Not Capable" ;
VAL_ 219 DCDC12vSupplyStatusCmp 0 "Not Capable" 1 "Capable" ;
VAL_ 219 OverrunBrakeLightReq 0 "no brake light activation" 1 "brake light activation" ;
VAL_ 219 PwrSupSwitchRequest 0 "Request switches for Engine Running" 1 "Request switches for Engine Cranking" ;
VAL_ 219 PwrSupSwitchRequestCmp 0 "Request switches for Engine Cranking" 1 "Request switches for Engine Running" ;
VAL_ 239 AmbientAirPressureQF 0 "The accuracy of the data is undefinable" 1 "Data is temporarily undefinable, evaluation in progress" 2 "The accuracy of the data is not within specification" 3 "The data is calculated with the specified accuracy" ;
VAL_ 239 AmbientTempQF 0 "The accuracy of the data is undefinable" 1 "Data is temporarily undefinable, evaluation in progress" 2 "The accuracy of the data is not within specification" 3 "The data is calculated with the specified accuracy" ;
VAL_ 239 EngineCoolantTempQF 0 "The accuracy of the data is undefinable" 1 "Data is temporarily undefinable, evaluation in progress" 2 "The accuracy of the data is not within specification" 3 "The data is calculated with the specified accuracy" ;
VAL_ 239 EngineOilTempQF 0 "The accuracy of the data is undefinable" 1 "Data is temporarily undefinable, evaluation in progress" 2 "The accuracy of the data is not within specification" 3 "The data is calculated with the specified accuracy" ;
VAL_ 191 CrashAirbagStatus 0 "Both driver airbag and passenger airbag not deployed" 1 "Only driver airbag deployed" 2 "Only passenger airbag deployed" 3 "Both driver & passenger airbags are deployed" ;
VAL_ 191 CrashOccClassStatus 0 "OCS not fitted" 1 "OCS Empty inhibit" 2 "OCS Occupied small inhibit" 3 "OCS Occupied large allow" ;
VAL_ 191 CrashPACOSSwitchState 0 "PACOS not fitted" 1 "PACOS OFF" 2 "PACOS ON" 3 "Unused" ;
VAL_ 191 CrashPretensionerStat 0 "Both driver pretensioner and passenger pretensioner not deployed" 1 "Only driver pretensioner deployed" 2 "Only passenger pretensioner deployed" 3 "Both driver & passenger pretensioners are deployed" ;
VAL_ 191 CrashSeatBeltBcklState 0 "Both Driver & Passenger not belted" 1 "Only driver belted" 2 "Only passenger belted" 3 "Both Driver & Passenger are belted" ;
VAL_ 191 CrashSeverityClass 0 "No frontal event" 1 "Frontal event pretensioner threshold met" 2 "Frontal event stage 1 airbag threshold met" 3 "Frontal event stage 2 airbag threshold met" ;
VAL_ 191 CrashSideAirbagStatus 0 "No Side airbags/curtainairbags deployed" 1 "Left side airbag/curtain deployed" 2 "Right side airbag/curtain deployed" 3 "Both side airbags/curtains deployed" ;
VAL_ 191 CrashStatusPIE 0 "No Pedestrain Crash" 1 "Pedestrain Crash Detected" ;
VAL_ 191 CrashStatusRCM 0 "No crash" 1 "Crash condition" ;
VAL_ 191 CrashTypeFront 0 "No Crash" 1 "Crash" ;
VAL_ 191 CrashTypeRear 0 "No Crash" 1 "Crash" ;
VAL_ 191 CrashTypeRoll 0 "No rollover" 1 "Vehicle rollover" ;
VAL_ 191 CrashTypeSide 0 "No Crash" 1 "Crash" ;
VAL_ 191 DrivSeatBeltBcklError 0 "No Fault" 1 "Fault Condition" ;
VAL_ 191 DrivSeatBeltBcklState 0 "Not Latched" 1 "Latched" ;
VAL_ 191 DrivSeatPositionError 0 "No Fault" 1 "Fault" ;
VAL_ 191 DrivSeatPositionStatus 0 "Rearward (normal / large occupant)" 1 "Forward (small occupant)" ;
VAL_ 191 KeepNetInAfterRunRCM 0 "Function does not need the network" 1 "Function does need the network" ;
VAL_ 191 PassSeatBeltBcklError 0 "No Fault" 1 "Fault Condition" ;
VAL_ 191 PassSeatBeltBcklState 0 "Not Latched" 1 "Latched" ;
VAL_ 191 PassSeatPositionStatus 0 "Rearward (normal / large occupant)" 1 "Forward (small occupant)" ;
VAL_ 191 TriggerEventRCM 0 "No Trigger Event" 1 "Trigger Event Condition" ;
VAL_ 191 VerticalAcceleration 4095 "Fault" ;
VAL_ 738 SBBatCurrFlt 0 "Sensor OK" 1 "Sensor fault" ;
VAL_ 738 SBBatVoltFlt 0 "Sensor OK" 1 "Sensor fault" ;
VAL_ 738 SBCriticErr 0 "No Fault" 1 "Over Voltage Error Level 1" 2 "Over Voltage Error Level 2" 3 "Over Voltage Error Level 3" 4 "Low Voltage Error Level 1" 5 "Low Voltage Error Level 2" 6 "Low Voltage Error Level 3" 7 "High Temperature Error Level" 8 "Over Charge Current Error Level 2" 9 "Over Discharge Current Error Level 2" 10 "Over Discharge Current Error Level 3" 11 "Relay Open (External Short Circuit)" ;
VAL_ 738 SBECUFlt 0 "No Fault" 1 "ECU Fault" ;
VAL_ 738 SBRelayClsFlt 0 "Not failed" 1 "Failed closed" ;
VAL_ 738 SBRelayOpenFlt 0 "Not failed" 1 "Failed open" ;
VAL_ 738 SBRelayStatus 0 "INIT" 1 "CLOSE" 2 "PRE-OPEN" 3 "OPEN" ;
VAL_ 790 SBCell1VoltFlt 0 "Sensor OK" 1 "Sensor fault" ;
VAL_ 790 SBCell2VoltFlt 0 "Sensor OK" 1 "Sensor fault" ;
VAL_ 790 SBCell3VoltFlt 0 "Sensor OK" 1 "Sensor fault" ;
VAL_ 790 SBCell4VoltFlt 0 "Sensor OK" 1 "Sensor fault" ;
VAL_ 791 SBPackVoltFlt 0 "Sensor OK" 1 "Sensor fault" ;
VAL_ 791 SBPos1TempFlt 0 "Sensor OK" 1 "Sensor fault" ;
VAL_ 791 SBPos2TempFlt 0 "Sensor OK" 1 "Sensor fault" ;
VAL_ 387 SB2BatCurrFlt 0 "Sensor OK" 1 "Sensor fault" ;
VAL_ 387 SB2BatVoltFlt 0 "Sensor OK" 1 "Sensor fault" ;
VAL_ 387 SB2CriticErr 0 "No Fault" 1 "Over Voltage Error Level 1" 2 "Over Voltage Error Level 2" 3 "Over Voltage Error Level 3" 4 "Low Voltage Error Level 1" 5 "Low Voltage Error Level 2" 6 "Low Voltage Error Level 3" 7 "High Temperature Error Level" 8 "Over Charge Current Error Level 2" 9 "Over Discharge Current Error Level 2" 10 "Over Discharge Current Error Level 3" 11 "Relay Open (External Short Circuit)" ;
VAL_ 387 SB2ECUFlt 0 "No Fault" 1 "ECU Fault" ;
VAL_ 387 SB2RelayClsFlt 0 "Not failed" 1 "Failed closed" ;
VAL_ 387 SB2RelayOpenFlt 0 "Not failed" 1 "Failed open" ;
VAL_ 387 SB2RelayStatus 0 "INIT" 1 "CLOSE" 2 "PRE-OPEN" 3 "OPEN" ;
VAL_ 840 SB2Cell1VoltFlt 0 "Sensor OK" 1 "Sensor fault" ;
VAL_ 840 SB2Cell2VoltFlt 0 "Sensor OK" 1 "Sensor fault" ;
VAL_ 840 SB2Cell3VoltFlt 0 "Sensor OK" 1 "Sensor fault" ;
VAL_ 840 SB2Cell4VoltFlt 0 "Sensor OK" 1 "Sensor fault" ;
VAL_ 841 SB2PackVoltFlt 0 "Sensor OK" 1 "Sensor fault" ;
VAL_ 841 SB2Pos1TempFlt 0 "Sensor OK" 1 "Sensor fault" ;
VAL_ 841 SB2Pos2TempFlt 0 "Sensor OK" 1 "Sensor fault" ;
VAL_ 174 EMSpeedMHEV 32766 "Initialisation" 32767 "Failure" ;
VAL_ 174 EMSpeedQFMHEV 0 "The accuracy of the data is undefinable" 1 "Data is temporarily undefinable, evaluation in progress" 2 "The accuracy of the data is not within specification" 3 "The data is calculated with the specified accuracy" ;
VAL_ 160 EMOperatingModeExt2 0 "Standby" 1 "Torque Mode" 2 "Speed Mode" 3 "Voltage Mode" 4 "Bus Test Mode" 5 "Not Capable" 6 "Reserved (Calibration Mode)" 7 "Bus Discharge mode" 8 "Life Saver Mode" 9 "Pre-Load Mode" 10 "PreFlux Mode" 11 "Engine Stop Assist - ESA" 12 "Unused" 13 "Failure HV Not Allowed" 14 "Initialisation" 15 "Failure" ;
VAL_ 260 ChargingKeyScanRes 0 "Init/Not Requested" 1 "Not Scanning1" 2 "Not Scanning2" 3 "Not Scanning3" 4 "Key Away" 5 "Key Nearby" 6 "Key Inside" 7 "Key at LH Charge Bowl" 8 "Key at RH Charge Bowl" ;
VAL_ 260 GearPosActual 0 "Neutral/Park" 1 "First" 2 "Second" 3 "Third" 4 "Fourth" 5 "Fifth" 6 "Sixth" 7 "Seventh" 8 "Eighth" 9 "Ninth" 10 "Reserved Position10" 11 "Reserved Position11" 12 "Reverse" 13 "Reserved Position13" 14 "EV Drive" 15 "Shift-In Progress / Fault" ;
VAL_ 260 OBDDriveCycle 0 "Not Complete" 1 "Complete" ;
VAL_ 260 OBDGeneralDenominator 0 "Not Complete" 1 "Complete" ;
VAL_ 260 OBDWarmUpCycle 0 "Not Complete" 1 "Complete" ;
VAL_ 260 PEChargingInletLockCmd 0 "No Request to Unlock Socket" 1 "Request to Unlock Socket" ;
VAL_ 346 ChargeCableUnlockReq 0 "No Request" 1 "Unlock Request" ;
VAL_ 346 ChargeFlapActn 0 "No Request" 1 "Open Left Charge Flap" 2 "Open Right Charge Flap" 3 "Close Left Charge Flap" 4 "Close Right Charge Flap" 5 "Open Left Charge Flap and Right Charge Flap" 6 "Close Laft Charge Flap and Right Charge Flap" ;
VAL_ 346 ChargeFlapActnIVI 0 "No Request" 1 "Open Left Charge Flap" 2 "Open Right Charge Flap" 3 "Close Left Charge Flap" 4 "Close Right Charge Flap" 5 "Open Left Charge Flap and Right Charge Flap" 6 "Close Laft Charge Flap and Right Charge Flap" ;
VAL_ 346 StatusLightConfig 0 "Initialisation" 1 "On when user present" 2 "Always ON" 3 "Off on User Approach" ;
VAL_ 772 CabinCleaningReqTCU 0 "No Request" 1 "Start Cycle" 2 "Stop Cycle" ;
VAL_ 772 CabinCleanPreconStatTCU 0 "No Failures" 1 "Windows/Doors Open/Vehicle not Secured" 2 "Crash Active" 3 "Critical Service Active" 4 "SOTA Active" 5 "Power Mode Invalid" 6 "Battery Budget Failure" 7 "BCM Handshake failure" 8 "Other System Failures" ;
VAL_ 607 ChargeModeAvailableExt 0 "Not available" 1 "Available" ;
VAL_ 607 SOTAPrepRequest 0 "Not required / completed" 1 "Request for SOTA install" 2 "SOTA installation in progress" 3 "SOTA installation in progress- HV system active" ;
VAL_ 785 eCallVoiceCallStatus 0 "eCall_NotActive" 1 "eCall_Automatic" 2 "eCall_Manual" 3 "eCall_Incoming" ;
VAL_ 80 KeepNetInAfterRunTCM 0 "ECU Does not require the Network" 1 "ECU Requires Network Communication" ;
VAL_ 80 ReAlignToNeutral 0 "Not Used1" 1 "Initial Value - No action" 2 "Realign to Neutral" 3 "Not Used2" ;
VAL_ 80 ReAlignToPark 0 "Not Used" 1 "Initial Value - No action" 2 "Realign to Park" 3 "Not Used" ;
VAL_ 80 TCMLockETSReq 0 "Initialisation (Brake Interlock NOT Applicable)" 1 "Brake Interlock Active and Brake Pressed (Brake Unlock)" 2 "Brake Interlock Active and Brake NOT Pressed (Brake Lock)" 3 "Brake Interlock NOT Active" ;
VAL_ 80 TCMLockGSMReq 0 "BSCM Faulty, LMC Veh. NOT Held, LMC Faulty, PARK NOT Available" 1 "BSCM Faulty, LMC Veh. NOT Held, LMC Faulty, PARK Available" 2 "BSCM Faulty, LMC Veh. NOT Held, LMC Healthy, PARK NOT Available" 3 "BSCM Faulty, LMC Veh. NOT Held, LMC Healthy, PARK Available" 4 "BSCM Faulty, LMC Veh. Held, LMC Faulty, PARK NOT Available" 5 "BSCM Faulty, LMC Veh. Held, LMC Faulty, PARK Available" 6 "BSCM Faulty, LMC Veh. Held, LMC Healthy, PARK NOT Available" 7 "BSCM Faulty, LMC Veh. Held, LMC Healthy, PARK Available" 8 "BSCM Healthy, LMC Veh. NOT Held, LMC Faulty, PARK NOT Available" 9 "BSCM Healthy, LMC Veh. NOT Held, LMC Faulty, PARK Available" 10 "BSCM Healthy, LMC Veh. NOT Held, LMC Healthy, PARK NOT Available" 11 "BSCM Healthy, LMC Veh. NOT Held, LMC Healthy, PARK Available" 12 "BSCM Healthy, LMC Veh. Held, LMC Faulty, PARK NOT Available" 13 "BSCM Healthy, LMC Veh. Held, LMC Faulty, PARK Available" 14 "BSCM Healthy, LMC Veh. Held, LMC Healthy, PARK NOT Available" 15 "BSCM Healthy, LMC Veh. Held, LMC Healthy, PARK Available" ;
VAL_ 80 TCMLockGSMReqComp 0 "BSCM Healthy, LMC Veh. Held, LMC Healthy, PARK Available" 1 "BSCM Healthy, LMC Veh. Held, LMC Healthy, PARK NOT Available" 2 "BSCM Healthy, LMC Veh. Held, LMC Faulty, PARK Available" 3 "BSCM Healthy, LMC Veh. Held, LMC Faulty, PARK NOT Available" 4 "BSCM Healthy, LMC Veh. NOT Held, LMC Healthy, PARK Available" 5 "BSCM Healthy, LMC Veh. NOT Held, LMC Healthy, PARK NOT Available" 6 "BSCM Healthy, LMC Veh. NOT Held, LMC Faulty, PARK Available" 7 "BSCM Healthy, LMC Veh. NOT Held, LMC Faulty, PARK NOT Available" 8 "BSCM Faulty, LMC Veh. Held, LMC Healthy, PARK Available" 9 "BSCM Faulty, LMC Veh. Held, LMC Healthy, PARK NOT Available" 10 "BSCM Faulty, LMC Veh. Held, LMC Faulty, PARK Available" 11 "BSCM Faulty, LMC Veh. Held, LMC Faulty, PARK NOT Available" 12 "BSCM Faulty, LMC Veh. NOT Held, LMC Healthy, PARK Available" 13 "BSCM Faulty, LMC Veh. NOT Held, LMC Healthy, PARK NOT Available" 14 "BSCM Faulty, LMC Veh. NOT Held, LMC Faulty, PARK Available" 15 "BSCM Faulty, LMC Veh. NOT Held, LMC Faulty, PARK NOT Available" ;
VAL_ 80 TCMParkReqAck 0 "Initial Value and Value for Position D, R and N." 1 "TCM Park Position Confirmed." 2 "TCM Processing Shift Req into Park" 3 "Fault Condition" ;
VAL_ 80 TCMStartEnable 0 "Transmisson is not in P or N (SbW - TCM does not allow start)" 1 "Transmission is in Neutral, SbW GSM is not in a driving gear an" 2 "Transmission is in Park or SbW EPRC pulled and SbW GSM is not i" 3 "To be interpreted as fault" ;
VAL_ 80 TCMText 0 "ok" 1 "Gearbox Fault" 2 "Gearbox overheating" 3 "Reselect for gear engagement" 4 "Launch Control Ready" 5 "Launch Control Active" 6 "Gearbox Overheating Recommend Low range is selected" 7 "Gearbox overheating. stop safely. Select Low Range" 8 "Dynamic Launch Not Available" 9 "Limited Gears available. Drive with Caution. Service Repair required" 10 "Gearbox Fault. Stop IMMEDIATELY . Vehicle Recovery required" 11 "Manual Shift disabled" 12 "Gearbox Fault. Stop safely. Vehicle Recovery required" 13 "Gearbox Fault. Service Repair required. Limited range available" 14 "Vehicle System fault. Gear Shifting affected. Service Repair required" 15 "Reserved" ;
VAL_ 80 TransTICStatus 0 "TIC Standby" 1 "TIC Active" 2 "TIC Not Active/Deactivating" 3 "TIC Fault" ;
VAL_ 1024 CcfAlternator 0 "Not Supported" 1 "Alternator 150A" 2 "Alternator 180A" 3 "Alternator 220A" 4 "Alternator 120A" 5 "Alternator 150A V" 7 "Alternator 230A HE AJ20D6" 8 "Alternator 90A" 9 "Alternator 110A" 10 "No Alternator Fitted" 11 "Alternator 210A" 12 "Alternator 230A" 13 "Alternator 180A V" 14 "Alternator 250A HE" 15 "Alternator 250A NC10" 16 "Alternator 180A HE" 17 "Alternator 230A HE" 255 "Error" ;
VAL_ 1024 CcfBifuel 0 "Not supported" 1 "Not Bifuel" 2 "Bifuel (LPG)" 3 "Bifuel (CNG)" 255 "Error" ;
VAL_ 1024 CcfDoors 0 "Not supported" 2 "5 Door" 3 "4 Door" 4 "2 Door" 5 "3 Door" 255 "Error" ;
VAL_ 1024 CcfEngine 0 "Not supported" 11 "2.2L DI4 190PS DW12c" 49 "DW12 2.2L I4 DSL 175PS" 69 "I4 2.0L Petrol DISI 200/280" 92 "DW12C I4 2.2L 16V DSL" 119 "Lion TDV8 4.4L (Only for JLR)" 133 "3.6 DOHC V8 TC DIESEL 280 PS" 135 "2.7 V6 24V DOHC EFI T/C DSL" 136 "5.0 OHC SGDI NA V8 GAS AJ133" 137 "5.0 OHC SGDI SC V8 GAS AJ133" 144 "3.0 24V DOHC V6 T/C DSL" 154 "AJ126 V6 S/C 3.0L" 155 "AJ200D OR AJ21-D4 2.0 litre (4 Cylinder)" 156 "AJ200P OR AJ21-P4 2.0 litre (4 Cylinder)" 157 "IEM3 2.0L" 171 "NI4/2.0/4V GTDI 240/340" 176 "3.0 V6 DIESEL FULL ELEC HYBRID ENG" 177 "AJ200D 3.0 litre (6 Cyl.)" 178 "AJ200P 3.0 litre (6 Cyl.)" 179 "AJ200P 1.5 litre (3 Cyl.)" 180 "NC10-P8 V8 4.4L Petrol" 181 "NC11-P8 V8 4.4L MHEV" 253 "No Internal Combustion Engine" 254 "COLOGNE V6" 255 "Error" ;
VAL_ 1024 CcfFuel 0 "Not supported" 1 "Petrol" 2 "Diesel" 3 "Gas/Hybrid" 4 "FLEX FUEL ETHANOL" 5 "ETHANOL FUEL CAPABILITY" 6 "LPG FUEL CAPABILITY" 7 "ELECTRIC POWERED" 255 "Error" ;
VAL_ 1024 CcfTransmissionDriveLn 0 "Not supported" 1 "2 Wheel Drive" 2 "All Wheel Drive (Without disconnect)" 3 "All Wheel Drive (With disconnect)" 4 "No I.C. Engine Driveline fitted" 255 "Error" ;
VAL_ 1024 CcfVehicleType 0 "Not supported" 1 "L663" 2 "L560" 3 "L551" 4 "NOTVALID" 8 "L359" 11 "L405" 12 "L494" 13 "X152" 14 "X151" 15 "X760" 16 "X150" 17 "L538" 18 "L550" 19 "X250" 20 "L319" 21 "L320" 26 "X260" 27 "X761" 28 "L462" 36 "L322" 37 "X351" 39 "X540" 40 "X590" 41 "X161" 42 "X391" 43 "L460" 44 "L461" 45 "L860" 46 "X262" 47 "X393" 48 "X762" 49 "X763" 50 "L392" 51 "L361" 52 "L371" 53 "L591" 54 "L552" 55 "L561" 56 "L571" 57 "X572" 58 "L573" 59 "L465" 60 "L664" 61 "X574" 62 "L575" 63 "X770" 64 "X270" 65 "X162" 66 "L481" 67 "L384" 68 "X900" 69 "X901" 70 "X500" 71 "L383" 255 "Error" ;
VAL_ 1024 CcfAlarm 0 "Not Supported" 1 "Without Alarm" 2 "Alarm" 3 "Alarm No Cat 1 (perimeter anti theft) DO NOT USE AFTER 18MY" 4 "Alarm Cat 1 (Thatcham alarm) DO NOT USE AFTER 18MY" 255 "Error" ;
VAL_ 1024 CcfFuelTankVolume 0 "Not Supported" 1 "Volume 70 Litre" 2 "Volume 80 Litre" 3 "Volume 68 Litre" 4 "Volume 75 Litre" 5 "Volume 72 Litre" 6 "Volume 60 Litre" 7 "Volume 108 Litre" 8 "Volume 42.8 Litre" 9 "Volume 100 Litre" 10 "Volume 150 Litre" 11 "Fuel Tank Small (50L)" 12 "Fuel Tank Medium (55L)" 13 "Fuel Tank Large (62L)" 14 "Fuel Tank X-Large (66L)" 15 "Fuel Tank Flat Floor (for G-Mav 62L)" 16 "Fuel Tank AWD (AWD vehicles 66L)" 255 "Error" ;
VAL_ 1024 CcfGearbox 0 "Not supported" 1 "Manual 6-speed FWD" 2 "Manual 6-speed AWD" 3 "Automatic 6-speed FWD" 4 "Automatic 6-speed AWD" 5 "Continuous variable gearbox CFT23" 6 "Manual 5-speed FWD" 7 "Manual 5-speed FWD" 8 "Powershift, 6-speed, FWD" 9 "6 SPD AUTO TRANS DCPS" 10 "1 SPD AUTO TRANS" 11 "6 SPD AUTO TRANS 6F MID-RANGE (6F35)" 16 "Manual, 6-speed, FWD" 17 "Manual, 5-speed, FWD" 48 "6 SPD MAN TRANS-MT82" 49 "6 SP MAN TRANS-VMT6" 50 "5 SPD MAN TRANS VXT75" 51 "5 SPD MAN TRANS EAO MT75" 52 "Cft26 Cvt Auto Transaxle Zf" 53 "Automatic 6-speed Aisin F21" 54 "CVT Auto Transaxle, FWD" 55 "IB5 ASM 5-Speed Auto Shift Manual Transmission" 56 "FN Auto 4-Speed Automatic Transmission" 57 "FN Auto 5-Speed Automatic Transmission" 64 "G4E Auto 4-Speed Automatic Transmission" 68 "B6, Manual, 6-speed, FWD" 71 "6 SPD AUTO TRANS-HP26(not for Volvo)" 72 "6 SPD AUTO TRANS-HP28(not for Volvo)" 73 "6R80 Gearbox, type" 74 "ZF 8 Speed Automatic Gearbox" 80 "9 Speed Auto Gearbox" 81 "2 Speed Auto Transmission (EDU)" 255 "Error" ;
VAL_ 1024 CcfGearboxType 0 "Not supported" 1 "Manual gearbox" 2 "Automatic gearbox" 3 "Powershift Gearbox" 254 "No Conventional Gearbox Fitted" 255 "Error" ;
VAL_ 1024 CcfHeadlightsType 0 "Not supported" 1 "Halogen lights without adjuster" 2 "Halogen lights with adjuster" 3 "Gas Discharger Lights with auto. adj." 4 "Advanced Front lightning system with auto. adj. / Button controlled / Mech or no tourist light" 5 "AFS123 Front Ligthing System" 6 "Not Currently Used" 7 "EcoLED" 8 "Matrix LED, non-AFS123/non-IHB" 9 "Matrix LED AFS123/non-IHB" 10 "Matrix LED AFS123/IHB" 11 "Pixel LED, non-AFS123/non-IHB" 12 "Pixel LED AFS123/non-IHB" 13 "Pixel LED AFS123/IHB" 255 "Error" ;
VAL_ 1024 CcfSeatMassage 0 "Not supported" 1 "Seat Massage not Fitted" 2 "Front seat 1x1 massage fitted" 3 "Rear seat 1x1 massage fitted" 4 "Front 1x1 and Rear 1x1 seat massage fitted" 5 "Front Seat 3x1 Massage Fitted" 6 "Rear Seat 3x1 Massage Fitted" 7 "Front Seat 5x5 Massage Fitted" 8 "Rear Seat 5x5 Massage Fitted" 9 "Front 3x1 & Rear 1x1 seat massage fitted" 10 "Front 3x1 & Rear 3x1 Seat Massage" 11 "Front 5x5 & Rear 3x1 Seat Massage" 12 "Front 5x5 & Rear 5x5 Seat Massage" 13 "Front 25x5 & Rear 25x5 seat Massage" 14 "Front Massage 25x5 Fitted, No Rear Massage" 15 "Front Massage 20x5, No Rear Massage" 16 "Front Massage 20x5 Fitted, Rear Massage 20x5 Fitted" 17 "No Front Massage, Rear Massage 20x5 Fitted" 18 "No Front Massage, Rear Massage 25x5 Fitted" 255 "Error" ;
VAL_ 1024 CcfSteeringWheelPosn 0 "Not supported" 1 "Left Hand Drive" 2 "Right Hand Drive" 255 "Error" ;
VAL_ 1024 CcfAdditionalHeater 0 "Not supported" 1 "Without fuel fired heater" 2 "Fuel fired heater (FFH)" 3 "Fuel fired parking heater (FFPH)" 4 "Fuel operated heater with timer and add heater function, Petrol" 5 "Park Vent without FFH fitted" 6 "Aux Water Pump Only (NAS Markets)" 255 "Error" ;
VAL_ 1024 CcfCruiseControl 0 "Not supported" 1 "Without cruise control" 2 "Cruise Control" 3 "Adaptive Cruise Control" 4 "Adaptive Cruise Control Stop & Go" 6 "Adaptive Cruise Control Brake Limit 2" 7 "Adaptive Cruise Control Stop & Go, Brake Limit 2" 8 "Adaptive Cruise Control, With ACC To CC Toggling" 9 "Adaptive Cruise Control, Stop&Go, With ACC To CC Toggling" 16 "Adaptive Cruise Control, Brake Limit 2, With ACC To CC Toggling" 17 "Adaptive Cruise Control, Stop & Go, Brake Limit 2, With ACC To CC Toggling" 255 "Error" ;
VAL_ 1024 CcfHeadlightCleaning 0 "Not Supported" 1 "Without headlamp washer" 2 "Headlamp washer" 3 "Headlamp washer & wipers" 4 "Headlamp washer Low flow" 255 "Error" ;
VAL_ 1024 CcfPowerSteeringType 0 "Not supported" 1 "Hydraulic Power Steering, Non Speed Sensitive" 2 "Electro Hydraulic Power Steering" 3 "Hydraulic Power Steering, Speed Sensitive" 4 "Electro Power Steering" 5 "Electro Hydraulic Power Steering, Personalization" 6 "Hydraulic Poweer Steering, Speed Sensitive R-Design" 7 "Electric Power Steering without external angle/torque control , only for JLR" 8 "Electric Power Steering with external angle control , only for JLR" 9 "Electric Power Steering with external torque control only , only for JLR" 10 "Electric Power Steering with external angle and torque control , only for JLR" 11 "Electro Power Steering, Personalization" 255 "Error" ;
VAL_ 1024 CcfPrivateLockingTrunk 0 "Not Supported" 1 "Without private locking trunk" 2 "Private locking trunk" 255 "Error" ;
VAL_ 1024 CcfRainSensor 0 "Not Supported" 1 "Without rain sensor" 2 "Rain sensor" 255 "Error" ;
VAL_ 1024 CcfTripComputer 0 "Not supported" 1 "Without Trip computer" 2 "With Trip computer" 3 "With Trip computer extended with MPH" 4 "With Trip Computer And ECO-scout" 255 "Error" ;
VAL_ 1024 CcfBatteryRear 0 "Not supported" 1 "No Rear Battery" 4 "Twin Battery Not For Volvo" 255 "Error" ;
VAL_ 1024 CcfBlindSpotInfoSystem 0 "Not supported" 1 "Without Blind Spot Information System" 2 "Blind Spot Information System, Camera" 3 "Blind Spot Information System With Radar Direct LED" 4 "Blind Spot Information System With Radar CAN LED" 5 "Blind Spot Information System with Lane Change Merge Aid System Direct LED NOT FOR VOLVO" 6 "Blind Spot Information System with RTD (Rear traffic detection)" 7 "Blind Spot Information System disabled with RTD (Rear traffic detection)" 255 "Error" ;
VAL_ 1024 CcfClimateControlUnit 0 "Not supported" 1 "Electronic Climate Control" 2 "Air Condition" 3 "Automatic Temperature Control" 4 "Without Air Condition" 5 "E C C - High Performance" 6 "E C C - Medium Performance" 7 "E C C - Low Performance" 8 "Single Zone ATC" 9 "Dual Zone ATC" 10 "3 - Zone ATC" 11 "4 - Zone ATC" 12 "Single Zone MTC" 13 "Dual Zone MTC" 14 "3 - Zone MTC" 15 "4 - Zone MTC" 255 "Error" ;
VAL_ 1024 CcfCoupeFilter 0 "Not supported" 1 "Pollen Filter" 2 "Air Quality System" 255 "Error" ;
VAL_ 1024 CcfPanicAlarm 0 "Not supported" 1 "Without Panic alarm" 2 "Panic alarm" 3 "Panic alarm limited" 255 "Error" ;
VAL_ 1024 CcfPPTCHeater 0 "Not supported" 1 "Without PTC heater" 2 "With PTC heater" 255 "Error" ;
VAL_ 1024 CcfRoadFrictionDetection 0 "Not supported" 1 "Without Road Friction Detection System" 2 "Road Friction Detection System" 255 "Error" ;
VAL_ 1024 CcfHeartbeatSensor 0 "Not supported" 1 "Without Heartbeat Sensor" 2 "With Heartbeat Sensor" 3 "With Heartbeat Sensor Limited" 255 "Error" ;
VAL_ 1024 CcfHeatedRearSeat 0 "Not supported" 1 "Without Heated Rear Seat" 2 "Heated Second Row Rear Seats Only" 3 "Heated and Cooled Second Row Rear Seats Only (Pre 14MY)" 4 "Heated and Cooled Second Row Rear Seats 3mode Zoning Only" 5 "Heated Second and Third Row Rear Seats" 6 "Heated and Cooled Second Row and Heated Third Row Rear Seats" 7 "Heated and Cooled Second and Third Row Rear Seats" 255 "Error" ;
VAL_ 1024 CcfInstrumentClusterCal 0 "Not supported" 1 "Parameter file for USA" 2 "Parameter file for ENGLAND" 3 "Parameter file for CANADA" 4 "Parameter file for OVERSEAS" 5 "Parameter file for EUROPE" 255 "Error" ;
VAL_ 1024 CcfInteriorMotionSensor 0 "Not supported" 1 "Without Interior Movement Sensor" 2 "Interior Movement Sensor" 3 "Interior Movement Sensor Preparation" 255 "Error" ;
VAL_ 1024 CcfSpeedLimitation 0 "Not supported" 1 "Speed limit 250 km/h" 2 "Speed limit 190 km/h" 3 "Speed limit 210 km/h" 4 "Speed Limit 90km/h" 5 "Speed Limit 100km/h" 6 "Speed Limit 70mph" 7 "No Speed Limit" 8 "Speed Limit 120km/h" 9 "Speed Limit 241km/h" 10 "Speed Limit 90 mph/145kph" 16 "Speed Limit 87mph" 17 "Speed Limit 82mph" 18 "Speed Limit 230km/h" 19 "Speed limit 60km/h" 20 "Speed limit 165km/h" 21 "Speed limit 170km/h" 22 "Speed limit 175km/h" 255 "Error" ;
VAL_ 1024 CcfSpeedWarningDevice 0 "Not supported" 1 "Without Speed Warning" 2 "With Speed Warning" 3 "With Speed Warning 120Kph Not For Volvo" 255 "Error" ;
VAL_ 1024 CcfWheelBrakesTypeFront 0 "Not supported" 1 "Brake Discs 16" 2 "Brake Discs 17.5 FNR" 3 "Brake Discs 16.5 FNR" 4 "Brake Discs 17" 5 "Brake Disc 18" 6 "Brake Disc 15" 8 "Brake Discs 17 FN3" 9 "Brake Discs 16 FN+" 255 "Error" ;
VAL_ 1024 CcfCallstartOfParkHeat 0 "Not supported" 1 "Not Fitted" 2 "Callstart Of Parking Heater, accessory only (via pager)" 3 "Callstart Of Parking Heater, accessory only (via radio)" 255 "Error" ;
VAL_ 1024 CcfFrontSeatVentilation 0 "Not supported" 1 "Without Ventilated Seat" 2 "Ventilated Seat" 255 "Error" ;
VAL_ 1024 CcfHeatedFrontSeats 0 "Not supported" 1 "Without Heated Front Seats" 2 "Heated Front Seats" 3 "Heated And Cooled Front Seats, Not For Volvo" 4 "Heated And Cooled Front Seats, Volvo, 3 Mode Zoning" 255 "Error" ;
VAL_ 1024 CcfSeatHeatCalibration 0 "Not supported" 1 "Without seat heat" 2 "Lowtemp 28C - Hightemp 35C" 3 "Lowtemp 28C - Hightemp 39C" 4 "Lowtemp 30C - Hightemp 36C" 5 "Lowtemp 30C - Hightemp 37C" 6 "Lowtemp 31C - Hightemp 37C" 7 "Lowtemp 31C - Hightemp 38C" 8 "Lowtemp 32C - Hightemp 38C" 9 "Lowtemp 30C - Hightemp 38C" 16 "Lowtemp 33C - Hightemp 39C" 18 "Lowtemp 34C - Hightemp 40C" 19 "Lowtemp 28C - Hightemp 36C" 20 "Lowtemp 35C - Hightemp 41C" 21 "Lowtemp 28C - Hightemp 37C" 22 "Lowtemp 36C - Hightemp 43C" 24 "Lowtemp 40C - Hightemp 46C" 25 "Low 38, Mid 42 and High 46" 32 "Low 40, Mid 44 and High 53" 33 "Low 39, Mid 43 and High 53" 34 "Low 39, Mid 43 and High 48" 64 "EMA Calibration Type 1" 65 "EMA Calibration Type 2" 66 "EMA Calibration Type 3" 67 "EMA Calibration Type 4" 68 "EMA Calibration Type 5" 69 "EMA Calibration Type 6" 70 "EMA Calibration Type 7" 71 "EMA Calibration Type 8" 72 "EMA Calibration Type 9" 73 "EMA Calibration Type 10" 74 "EMA Calibration Type 11" 75 "EMA Calibration Type 12" 76 "EMA Calibration Type 13" 77 "EMA Calibration Type 14" 78 "EMA Calibration Type 15" 79 "EMA Calibration Type 16" 80 "EMA Calibration Type 17" 81 "EMA Calibration Type 18" 82 "EMA Calibration Type 19" 83 "EMA Calibration Type 20" 84 "EMA Calibration Type 21" 85 "EMA Calibration Type 22" 86 "EMA Calibration Type 23" 87 "EMA Calibration Type 24" 88 "EMA Calibration Type 25" 89 "EMA Calibration Type 26" 90 "EMA Calibration Type 27" 91 "EMA Calibration Type 28" 92 "EMA Calibration Type 29" 93 "EMA Calibration Type 30" 94 "EMA Calibration Type 31" 95 "EMA Calibration Type 32" 96 "EMA Calibration Type 33" 97 "EMA Calibration Type 34" 98 "EMA Calibration Type 35" 99 "EMA Calibration Type 36" 100 "EMA Calibration Type 37" 101 "EMA Calibration Type 38" 102 "EMA Calibration Type 39" 103 "EMA Calibration Type 40" 255 "Error" ;
VAL_ 1024 CcfServiceInt 0 "Not supported" 1 "User Defined Serviceinterval" 2 "Serviceinterval 1 15000 km" 3 "Serviceinterval 2 7500 miles" 4 "Serviceinterval 3 12000 miles" 5 "12000Km / 12-Months" 6 "Serviceinterval 5 5000 km" 7 "10000Km / 12-Months" 8 "Serviceinterval 7 30000 km" 9 "Serviceinterval 8 20000 km" 16 "Serviceinterval 9 18000 miles" 17 "Serviceinterval 10 10000 km" 18 "Serviceinterval 11 9000miles/12months" 19 "Serviceinterval 12 12500 miles" 20 "10000km/6months" 21 "Serviceinterval 14 18000miles/12months/650h" 22 "Serviceinterval 15 15000 miles" 23 "6500Km / 3 Months" 24 "Serviceinterval 17 6500miles/12months/500h" 25 "13000Km/ 6 Months" 27 "26000Km / 12-Months" 32 "Serviceinterval 19 10000km/6months/500h" 33 "Serviceinterval 20 20000km/12months/650h" 34 "Serviceinterval 21 4000 miles/3months" 35 "Serviceinterval 22 6500 km/3months" 36 "Serviceinterval 23 8000 miles/6months" 37 "Serviceinterval 24 13000 km/6months" 38 "Serviceinterval 25 16000 miles/12months" 39 "Serviceinterval 26 26000 km/12months" 40 "Serviceinterval 27 12000km /6 months" 41 "Serviceinterval 28 24000km /12 months" 42 "13000km/12months" 43 "GTDi Chain Wear 10000miles/12months 16100Km / 12 Months" 255 "Error" ;
VAL_ 1024 CcfTelephone 0 "Not supported" 1 "Without Telephone" 2 "Telephone Module" 3 "Telematic System VOLVO ON CALL" 4 "Telematic System VOLVO ON CALL Enhanced" 255 "Error" ;
SIG_GROUP_ 41 EMGenLimitGrp 1 : EMCurDcLinkGenLimit EMGenLimitGrpCounter EMGenLimitGrpCS EMVolDcLinkGenLimit;
SIG_GROUP_ 122 EMMotorLimitGrp 1 : EMCurDcLinkMotorLimit EMMotorLimitGrpCounter EMMotorLimitGrpCS EMVolDcLinkMotorLimit;
SIG_GROUP_ 219 VSCGrp 1 : DCDC12vSupplyStatus DCDC12vSupplyStatusCmp PwrSupSwitchRequest PwrSupSwitchRequestCmp VSCPwrSupAliveCounter;
SIG_GROUP_ 172 EMTorqLimitGpMHEV 1 : EMMaxContTorqueLimitMHEV EMMaxTorqueLimitMHEV EMMinContTorqueLimitMHEV EMMinTorqueLimitMHEV EMTorqLimitGpCounterMHEV EMTorqLimitGpCSMHEV;
SIG_GROUP_ 174 EMTorqSpeedExtGpMHEV 1 : DrvlineDampTorqueDeltaMHEV EMSpeedMHEV EMSpeedQFMHEV EMTorqSpeedExtGpCounterMHEV EMTorqSpeedExtGpCSMHEV EMTorqueExtMHEV;
SIG_GROUP_ 160 EMOpModeMVGp 1 : BISGSpeed EMOperatingModeExt2 EMOpModeMVGpCounter EMOpModeMVGpCS EMVoltageDCLinkMV;
SIG_GROUP_ 260 OBDWarmUpGroup 1 : OBDDriveCycle OBDGeneralDenominator OBDWarmUpCycle;
SIG_GROUP_ 1736 UUDT_1_BECM 1 : UUDTBECMResponse1;
SIG_GROUP_ 1704 UUDT_1_SGCM 1 : UUDTSGCMResponse1;
SIG_GROUP_ 1737 UUDT_2_BECM 1 : UUDTBECMResponse2;
SIG_GROUP_ 1705 UUDT_2_SGCM 1 : UUDTSGCMResponse2;
SIG_GROUP_ 1738 UUDT_3_BECM 1 : UUDTBECMResponse3;
SIG_GROUP_ 1706 UUDT_3_SGCM 1 : UUDTSGCMResponse3;
SIG_GROUP_ 1739 UUDT_4_BECM 1 : UUDTBECMResponse4;
SIG_GROUP_ 1707 UUDT_4_SGCM 1 : UUDTSGCMResponse4;
SIG_GROUP_ 1024 CCFPayload0x01 1 : CcfAlternator CcfBifuel CcfDoors CcfEngine CcfFuel CcfTransmissionDriveLn CcfVehicleType;
SIG_GROUP_ 1024 CCFPayload0x02 1 : CcfAlarm CcfFuelTankVolume CcfGearbox CcfGearboxType CcfHeadlightsType CcfSeatMassage CcfSteeringWheelPosn;
SIG_GROUP_ 1024 CCFPayload0x04 1 : CcfAdditionalHeater CcfCruiseControl CcfHeadlightCleaning CcfPowerSteeringType CcfPrivateLockingTrunk CcfRainSensor CcfTripComputer;
SIG_GROUP_ 1024 CCFPayload0x06 1 : CcfBatteryRear CcfBlindSpotInfoSystem CcfClimateControlUnit CcfCoupeFilter CcfPanicAlarm CcfPPTCHeater CcfRoadFrictionDetection;
SIG_GROUP_ 1024 CCFPayload0x07 1 : CcfHeartbeatSensor CcfHeatedRearSeat CcfInstrumentClusterCal CcfInteriorMotionSensor CcfSpeedLimitation CcfSpeedWarningDevice CcfWheelBrakesTypeFront;
SIG_GROUP_ 1024 CCFPayload0x08 1 : CcfCallstartOfParkHeat CcfFrontSeatVentilation CcfHeatedFrontSeats CcfSeatHeatCalibration CcfServiceInt CcfTelephone CcfTyreCircumference;
SIG_GROUP_ 1024 CCFPayload0x09 1 : CcfBrand CcfFreqRemoteControls CcfHeatedWindscreen CcfHillDescentControl CcfParkingAssistance CcfParkingBrakeType CcfSafetyBeltReminder;
SIG_GROUP_ 1024 CCFPayload0x0A 1 : CcfBodyStyle CcfEmissionStandard CcfGlassType CcfOctaneRating CcfRearAirConditioning CcfRoofTyp CcfTyreDimension;
SIG_GROUP_ 1024 CCFPayload0x0F 1 : Ccf12VoltOutletLuggage CcfELVacuumPumpRrBooster CcfOilLevelSensor CcfParkAssistCamera CcfRollStabilityControl CcfTyrePressureModeSystem CcfWheelBrakesTypeRear;
SIG_GROUP_ 1024 CCFPayload0x15 1 : CcfAudibleMislockFeedback CcfAutoRelocking CcfPowerHeatedMirrors CcfRearGlazing CcfRearWashWipe CcfRoofHeight CcfZonalOppositeDoorRelock;
SIG_GROUP_ 1024 CCFPayload0x16 1 : CcfAccessoryUSBUnit CcfAirQualitySensor CcfConfigurableUnlocking CcfEmissionEvaporationSys CcfExternalAlarmUnitSupply CcfHeadrestsRearFolding CcfHomesafeLighting;
SIG_GROUP_ 1024 CCFPayload0x17 1 : CcfACCompressorType CcfAdaptiveLoadLimiterFnt CcfBluetoothHandsfree CcfOccupantWeightSensor CcfPyroTechSteeringColumn CcfRearBeltDetection CcfTrafficInformation;
SIG_GROUP_ 1024 CCFPayload0x1A 1 : CcfAsthmaAndAllergy CcfDampSensor CcfDoorHandleTechnology CcfNeutralControlAutoGear CcfRPMSpeedController CcfSelfOpeningBootlid CcfShiftIndication;
SIG_GROUP_ 1024 CCFPayload0x1D 1 : CcfClimateZoneUserLayout CcfEcoInfoSystem CcfNightVision CcfReverseGearChime CcfSolarSensor CcfTelematics CcfTelematicsProtection;
SIG_GROUP_ 1024 CCFPayload0x20 1 : CcfAutoSpeedLimiter CcfHeadUpDisplay CcfIGORSystemDescription CcfLanguageRegion CcfSideCamera CcfStopStart CcfTrailerTyrePressMonSys;
SIG_GROUP_ 1024 CCFPayload0x21 1 : Ccf4x4InfoDisplay CcfAdvancedChauffeurFunc CcfAudibleAlarmMode CcfCrashEventDataRec CcfDoorLatchType CcfLowSpdIntEmergBrake CcfModelYear;
SIG_GROUP_ 1024 CCFPayload0x22 1 : CcfActiveRollControl CcfAuxillaryWaterPump CcfConversationAssist CcfNavECORouteExtraUrban CcfNavECORouteUrban CcfPartNumberFormat CcfTrsferBxCntrllrType;
SIG_GROUP_ 1024 CCFPayload0x41 1 : CcfCameraHMIStrategy CcfDeplBatterySystem CcfDriverBuckleSwitch CcfDriverKneeAirbag CcfDriverPassBeltPret CcfDriverSwtchLdLimit CcfEventDataRecorder CcfFntDIFbdkMech CcfInfotainmentType CcfLeftCurtainAirbag CcfLeftRearHeadAbag CcfLeftSideAirbag CcfmPACOS CcfPADLamp CcfPassBuckleSwitch CcfPassOccWghtSensor CcfRightCurtainAirbag CcfRightRearHeadAbag CcfRightSideAirbag CcfRollOverSensing CcfThirdRowChiller CcfTrunkLmpOutput CcfWindowCalibration CcfWindowOpFeedback;
SIG_GROUP_ 1024 CCFPayload0x44 1 : CcfATPC CcfBCMCtrlAmbLitSet CcfBumperType CcfDLNAStatus CcfDriverFrontAirbag CcfDriverPassRetractor CcfDRLMLSInteraction CcfDRLTransInteraction CcfGracenotes CcfLowBeamFdbkMech CcfMainBeamFdbkMech CcfPassFrontAirbag CcfPwrTailProxSenPAM CcfQRBPowerPAM CcfRemoteStartCapable CcfStealthMode CcfTPMSVariant;
SIG_GROUP_ 1024 CCFPayload0x47 1 : CcfCHMSLProfile CcfDrvDrowsyMonDDM CcfExtSyntheticSounder CcfFntDIProfile CcfFntDRLProfile CcfFntPosProfile CcfFntSMProfile CcfFwdCollWarnAEB CcfIntelEmerBrkingCUIEB CcfISLFitment CcfNavBtnFCIM CcfNLIAudioAmp CcfP4UBtnFACP CcfPassAirbagVent CcfPCMEWULine CcfRowTwoSquabRelAct CcfTrajectoryLines;
SIG_GROUP_ 1024 CCFPayload0x48 1 : CcfCDiffType CcfChauPersonalisation CcfConnectInfoStatus CcfDistribPlayback CcfEDTType CcfElecDepTowBar CcfFntOptDiskDrive CcfFuelPumpType CcfGliding CcfICCFitment CcfIntStoreIMC CcfIntStoreISC CcfLaneKeepAssistLKA CcfNGINLIDigRadRecSys CcfNoseLoadMeasure CcfPDCBtnFCIM CcfTCUConnectivity CcfTrailerLightMod CcfTRMFitment;
SIG_GROUP_ 1024 CCFPayload0x49 1 : CcfAirIonizer CcfAutoAccessHeight CcfCameraBtnFCIM CcfClusterAlertGFX CcfDepSideSteps CcfDriverDoorLock CcfDSSOffRoadOperation CcfDualViewBtnFCIM CcfECOmodeText CcfKeyFobTechnology CcfPassDoorLock CcfPedProtectSystem CcfRearExitDetect CcfRestrictSunroofOpen CcfRLPassDoorLock CcfRRPassDoorLock CcfSoftCloseDoors CcfSunGblClTelLock CcfTelLock CcfTelUnlock CcfTrailerLightTest CcfVehicleLocator CcfWalkAwayLocking CcfWinGblClTelLock;
SIG_GROUP_ 1024 CCFPayload0x4F 1 : CcfColmnRetractOpenLoad CcfColmnUpRetractOpenLoad CcfComfortPlus CcfEasyEntExtSetMenu CcfeCallhydrogenStorage CcfeCallotherPropStorage CcfEcoModeButtonFit CcfExtLghtTellTaleCol CcfHeatWasherOpenLoad CcfIgnition1OpenLoad CcfIgnition2OpenLoad CcfIgnition3OpenLoad CcfIgnition4OpenLoad CcfIgnition5OpenLoad CcfIgnition6OpenLoad CcfIgnition7OpenLoad CcfIgnition8OpenLoad CcfIMCFanAssyAuxCooling CcfLampSupplyRightOpenLoad CcfParkAidECUOpenLoad CcfScreenSurroundSwitch;
SIG_GROUP_ 1024 CCFPayload0x53 1 : CcfAutoAccess CcfCoolingFanFitment CcfDriverMemDrSwtchPk CcfEDiffType CcfGenericEngPwrOut CcfHdlampLvlSensPos CcfLRTerrainJGAllRdLaunch CcfPassMemDrSwtchPk CcfPTCruiseFitment CcfRearDriverMemDrSwtchPk CcfRearlampType CcfRearPassMemDrSwtchPk CcfSpdoCalkmhOffset CcfSpdoCalPercentScale CcfSteerWlhlSwtchType CcfTowAssist CcfTPMSCalibration;
SIG_GROUP_ 1024 CCFPayload0x54 1 : CcfActSndDesignPwrlvl CcfDoorBodyStyle CcfDrivenWheels CcfFinalDriveRatioComp CcfNextGenPwrTrnSQ CcfNextGenPwrTrnSQCalNo CcfPanoramicRoof CcfPetrolEMSEmissMkt;
SIG_GROUP_ 1024 CCFPayload0x55 1 : CcfBrakeDiscMaterial CcfBrakeDiscSizeFront CcfBrakeDiscSizeRear CcfElectricFan CcfRearDriverLinSWP CcfRearPassLinSWP CcfServiceInterval CcfSportbrake CcfTyreDynamicRollRad;
SIG_GROUP_ 1024 CCFPayload0x56 1 : CcfEnginePowerOutputkW CcfFuelTimeToService CcfHybridType CcfPDC CcfTyreSizeCorrnFac;
SIG_GROUP_ 1024 CCFPayload0x57 1 : CcfBrakeWarningSymbol CcfChassisDescription CcfConfigDynamicMode CcfGearboxdescription ccfGenericWheelBase CcfPTAODieWaterInSensr CcfReverseGearSelStrat CcfTransmissionSelectr CcfVINPart1;
SIG_GROUP_ 1024 CCFPayload0x58 1 : CcfVINPart2;
SIG_GROUP_ 1024 CCFPayload0x59 1 : CcfFntClusterCableLgth CcfFntDispCableLgth CcfVINPart3;
SIG_GROUP_ 1024 CCFPayload0x5B 1 : CcfAdaptDrvBeam CcfAquaBladeFitted CcfAquaBladeWashDir CcfAutoBlindEnabled CcfAutolightSensorFit CcfBodyStyleSeatLayout CcfCDiffBknHalfShfDet CcfCDiffRangeChgType CcfDriverIDCamera CcfFntAnimatedIndicator CcfGestureBlindFront CcfGrillActiveVanes CcfHeatedWasherJets CcfHeightInputSelection CcfLaserHighBeam CcfMovingWindows CcfPNChargingFunction CcfPNFuelRefill CcfRearAnimatedIndicator CcfSpareWheelCarrier CcfTowing CcfViscousFan CcfWiperMotorModule;
SIG_GROUP_ 1024 CCFPayload0x5C 1 : CcfDieselEMSEmissMkt CcfDriverID CcfDriverIDKeys CcfDriverIDPhones CcfDriverIDSeats CcfEcoDataGallonType CcfFrntLowerDispKeys CcfFrntLowerDispVariant CcfFrntUpperDeployable CcfFrntUpperDispVariant CcfFrontPassengerID CcfNGICamBanStrat CcfNonDepIllumDoorHnd CcfPersonalisation CcfRow2PassengerID CcfRow3PassengerID CcfSmartExitFntDrvDr CcfSmartExitFntPassDoor CcfSmartExitRrDrvDoor CcfSmartExitRrPassDoor CcfTransCalIndex;
SIG_GROUP_ 1024 CCFPayload0x5D 1 : CcfChargingInlet1 CcfChargingInlet2 CcfEMMaxDurEngOff CcfFMMaxFuelAge CcfFntPassWdowSwtchPk CcfFrntDrvWdowSwtchpk CcfMicrophoneType CcfRrDrWdowSwtchPk CcfRrPassWdowSwtchpk CcfSelectStateCharge CcfTelematicsSpkrType CcfTimedChrgFeature CcfWirelessCharger;
SIG_GROUP_ 1024 CCFPayload0x61 1 : CcfActiveExhaustButtonType CcfAFS123 CcfBrakePadTypeFront CcfBrakePadTypeRear CcfElectricDrivePower CcfEMSMktCal CcfHeadlightsVariant CcfHitchAssistTowbar CcfMildHybridType CcfSlcCallList CcfSlcDeviceReminder CcfSlcMediaSource CcfSurroundMode CcfTRUserInputMethod;
SIG_GROUP_ 1024 CCFPayload0x62 1 : CcfAskOnExit CcfBacklightStratSel CcfBodyKitStyle CcfClearExitDetectionSystem CcfDriveAssist CcfDriverHeatedCalfRest CcfDynamicLiteMode CcfEngineNoiseCancel CcfFront23BuckSwitch CcfHeatedDoorArmrest CcfHeatedMapPocket CcfHtdFrntCntreArmrst CcfHtdRearCntreArmrst CcfIntelEmrgBrkingCAEB CcfLowerGloveBox CcfRow3BuckleSwitch CcfSAPServerType CcfSeatTherm2ndRowHMIControl CcfSuspensionType CcfTaskLightingTLMA CcfUpperGloveBox CcfUWBPEPSRANGEADJUSTUSEVSA;
SIG_GROUP_ 1024 CCFPayload0x64 1 : CcfATCMAirSusSwitches CcfATCMATPCSwitch CcfATCMAutoTRMdSwitch CcfATCMDSCOffSwitch CcfATCMEVSwitch CcfATCMHDCSwitch CcfATCMLoRangeSwitch CcfATCMRotarySwitch CcfATCMTA2Switch CcfCamForwardAlert CcfCDMDynamicHandling CcfChgPortFlpInhibit CcfClimateZonalControl CcfDisplay2ndRowBlowerSpeed CcfDisplayFrontBlowerSpeed CcfEHznLongHznImpl CcfELKARE CcfGearRatioSpread CcfRadarForwardAlert CcfRHSWSBusSelection CcfSpoilerSpecialFunc CcfUWBPEPSENDISONLYUSEVSA;
SIG_GROUP_ 1024 CCFPayload0x66 1 : CcfACCAccelProfileSelect CcfACCLeadCarDistDisp CcfACCStopGapSelect CcfAdasDCR CcfAdasLongCRA CcfAdasLongRPC CcfAdasNCapCyclistAEB CcfAdasTJP CcfAutoHold CcfDSMFitment CcfESSCalNo CcfIntMirrorVariant CcfLaneKeepAssistLDW CcfManoeuvLightConfig CcfParkPawlLocation CcfPassHeatedCalfRest CcfPSMFitment CcfR2SMFitment CcfR3SMFitment CcfRghtManoeuvringLgt CcfRLSMFitment CcfRRSMFitment CcfSeatMassHanded;
SIG_GROUP_ 1024 CCFPayload0x6C 1 : CcfABsPartc CcfActvDampingPartc CcfAdaptiveProgMode CcfAHBSystemStatus CcfAutoTRProgMode CcfConfigTRMode CcfCorneringLampFunc CcfDrvlinePartc CcfEDiffPartc CcfEmergencyBrakeIndic CcfEnhancedFiltration CcfEPasPartc CcfHighBeamLights CcfNFSVariant CcfProgrammableCar CcfReplay CcfSlcEVChargeAlerts CcfSplitServiceMessaging CcfTrackProgMode CcfTRFitment CcfTRSwitchType CcfULPMProgMode CcfWadeProgMode CcfWakeupShutDownSeqMenu;
SIG_GROUP_ 1024 CCFPayload0x6E 1 : Ccf3DrAccessRearFeature CcfAHBSensitivtyMenu CcfAuxDrivingLamps CcfBattery1Type CcfBattery2BMS CcfBrakePadWearIndication CcfImmobiliserChannels CcfInteriorReleaseTailgate CcfLightsOnWhenWipers CcfPixelTouristMode CcfPSDBFitted CcfRearFoldFlat CcfRemoteReleaseTailgate CcfTailgateHingeType CcfVIAutoIllumination CcfVICustomisableShortcut CcfVisionInteraction CcfVQMFitted CcfVSMLVehicleHealthWarn CcfVSMOilLevelUnit CcfWirelessDeviceCharger CcfXenonLamps;
SIG_GROUP_ 1024 CCFPayload0x6F 1 : CcfA2BConfigurationNo CcfAutoSSSelectInFCPB CcfDSCSelectInFCPB CcfHDCSelectInFCPB CcfIVIType CcfManovLightFadeTime CcfManovLightRevTime CcfOdoLeadingZero CcfPreCrashSeatBltPretent CcfRemoteWingMirrorFold CcfSpeedoMainScaleUnits CcfSpeedoSecondDisplay CcfTerComSelectInFCPB CcfTerDynSelectInFCPB CcfTerECOSelectInFCPB CcfTripCompInitialUnits;
SIG_GROUP_ 1024 CCFPayload0x70 1 : CcfAllWheelSteer CcfATPCSelectInFCPB CcfClimateHardKey CcfFrontFogFuntionality CcfInstrumentSkin CcfOdometerUnits CcfParkAid CcfPreCrashSeatSquab CcfSpdoSecondDisplayUnit CcfSpeedoRange CcfTachoGaugeVariant CcfTerAutoSelectInFCPB CcfTerGGSSelectInFCPB CcfTerMudSelectInFCPB CcfTerSandSelectInFCPB CcfTripCompFuelEconomy CcfTripCompMetFulEcoUnt CcfVTGlazingRoof;
SIG_GROUP_ 1024 CCFPayload0x71 1 : CcfBattery2Type CcfBSCMFitted CcfConventionalCharging CcfDriveModeDiscStrat CcfDriveModeOrder CcfDriveModeSigSchema CcfEVRangeInfoWithPMZ CcfEVSelectInBlade CcfEVSelectInFCPB CcfFLCVariant CcfLeisureBatt CcfOverspeedSaudi CcfParkAssist CcfSpdoScndDispEnblMenu CcfSpdoScndDispUnitMenu CcfSpecialClock CcfSpeedoMinorScale CcfVIAutoStart;
SIG_GROUP_ 1024 CCFPayload0x72 1 : CcfAirSusSelectInFCPB CcfBacklightDimStratSel CcfCCMVariant CcfCityDrivingPwrSteer CcfDADCModule CcfDynSuspensionType CcfFrontCornerRadars CcfGuidanceBeamCCF CcfHandsOnDetection CcfLoRngSelectInFCPB CcfPredictableAFS CcfRearCornerRadars CcfTA2InputControl CcfTA2SelectInFCPB CcfTelematicsSignIn CcfTerCPSelectInFCPB CcfTerCTSelectInFCPB CcfTerRockSelectInFCPB CcfTerWadeSelectInFCPB;
SIG_GROUP_ 1024 CCFPayload0x73 1 : CcfADASCBV CcfApproachOpenDoors CcfATPCPRO CcfCamWashType CcfeHorizonVariant CcfEngCoolantHotWarn CcfEngCoolantVryHotWarn CcfEVSDCalNo CcfGestureBonnet CcfGestureDoorHandles CcfPowerSideDoors CcfRefrigerantType CcfReverseLightActStra CcfSeeThroughTrailer CcfSideDoorObjectDet CcfVehClearGuidance CcfVertAccelSource;
SIG_GROUP_ 1024 CCFPayload0x75 1 : CcfActiveBrakeDuctVanes CcfDADLInhibitOff CcfEDUDriveline CcfFrntUpperDispMargin CcfFrtAnmSeqWkUpShutDn CcfIVIAPIXClusterComms CcfIVIeSIMProfileType CcfIVIWiFiHotspot CcfLHSWSFvClusterView CcfPM25Market CcfPwrTgateHMIControl CcfRoofControlStrategy CcfUserEEBReserveMgmt;
SIG_GROUP_ 1024 CCFPayload0x76 1 : CcfAnmProjWakeUpShutDn CcfBrakeWarnings CcfHVBatteryCapacity CcfIndirectVentsFitted CcfPreEmpSuspBowWvDmp CcfPreEmpSusPitchDamp CcfPreEmptSusCnrRdEnh CcfPreEmptSusCollMtgn CcfPreEmptSusCrPkAccHt CcfPreEmptSusKrbStrkDt CcfPreEmptSusSpeedLwr CcfRow1SeatBolster CcfRow1SeatCushExt CcfRow1SeatHeadrest CcfRow1SeatLumbar CcfRow1SeatShoulder CcfRow2SeatBolster CcfRow2SeatHeadrest CcfRow2SeatLumbar CcfRow2SeatShoulder CcfRrAnmSeqWkUpShutDn CcfTailgateEventExperience CcfTailgateEventLight;
SIG_GROUP_ 1024 CCFPayload0x77 1 : Ccf4x4iD8Driveline CcfAirSuspUIType CcfAutoStpStrtButtonType CcfCentrSideAirbag CcfDSCSwitchSource CcfIMSCalNo1 CcfIMSCalNo2 CcfIMSType CcfLSPFitment CcfPNLeisureBattstatus CcfPoliceLightsFuncReq CcfPreEmptSusPkgKrbAvd CcfPyroBrake CcfSeatPeripheralCtrl CcfTaskLightingTLMB CcfTaskLightingTLMC CcfTracDSCFitted;
SIG_GROUP_ 1024 CCFPayload0x78 1 : CcfAGMcActrFitment CcfAGMdActrFitment CcfCabinSnapshot CcfCDMHandlingPartc CcfCDMISCSPartc CcfCTRBCSPartc CcfEVBattUsablekWh CcfExpDateFormatSigs CcfFntClimateSeatsSZM CcfHDAdaptDrvBeam CcfItemReminder CcfOCSPFitment CcfPassSeatHeelCatcher CcfPetrolEmissionsHW CcfRemoteDeviceReminder CcfRrClimateSeatsSZM CcfSpecialVehicles CcfSpeedoMarket CcfTEETailgateActuation;
SIG_GROUP_ 1024 CCFPayload0x7A 1 : CcfATPCButtonType CcfAutoBlowerIntensityLvlConfig CcfDDMCalibration CcfDepDoorHandShowMode CcfFntLowerDispHaptic CcfFntUpperDispHaptic CcfPhoneSignalBooster CcfPM25SensorType CcfRearChillerUserControl CcfRSESubscriptionVer CcfSeatSpec CcfSensorSlopeType CcfTailgateCloseLockSwitch CcfTSSecSeatMovement;
SIG_GROUP_ 1024 CCFPayload0x7B 1 : CcfADASAlertSensitivity CcfADASSpdLimOffset CcfAutoHoldType CcfDeployableRSEType CcfEcoDrivingCoachVar CcfEVInletLidSecure CcfFirstRowFridge CcfFogLampLocation CcfFrntLoadSpaceLight CcfPersonalisationStorage CcfPwrSideDrBrakePedalClose CcfRevLampLocation CcfRrClimateAutoSigs CcfRrDILampLocation CcfRrPosLampLocation CcfRrSideDrTwoStgRel CcfStopLampLocation CcfTRDriAdvAirSusRcmndRse;
SIG_GROUP_ 1024 CCFPayload0x7C 1 : CcfASDProgMode CcfAutoBlrIntenstySet CcfBrakeSystemTypeCRB CcfClimateHMIControlStrategy CcfDADLSpeedOptions CcfEVInletLidPosition CcfEVInletLidType CcfEVInletUnlockType CcfGearboxFltWarStrat CcfGSMSOption CcfHealthWellnessActiv CcfINCARTempSensorTyp CcfIPMAWSVarCal CcfMLASoftSwitches CcfPredictvEnrgyOptm CcfSeatbuckleLED CcfSpeechSesDuckBehav CcfTemperatureUnits CcfTRClusterRibbonDir CcfUsrEEBReserveMgmt;
SIG_GROUP_ 1024 CCFPayload0x7D 1 : CcfBrakeDuctType CcfCabinCleaning CcfCamVideoResolution CcfHapticSeatPowertrain CcfHapticSeatsAudio CcfInfoEmerChargePnC CcfInfotainEmerParm20 CcfInfotainEmerParm21 CcfMILActtDrivingCycl CcfOffRoadRideHeight CcfPwrDoorCrankOp CcfRainSensorType CcfRefrigerantLoop CcfSmartProgramWiping CcfSVDynamicMode CcfVibroAcousticTherapy;
SIG_GROUP_ 1024 CCFPayload0x7E 1 : CcfAlcoholIntLKDevice CcfCabinCleanCyclTime CcfCornerSpeedAdapt CcfEnhFiltrationAQI CcfHapticPwrTrnCalNo CcfInfotainEmerParm22 CcfInfotainEmerParm23 CcfInfotainEmerParm24 CcfRefrigerantSnsHVAC CcfSidebarControls CcfSpeedLimitAdapt;
SIG_GROUP_ 1024 CCFPayload0x80 1 : CcfAEBMenu CcfDriverCondMonMenu CcfDrvModeSwitchMsg CcfeTSRFaultInd CcfFLCHeating CcfHDCButtonType CcfHibernatedNav CcfIVILoRngSwitchFit CcfLaneAssistMenu CcfNewSpdLimAudioAlrt CcfOverSpdLimWarnSel CcfReCircSoftBtn CcfSideBarClimate CcfStartupLogo CcfSVShiftLightHysteresis CcfTSRSpdLimDispConv CcfVehicleClassific CcfVolumeSoftKeys;
SIG_GROUP_ 1024 CCFPayload0x81 1 : CcfACOnOffSoftBtn CcfAEBFaultInd CcfAirSUISignalSet CcfAutoClimateSoftBtn CcfChildLckdInCarMiti CcfCTRAirSusPartc CcfDCMFaultInd CcfFrntHtdScrnSoftBtn CcfFrontConnectSocket CcfIFMVoltThreshold CcfInfotainEmerParm29 CcfInfotainEmerParm30 CcfInstClusterLayMenu CcfLaneAssistEmrgMenu CcfLSSFaultInd CcfMaxACSoftBtn CcfMaxDefrostSoftBtn CcfRearHtdScrnSoftBtn CcfRemClimIndication CcfSlopeInfoMode CcfSVDynModeRideHght CcfSVRoofLoadAdvice;
SIG_GROUP_ 1024 CCFPayload0x82 1 : CcfAdasDrvFatigue CcfAdasDrvFatigueMenu CcfAdasDrvMon CcfAndroidPluginBox CcfCabFragBoostSftBtn CcfCabFragCartridges CcfCabFragLockSftBtn CcfCabFragPwrSftBtn CcfCabFragTraySoftBtn CcfFragranceDiffuser CcfFrtWinOneShotUpDn CcfLeftChargingInlet CcfRemClimInhibStrat CcfRightChargingInlet CcfRrWinOneShotUpDn CcfRSEMediaStreaming CcfTerSDSelectInFCPB;
SIG_GROUP_ 1024 CCFPayload0x83 1 : CcfAdasDrvMonMenu CcfAdasRmm CcfAQSSoftButton CcfCabFragBoostTime CcfCabFragIntnstyHMI CcfClimPreconSoftBtn CcfClimRecircSoftBtn CcfCO2SoftButton CcfFrontAutoSoftBtn CcfFrontClimPwrSftBtn CcfFrontElecVentsCtrl CcfFstChgPreCon CcfHeatNowSoftBtn CcfIoniserSoftButton CcfRearAutoSoftBtn CcfRearClimPwrSoftBtn CcfRearComfortLckBtn CcfRearElecVentsCtrl CcfRow2ChillBlowCtrl CcfRow3ChillBlowCtrl CcfRow3ChillerLockBtn CcfRow3chillerPowrBtn CcfSyncSoftBtn CcfVentNowSoftBtn;
SIG_GROUP_ 1024 CCFPayload0x85 1 : CcfACChrgCurrConfig CcfBattery3Type CcfChargingStatusHMI CcfChargingTrblShootr CcfEPDUType CcfEVAppType CcfInletLEDConfig CcfLongLaneChngMrg CcfManoeuvreGuidance CcfMax3PhaseACPwrLmt CcfMaxACCurrLmt CcfPrdctTimeChrgDisp CcfTRMCPartc CcfV1GChrgFeature CcfV2LDisChrgFeature CcfWELMSVariant CcfWiperDisplayTime;
SIG_GROUP_ 1024 CCFPayload0x89 1 : CcfAdasDrvDistraction CcfAdasDrvDstrctnMnu CcfAdasHazardsControl CcfAdasHornControl CcfChargePnC CcfChildLckSoftButton CcfClimAutoDeselect CcfClimDistDeselect CcfEfficientCabWarmup CcfHFEfitment CcfPreCrashSeatMovmnt CcfRearMemoryFitted CcfSeatThrmCntrlrRow1 CcfSeatThrmCntrlrRow2 CcfSeatThrmCntrlrRow3 CcfSlimVents CcfSlimVentsSoftCntrl CcfSSRDataRecorder CcfTSDriverMemory CcfTSPassMemory;
SIG_GROUP_ 1024 CCFPayload0xB0 1 : CcfDD00GlobalRealTime CcfDD02MainECUSupVolts CcfDD06PowerModePKT;
SIG_GROUP_ 1024 CCFPayload0xB1 1 : CcfDD01TotalDistance CcfDD04InCarTemp CcfDD05OutdoorTemp;
